VERSION "dbc-export 1 2025.20.8"

NS_ :

BS_:

BU_: BMS CC CMP CMPD CP DAS DI DIF DIR EPBL EPBR EVSE FC GTW HCML HCMR HVP ICR PCS PM PMF PMR PTC SCCM SDCR TAS UMC VC VCFRONT VCLEFT VCRIGHT VCSEC

BO_ 857 VCSEC_DeviceStatus: 8 VCSEC
 SG_ VCSEC_DeviceStatusIndex M : 0|7@1+ (1,0) [0|127] "" Vector__XXX
 SG_ VCSEC_Device0AuthResponseTime m0 : 7|7@1+ (50,0) [0|6300] "ms" Vector__XXX
 SG_ VCSEC_Device0Impermanent m0 : 14|1@1+ (1,0) [0|1] "" Vector__XXX
 SG_ VCSEC_Device0SELockedDown m0 : 15|1@1+ (1,0) [0|1] "" Vector__XXX
 SG_ VCSEC_Device0Version m0 : 16|16@1+ (1,0) [0|65535] "" Vector__XXX
 SG_ VCSEC_Device0WLEntry m0 : 32|5@1+ (1,0) [0|31] "" Vector__XXX
 SG_ VCSEC_Device0OSVersion m0 : 37|12@1+ (1,0) [0|4095] "" Vector__XXX
 SG_ VCSEC_Device0BatteryLevel m0 : 49|8@1+ (0.015625,0) [0|3.9] "V" Vector__XXX
 SG_ VCSEC_Device0Formfactor m0 : 57|5@1+ (1,0) [0|31] "" Vector__XXX
 SG_ VCSEC_Device0BlacklistStatus m0 : 62|1@1+ (1,0) [0|1] "" Vector__XXX
 SG_ VCSEC_Device0Stationary m0 : 63|1@1+ (1,0) [0|1] "" Vector__XXX
 SG_ VCSEC_Device0Bonded m2 : 8|1@1+ (1,0) [0|1] "" Vector__XXX
 SG_ VCSEC_Device0Role m2 : 9|4@1+ (1,0) [0|15] "" Vector__XXX
 SG_ VCSEC_Device0WhitelistActiveTime m2 : 16|16@1+ (1,0) [0|65535] "mins" Vector__XXX
 SG_ VCSEC_Device0SHA1 m2 : 32|32@1+ (1,0) [0|4294967295] "" Vector__XXX
 SG_ VCSEC_Device0Permissions m3 : 32|32@1+ (1,0) [0|4294967295] "" Vector__XXX
 SG_ VCSEC_Device0ManufacturerHashBit m5 : 8|24@1+ (1,0) [0|16777215] "" Vector__XXX
 SG_ VCSEC_Device0BuildNumberHashBits m5 : 32|32@1+ (1,0) [0|4294967295] "" Vector__XXX
 SG_ VCSEC_Device1AuthResponseTime m6 : 7|7@1+ (50,0) [0|6300] "ms" Vector__XXX
 SG_ VCSEC_Device1Impermanent m6 : 14|1@1+ (1,0) [0|1] "" Vector__XXX
 SG_ VCSEC_Device1SELockedDown m6 : 15|1@1+ (1,0) [0|1] "" Vector__XXX
 SG_ VCSEC_Device1Version m6 : 16|16@1+ (1,0) [0|65535] "" Vector__XXX
 SG_ VCSEC_Device1WLEntry m6 : 32|5@1+ (1,0) [0|31] "" Vector__XXX
 SG_ VCSEC_Device1OSVersion m6 : 37|12@1+ (1,0) [0|4095] "" Vector__XXX
 SG_ VCSEC_Device1BatteryLevel m6 : 49|8@1+ (0.015625,0) [0|3.9] "V" Vector__XXX
 SG_ VCSEC_Device1Formfactor m6 : 57|5@1+ (1,0) [0|31] "" Vector__XXX
 SG_ VCSEC_Device1BlacklistStatus m6 : 62|1@1+ (1,0) [0|1] "" Vector__XXX
 SG_ VCSEC_Device1Stationary m6 : 63|1@1+ (1,0) [0|1] "" Vector__XXX
 SG_ VCSEC_Device1Bonded m8 : 8|1@1+ (1,0) [0|1] "" Vector__XXX
 SG_ VCSEC_Device1Role m8 : 9|4@1+ (1,0) [0|15] "" Vector__XXX
 SG_ VCSEC_Device1WhitelistActiveTime m8 : 16|16@1+ (1,0) [0|65535] "mins" Vector__XXX
 SG_ VCSEC_Device1SHA1 m8 : 32|32@1+ (1,0) [0|4294967295] "" Vector__XXX
 SG_ VCSEC_Device1Permissions m9 : 32|32@1+ (1,0) [0|4294967295] "" Vector__XXX
 SG_ VCSEC_Device1ManufacturerHashBit m11 : 8|24@1+ (1,0) [0|16777215] "" Vector__XXX
 SG_ VCSEC_Device1BuildNumberHashBits m11 : 32|32@1+ (1,0) [0|4294967295] "" Vector__XXX
 SG_ VCSEC_Device2AuthResponseTime m12 : 7|7@1+ (50,0) [0|6300] "ms" Vector__XXX
 SG_ VCSEC_Device2Impermanent m12 : 14|1@1+ (1,0) [0|1] "" Vector__XXX
 SG_ VCSEC_Device2SELockedDown m12 : 15|1@1+ (1,0) [0|1] "" Vector__XXX
 SG_ VCSEC_Device2Version m12 : 16|16@1+ (1,0) [0|65535] "" Vector__XXX
 SG_ VCSEC_Device2WLEntry m12 : 32|5@1+ (1,0) [0|31] "" Vector__XXX
 SG_ VCSEC_Device2OSVersion m12 : 37|12@1+ (1,0) [0|4095] "" Vector__XXX
 SG_ VCSEC_Device2BatteryLevel m12 : 49|8@1+ (0.015625,0) [0|3.9] "V" Vector__XXX
 SG_ VCSEC_Device2Formfactor m12 : 57|5@1+ (1,0) [0|31] "" Vector__XXX
 SG_ VCSEC_Device2BlacklistStatus m12 : 62|1@1+ (1,0) [0|1] "" Vector__XXX
 SG_ VCSEC_Device2Stationary m12 : 63|1@1+ (1,0) [0|1] "" Vector__XXX
 SG_ VCSEC_Device2Bonded m14 : 8|1@1+ (1,0) [0|1] "" Vector__XXX
 SG_ VCSEC_Device2Role m14 : 9|4@1+ (1,0) [0|15] "" Vector__XXX
 SG_ VCSEC_Device2WhitelistActiveTime m14 : 16|16@1+ (1,0) [0|65535] "mins" Vector__XXX
 SG_ VCSEC_Device2SHA1 m14 : 32|32@1+ (1,0) [0|4294967295] "" Vector__XXX
 SG_ VCSEC_Device2Permissions m15 : 32|32@1+ (1,0) [0|4294967295] "" Vector__XXX
 SG_ VCSEC_Device2ManufacturerHashBit m17 : 8|24@1+ (1,0) [0|16777215] "" Vector__XXX
 SG_ VCSEC_Device2BuildNumberHashBits m17 : 32|32@1+ (1,0) [0|4294967295] "" Vector__XXX
 SG_ VCSEC_Device3AuthResponseTime m18 : 7|7@1+ (50,0) [0|6300] "ms" Vector__XXX
 SG_ VCSEC_Device3Impermanent m18 : 14|1@1+ (1,0) [0|1] "" Vector__XXX
 SG_ VCSEC_Device3SELockedDown m18 : 15|1@1+ (1,0) [0|1] "" Vector__XXX
 SG_ VCSEC_Device3Version m18 : 16|16@1+ (1,0) [0|65535] "" Vector__XXX
 SG_ VCSEC_Device3WLEntry m18 : 32|5@1+ (1,0) [0|31] "" Vector__XXX
 SG_ VCSEC_Device3OSVersion m18 : 37|12@1+ (1,0) [0|4095] "" Vector__XXX
 SG_ VCSEC_Device3BatteryLevel m18 : 49|8@1+ (0.015625,0) [0|3.9] "V" Vector__XXX
 SG_ VCSEC_Device3Formfactor m18 : 57|5@1+ (1,0) [0|31] "" Vector__XXX
 SG_ VCSEC_Device3BlacklistStatus m18 : 62|1@1+ (1,0) [0|1] "" Vector__XXX
 SG_ VCSEC_Device3Stationary m18 : 63|1@1+ (1,0) [0|1] "" Vector__XXX
 SG_ VCSEC_Device3Bonded m20 : 8|1@1+ (1,0) [0|1] "" Vector__XXX
 SG_ VCSEC_Device3Role m20 : 9|4@1+ (1,0) [0|15] "" Vector__XXX
 SG_ VCSEC_Device3WhitelistActiveTime m20 : 16|16@1+ (1,0) [0|65535] "mins" Vector__XXX
 SG_ VCSEC_Device3SHA1 m20 : 32|32@1+ (1,0) [0|4294967295] "" Vector__XXX
 SG_ VCSEC_Device3Permissions m21 : 32|32@1+ (1,0) [0|4294967295] "" Vector__XXX
 SG_ VCSEC_Device3ManufacturerHashBit m23 : 8|24@1+ (1,0) [0|16777215] "" Vector__XXX
 SG_ VCSEC_Device3BuildNumberHashBits m23 : 32|32@1+ (1,0) [0|4294967295] "" Vector__XXX
 SG_ VCSEC_Device4AuthResponseTime m24 : 7|7@1+ (50,0) [0|6300] "ms" Vector__XXX
 SG_ VCSEC_Device4Impermanent m24 : 14|1@1+ (1,0) [0|1] "" Vector__XXX
 SG_ VCSEC_Device4SELockedDown m24 : 15|1@1+ (1,0) [0|1] "" Vector__XXX
 SG_ VCSEC_Device4Version m24 : 16|16@1+ (1,0) [0|65535] "" Vector__XXX
 SG_ VCSEC_Device4WLEntry m24 : 32|5@1+ (1,0) [0|31] "" Vector__XXX
 SG_ VCSEC_Device4OSVersion m24 : 37|12@1+ (1,0) [0|4095] "" Vector__XXX
 SG_ VCSEC_Device4BatteryLevel m24 : 49|8@1+ (0.015625,0) [0|3.9] "V" Vector__XXX
 SG_ VCSEC_Device4Formfactor m24 : 57|5@1+ (1,0) [0|31] "" Vector__XXX
 SG_ VCSEC_Device4BlacklistStatus m24 : 62|1@1+ (1,0) [0|1] "" Vector__XXX
 SG_ VCSEC_Device4Stationary m24 : 63|1@1+ (1,0) [0|1] "" Vector__XXX
 SG_ VCSEC_Device4Bonded m26 : 8|1@1+ (1,0) [0|1] "" Vector__XXX
 SG_ VCSEC_Device4Role m26 : 9|4@1+ (1,0) [0|15] "" Vector__XXX
 SG_ VCSEC_Device4WhitelistActiveTime m26 : 16|16@1+ (1,0) [0|65535] "mins" Vector__XXX
 SG_ VCSEC_Device4SHA1 m26 : 32|32@1+ (1,0) [0|4294967295] "" Vector__XXX
 SG_ VCSEC_Device4Permissions m27 : 32|32@1+ (1,0) [0|4294967295] "" Vector__XXX
 SG_ VCSEC_Device4ManufacturerHashBit m29 : 8|24@1+ (1,0) [0|16777215] "" Vector__XXX
 SG_ VCSEC_Device4BuildNumberHashBits m29 : 32|32@1+ (1,0) [0|4294967295] "" Vector__XXX
 SG_ VCSEC_Device5AuthResponseTime m30 : 7|7@1+ (50,0) [0|6300] "ms" Vector__XXX
 SG_ VCSEC_Device5Impermanent m30 : 14|1@1+ (1,0) [0|1] "" Vector__XXX
 SG_ VCSEC_Device5SELockedDown m30 : 15|1@1+ (1,0) [0|1] "" Vector__XXX
 SG_ VCSEC_Device5Version m30 : 16|16@1+ (1,0) [0|65535] "" Vector__XXX
 SG_ VCSEC_Device5WLEntry m30 : 32|5@1+ (1,0) [0|31] "" Vector__XXX
 SG_ VCSEC_Device5OSVersion m30 : 37|12@1+ (1,0) [0|4095] "" Vector__XXX
 SG_ VCSEC_Device5BatteryLevel m30 : 49|8@1+ (0.015625,0) [0|3.9] "V" Vector__XXX
 SG_ VCSEC_Device5Formfactor m30 : 57|5@1+ (1,0) [0|31] "" Vector__XXX
 SG_ VCSEC_Device5BlacklistStatus m30 : 62|1@1+ (1,0) [0|1] "" Vector__XXX
 SG_ VCSEC_Device5Stationary m30 : 63|1@1+ (1,0) [0|1] "" Vector__XXX
 SG_ VCSEC_Device5Bonded m32 : 8|1@1+ (1,0) [0|1] "" Vector__XXX
 SG_ VCSEC_Device5Role m32 : 9|4@1+ (1,0) [0|15] "" Vector__XXX
 SG_ VCSEC_Device5WhitelistActiveTime m32 : 16|16@1+ (1,0) [0|65535] "mins" Vector__XXX
 SG_ VCSEC_Device5SHA1 m32 : 32|32@1+ (1,0) [0|4294967295] "" Vector__XXX
 SG_ VCSEC_Device5Permissions m33 : 32|32@1+ (1,0) [0|4294967295] "" Vector__XXX
 SG_ VCSEC_Device5ManufacturerHashBit m35 : 8|24@1+ (1,0) [0|16777215] "" Vector__XXX
 SG_ VCSEC_Device5BuildNumberHashBits m35 : 32|32@1+ (1,0) [0|4294967295] "" Vector__XXX
 SG_ VCSEC_Device6AuthResponseTime m36 : 7|7@1+ (50,0) [0|6300] "ms" Vector__XXX
 SG_ VCSEC_Device6Impermanent m36 : 14|1@1+ (1,0) [0|1] "" Vector__XXX
 SG_ VCSEC_Device6SELockedDown m36 : 15|1@1+ (1,0) [0|1] "" Vector__XXX
 SG_ VCSEC_Device6Version m36 : 16|16@1+ (1,0) [0|65535] "" Vector__XXX
 SG_ VCSEC_Device6WLEntry m36 : 32|5@1+ (1,0) [0|31] "" Vector__XXX
 SG_ VCSEC_Device6OSVersion m36 : 37|12@1+ (1,0) [0|4095] "" Vector__XXX
 SG_ VCSEC_Device6BatteryLevel m36 : 49|8@1+ (0.015625,0) [0|3.9] "V" Vector__XXX
 SG_ VCSEC_Device6Formfactor m36 : 57|5@1+ (1,0) [0|31] "" Vector__XXX
 SG_ VCSEC_Device6BlacklistStatus m36 : 62|1@1+ (1,0) [0|1] "" Vector__XXX
 SG_ VCSEC_Device6Stationary m36 : 63|1@1+ (1,0) [0|1] "" Vector__XXX
 SG_ VCSEC_Device6Bonded m38 : 8|1@1+ (1,0) [0|1] "" Vector__XXX
 SG_ VCSEC_Device6Role m38 : 9|4@1+ (1,0) [0|15] "" Vector__XXX
 SG_ VCSEC_Device6WhitelistActiveTime m38 : 16|16@1+ (1,0) [0|65535] "mins" Vector__XXX
 SG_ VCSEC_Device6SHA1 m38 : 32|32@1+ (1,0) [0|4294967295] "" Vector__XXX
 SG_ VCSEC_Device6Permissions m39 : 32|32@1+ (1,0) [0|4294967295] "" Vector__XXX
 SG_ VCSEC_Device6ManufacturerHashBit m41 : 8|24@1+ (1,0) [0|16777215] "" Vector__XXX
 SG_ VCSEC_Device6BuildNumberHashBits m41 : 32|32@1+ (1,0) [0|4294967295] "" Vector__XXX
 SG_ VCSEC_Device7AuthResponseTime m42 : 7|7@1+ (50,0) [0|6300] "ms" Vector__XXX
 SG_ VCSEC_Device7Impermanent m42 : 14|1@1+ (1,0) [0|1] "" Vector__XXX
 SG_ VCSEC_Device7SELockedDown m42 : 15|1@1+ (1,0) [0|1] "" Vector__XXX
 SG_ VCSEC_Device7Version m42 : 16|16@1+ (1,0) [0|65535] "" Vector__XXX
 SG_ VCSEC_Device7WLEntry m42 : 32|5@1+ (1,0) [0|31] "" Vector__XXX
 SG_ VCSEC_Device7OSVersion m42 : 37|12@1+ (1,0) [0|4095] "" Vector__XXX
 SG_ VCSEC_Device7BatteryLevel m42 : 49|8@1+ (0.015625,0) [0|3.9] "V" Vector__XXX
 SG_ VCSEC_Device7Formfactor m42 : 57|5@1+ (1,0) [0|31] "" Vector__XXX
 SG_ VCSEC_Device7BlacklistStatus m42 : 62|1@1+ (1,0) [0|1] "" Vector__XXX
 SG_ VCSEC_Device7Stationary m42 : 63|1@1+ (1,0) [0|1] "" Vector__XXX
 SG_ VCSEC_Device7Bonded m44 : 8|1@1+ (1,0) [0|1] "" Vector__XXX
 SG_ VCSEC_Device7Role m44 : 9|4@1+ (1,0) [0|15] "" Vector__XXX
 SG_ VCSEC_Device7WhitelistActiveTime m44 : 16|16@1+ (1,0) [0|65535] "mins" Vector__XXX
 SG_ VCSEC_Device7SHA1 m44 : 32|32@1+ (1,0) [0|4294967295] "" Vector__XXX
 SG_ VCSEC_Device7Permissions m45 : 32|32@1+ (1,0) [0|4294967295] "" Vector__XXX
 SG_ VCSEC_Device7ManufacturerHashBit m47 : 8|24@1+ (1,0) [0|16777215] "" Vector__XXX
 SG_ VCSEC_Device7BuildNumberHashBits m47 : 32|32@1+ (1,0) [0|4294967295] "" Vector__XXX
 SG_ VCSEC_Device8AuthResponseTime m48 : 7|7@1+ (50,0) [0|6300] "ms" Vector__XXX
 SG_ VCSEC_Device8Impermanent m48 : 14|1@1+ (1,0) [0|1] "" Vector__XXX
 SG_ VCSEC_Device8SELockedDown m48 : 15|1@1+ (1,0) [0|1] "" Vector__XXX
 SG_ VCSEC_Device8Version m48 : 16|16@1+ (1,0) [0|65535] "" Vector__XXX
 SG_ VCSEC_Device8WLEntry m48 : 32|5@1+ (1,0) [0|31] "" Vector__XXX
 SG_ VCSEC_Device8OSVersion m48 : 37|12@1+ (1,0) [0|4095] "" Vector__XXX
 SG_ VCSEC_Device8BatteryLevel m48 : 49|8@1+ (0.015625,0) [0|3.9] "V" Vector__XXX
 SG_ VCSEC_Device8Formfactor m48 : 57|5@1+ (1,0) [0|31] "" Vector__XXX
 SG_ VCSEC_Device8BlacklistStatus m48 : 62|1@1+ (1,0) [0|1] "" Vector__XXX
 SG_ VCSEC_Device8Stationary m48 : 63|1@1+ (1,0) [0|1] "" Vector__XXX
 SG_ VCSEC_Device8Bonded m50 : 8|1@1+ (1,0) [0|1] "" Vector__XXX
 SG_ VCSEC_Device8Role m50 : 9|4@1+ (1,0) [0|15] "" Vector__XXX
 SG_ VCSEC_Device8WhitelistActiveTime m50 : 16|16@1+ (1,0) [0|65535] "mins" Vector__XXX
 SG_ VCSEC_Device8SHA1 m50 : 32|32@1+ (1,0) [0|4294967295] "" Vector__XXX
 SG_ VCSEC_Device8Permissions m51 : 32|32@1+ (1,0) [0|4294967295] "" Vector__XXX
 SG_ VCSEC_Device8ManufacturerHashBit m53 : 8|24@1+ (1,0) [0|16777215] "" Vector__XXX
 SG_ VCSEC_Device8BuildNumberHashBits m53 : 32|32@1+ (1,0) [0|4294967295] "" Vector__XXX
 SG_ VCSEC_Device9AuthResponseTime m54 : 7|7@1+ (50,0) [0|6300] "ms" Vector__XXX
 SG_ VCSEC_Device9Impermanent m54 : 14|1@1+ (1,0) [0|1] "" Vector__XXX
 SG_ VCSEC_Device9SELockedDown m54 : 15|1@1+ (1,0) [0|1] "" Vector__XXX
 SG_ VCSEC_Device9Version m54 : 16|16@1+ (1,0) [0|65535] "" Vector__XXX
 SG_ VCSEC_Device9WLEntry m54 : 32|5@1+ (1,0) [0|31] "" Vector__XXX
 SG_ VCSEC_Device9OSVersion m54 : 37|12@1+ (1,0) [0|4095] "" Vector__XXX
 SG_ VCSEC_Device9BatteryLevel m54 : 49|8@1+ (0.015625,0) [0|3.9] "V" Vector__XXX
 SG_ VCSEC_Device9Formfactor m54 : 57|5@1+ (1,0) [0|31] "" Vector__XXX
 SG_ VCSEC_Device9BlacklistStatus m54 : 62|1@1+ (1,0) [0|1] "" Vector__XXX
 SG_ VCSEC_Device9Stationary m54 : 63|1@1+ (1,0) [0|1] "" Vector__XXX
 SG_ VCSEC_Device9Bonded m56 : 8|1@1+ (1,0) [0|1] "" Vector__XXX
 SG_ VCSEC_Device9Role m56 : 9|4@1+ (1,0) [0|15] "" Vector__XXX
 SG_ VCSEC_Device9WhitelistActiveTime m56 : 16|16@1+ (1,0) [0|65535] "mins" Vector__XXX
 SG_ VCSEC_Device9SHA1 m56 : 32|32@1+ (1,0) [0|4294967295] "" Vector__XXX
 SG_ VCSEC_Device9Permissions m57 : 32|32@1+ (1,0) [0|4294967295] "" Vector__XXX
 SG_ VCSEC_Device9ManufacturerHashBit m59 : 8|24@1+ (1,0) [0|16777215] "" Vector__XXX
 SG_ VCSEC_Device9BuildNumberHashBits m59 : 32|32@1+ (1,0) [0|4294967295] "" Vector__XXX
 SG_ VCSEC_Device10AuthResponseTime m60 : 7|7@1+ (50,0) [0|6300] "ms" Vector__XXX
 SG_ VCSEC_Device10Impermanent m60 : 14|1@1+ (1,0) [0|1] "" Vector__XXX
 SG_ VCSEC_Device10SELockedDown m60 : 15|1@1+ (1,0) [0|1] "" Vector__XXX
 SG_ VCSEC_Device10Version m60 : 16|16@1+ (1,0) [0|65535] "" Vector__XXX
 SG_ VCSEC_Device10WLEntry m60 : 32|5@1+ (1,0) [0|31] "" Vector__XXX
 SG_ VCSEC_Device10OSVersion m60 : 37|12@1+ (1,0) [0|4095] "" Vector__XXX
 SG_ VCSEC_Device10BatteryLevel m60 : 49|8@1+ (0.015625,0) [0|3.9] "V" Vector__XXX
 SG_ VCSEC_Device10Formfactor m60 : 57|5@1+ (1,0) [0|31] "" Vector__XXX
 SG_ VCSEC_Device10BlacklistStatus m60 : 62|1@1+ (1,0) [0|1] "" Vector__XXX
 SG_ VCSEC_Device10Stationary m60 : 63|1@1+ (1,0) [0|1] "" Vector__XXX
 SG_ VCSEC_Device10Bonded m62 : 8|1@1+ (1,0) [0|1] "" Vector__XXX
 SG_ VCSEC_Device10Role m62 : 9|4@1+ (1,0) [0|15] "" Vector__XXX
 SG_ VCSEC_Device10WhitelistActiveTim m62 : 16|16@1+ (1,0) [0|65535] "mins" Vector__XXX
 SG_ VCSEC_Device10SHA1 m62 : 32|32@1+ (1,0) [0|4294967295] "" Vector__XXX
 SG_ VCSEC_Device10Permissions m63 : 32|32@1+ (1,0) [0|4294967295] "" Vector__XXX
 SG_ VCSEC_Device10ManufacturerHashBi m65 : 8|24@1+ (1,0) [0|16777215] "" Vector__XXX
 SG_ VCSEC_Device10BuildNumberHashBit m65 : 32|32@1+ (1,0) [0|4294967295] "" Vector__XXX
 SG_ VCSEC_Device11AuthResponseTime m66 : 7|7@1+ (50,0) [0|6300] "ms" Vector__XXX
 SG_ VCSEC_Device11Impermanent m66 : 14|1@1+ (1,0) [0|1] "" Vector__XXX
 SG_ VCSEC_Device11SELockedDown m66 : 15|1@1+ (1,0) [0|1] "" Vector__XXX
 SG_ VCSEC_Device11Version m66 : 16|16@1+ (1,0) [0|65535] "" Vector__XXX
 SG_ VCSEC_Device11WLEntry m66 : 32|5@1+ (1,0) [0|31] "" Vector__XXX
 SG_ VCSEC_Device11OSVersion m66 : 37|12@1+ (1,0) [0|4095] "" Vector__XXX
 SG_ VCSEC_Device11BatteryLevel m66 : 49|8@1+ (0.015625,0) [0|3.9] "V" Vector__XXX
 SG_ VCSEC_Device11Formfactor m66 : 57|5@1+ (1,0) [0|31] "" Vector__XXX
 SG_ VCSEC_Device11BlacklistStatus m66 : 62|1@1+ (1,0) [0|1] "" Vector__XXX
 SG_ VCSEC_Device11Stationary m66 : 63|1@1+ (1,0) [0|1] "" Vector__XXX
 SG_ VCSEC_Device11Bonded m68 : 8|1@1+ (1,0) [0|1] "" Vector__XXX
 SG_ VCSEC_Device11Role m68 : 9|4@1+ (1,0) [0|15] "" Vector__XXX
 SG_ VCSEC_Device11WhitelistActiveTim m68 : 16|16@1+ (1,0) [0|65535] "mins" Vector__XXX
 SG_ VCSEC_Device11SHA1 m68 : 32|32@1+ (1,0) [0|4294967295] "" Vector__XXX
 SG_ VCSEC_Device11Permissions m69 : 32|32@1+ (1,0) [0|4294967295] "" Vector__XXX
 SG_ VCSEC_Device11ManufacturerHashBi m71 : 8|24@1+ (1,0) [0|16777215] "" Vector__XXX
 SG_ VCSEC_Device11BuildNumberHashBit m71 : 32|32@1+ (1,0) [0|4294967295] "" Vector__XXX
 SG_ VCSEC_Device12AuthResponseTime m72 : 7|7@1+ (50,0) [0|6300] "ms" Vector__XXX
 SG_ VCSEC_Device12Impermanent m72 : 14|1@1+ (1,0) [0|1] "" Vector__XXX
 SG_ VCSEC_Device12SELockedDown m72 : 15|1@1+ (1,0) [0|1] "" Vector__XXX
 SG_ VCSEC_Device12Version m72 : 16|16@1+ (1,0) [0|65535] "" Vector__XXX
 SG_ VCSEC_Device12WLEntry m72 : 32|5@1+ (1,0) [0|31] "" Vector__XXX
 SG_ VCSEC_Device12OSVersion m72 : 37|12@1+ (1,0) [0|4095] "" Vector__XXX
 SG_ VCSEC_Device12BatteryLevel m72 : 49|8@1+ (0.015625,0) [0|3.9] "V" Vector__XXX
 SG_ VCSEC_Device12Formfactor m72 : 57|5@1+ (1,0) [0|31] "" Vector__XXX
 SG_ VCSEC_Device12BlacklistStatus m72 : 62|1@1+ (1,0) [0|1] "" Vector__XXX
 SG_ VCSEC_Device12Stationary m72 : 63|1@1+ (1,0) [0|1] "" Vector__XXX
 SG_ VCSEC_Device12Bonded m74 : 8|1@1+ (1,0) [0|1] "" Vector__XXX
 SG_ VCSEC_Device12Role m74 : 9|4@1+ (1,0) [0|15] "" Vector__XXX
 SG_ VCSEC_Device12WhitelistActiveTim m74 : 16|16@1+ (1,0) [0|65535] "mins" Vector__XXX
 SG_ VCSEC_Device12SHA1 m74 : 32|32@1+ (1,0) [0|4294967295] "" Vector__XXX
 SG_ VCSEC_Device12Permissions m75 : 32|32@1+ (1,0) [0|4294967295] "" Vector__XXX
 SG_ VCSEC_Device12ManufacturerHashBi m77 : 8|24@1+ (1,0) [0|16777215] "" Vector__XXX
 SG_ VCSEC_Device12BuildNumberHashBit m77 : 32|32@1+ (1,0) [0|4294967295] "" Vector__XXX
 SG_ VCSEC_Device13AuthResponseTime m78 : 7|7@1+ (50,0) [0|6300] "ms" Vector__XXX
 SG_ VCSEC_Device13Impermanent m78 : 14|1@1+ (1,0) [0|1] "" Vector__XXX
 SG_ VCSEC_Device13SELockedDown m78 : 15|1@1+ (1,0) [0|1] "" Vector__XXX
 SG_ VCSEC_Device13Version m78 : 16|16@1+ (1,0) [0|65535] "" Vector__XXX
 SG_ VCSEC_Device13WLEntry m78 : 32|5@1+ (1,0) [0|31] "" Vector__XXX
 SG_ VCSEC_Device13OSVersion m78 : 37|12@1+ (1,0) [0|4095] "" Vector__XXX
 SG_ VCSEC_Device13BatteryLevel m78 : 49|8@1+ (0.015625,0) [0|3.9] "V" Vector__XXX
 SG_ VCSEC_Device13Formfactor m78 : 57|5@1+ (1,0) [0|31] "" Vector__XXX
 SG_ VCSEC_Device13BlacklistStatus m78 : 62|1@1+ (1,0) [0|1] "" Vector__XXX
 SG_ VCSEC_Device13Stationary m78 : 63|1@1+ (1,0) [0|1] "" Vector__XXX
 SG_ VCSEC_Device13Bonded m80 : 8|1@1+ (1,0) [0|1] "" Vector__XXX
 SG_ VCSEC_Device13Role m80 : 9|4@1+ (1,0) [0|15] "" Vector__XXX
 SG_ VCSEC_Device13WhitelistActiveTim m80 : 16|16@1+ (1,0) [0|65535] "mins" Vector__XXX
 SG_ VCSEC_Device13SHA1 m80 : 32|32@1+ (1,0) [0|4294967295] "" Vector__XXX
 SG_ VCSEC_Device13Permissions m81 : 32|32@1+ (1,0) [0|4294967295] "" Vector__XXX
 SG_ VCSEC_Device13ManufacturerHashBi m83 : 8|24@1+ (1,0) [0|16777215] "" Vector__XXX
 SG_ VCSEC_Device13BuildNumberHashBit m83 : 32|32@1+ (1,0) [0|4294967295] "" Vector__XXX
 SG_ VCSEC_Device14AuthResponseTime m84 : 7|7@1+ (50,0) [0|6300] "ms" Vector__XXX
 SG_ VCSEC_Device14Impermanent m84 : 14|1@1+ (1,0) [0|1] "" Vector__XXX
 SG_ VCSEC_Device14SELockedDown m84 : 15|1@1+ (1,0) [0|1] "" Vector__XXX
 SG_ VCSEC_Device14Version m84 : 16|16@1+ (1,0) [0|65535] "" Vector__XXX
 SG_ VCSEC_Device14WLEntry m84 : 32|5@1+ (1,0) [0|31] "" Vector__XXX
 SG_ VCSEC_Device14OSVersion m84 : 37|12@1+ (1,0) [0|4095] "" Vector__XXX
 SG_ VCSEC_Device14BatteryLevel m84 : 49|8@1+ (0.015625,0) [0|3.9] "V" Vector__XXX
 SG_ VCSEC_Device14Formfactor m84 : 57|5@1+ (1,0) [0|31] "" Vector__XXX
 SG_ VCSEC_Device14BlacklistStatus m84 : 62|1@1+ (1,0) [0|1] "" Vector__XXX
 SG_ VCSEC_Device14Stationary m84 : 63|1@1+ (1,0) [0|1] "" Vector__XXX
 SG_ VCSEC_Device14Bonded m86 : 8|1@1+ (1,0) [0|1] "" Vector__XXX
 SG_ VCSEC_Device14Role m86 : 9|4@1+ (1,0) [0|15] "" Vector__XXX
 SG_ VCSEC_Device14WhitelistActiveTim m86 : 16|16@1+ (1,0) [0|65535] "mins" Vector__XXX
 SG_ VCSEC_Device14SHA1 m86 : 32|32@1+ (1,0) [0|4294967295] "" Vector__XXX
 SG_ VCSEC_Device14Permissions m87 : 32|32@1+ (1,0) [0|4294967295] "" Vector__XXX
 SG_ VCSEC_Device14ManufacturerHashBi m89 : 8|24@1+ (1,0) [0|16777215] "" Vector__XXX
 SG_ VCSEC_Device14BuildNumberHashBit m89 : 32|32@1+ (1,0) [0|4294967295] "" Vector__XXX
 SG_ VCSEC_Device15AuthResponseTime m90 : 7|7@1+ (50,0) [0|6300] "ms" Vector__XXX
 SG_ VCSEC_Device15Impermanent m90 : 14|1@1+ (1,0) [0|1] "" Vector__XXX
 SG_ VCSEC_Device15SELockedDown m90 : 15|1@1+ (1,0) [0|1] "" Vector__XXX
 SG_ VCSEC_Device15Version m90 : 16|16@1+ (1,0) [0|65535] "" Vector__XXX
 SG_ VCSEC_Device15WLEntry m90 : 32|5@1+ (1,0) [0|31] "" Vector__XXX
 SG_ VCSEC_Device15OSVersion m90 : 37|12@1+ (1,0) [0|4095] "" Vector__XXX
 SG_ VCSEC_Device15BatteryLevel m90 : 49|8@1+ (0.015625,0) [0|3.9] "V" Vector__XXX
 SG_ VCSEC_Device15Formfactor m90 : 57|5@1+ (1,0) [0|31] "" Vector__XXX
 SG_ VCSEC_Device15BlacklistStatus m90 : 62|1@1+ (1,0) [0|1] "" Vector__XXX
 SG_ VCSEC_Device15Stationary m90 : 63|1@1+ (1,0) [0|1] "" Vector__XXX
 SG_ VCSEC_Device15Bonded m92 : 8|1@1+ (1,0) [0|1] "" Vector__XXX
 SG_ VCSEC_Device15Role m92 : 9|4@1+ (1,0) [0|15] "" Vector__XXX
 SG_ VCSEC_Device15WhitelistActiveTim m92 : 16|16@1+ (1,0) [0|65535] "mins" Vector__XXX
 SG_ VCSEC_Device15SHA1 m92 : 32|32@1+ (1,0) [0|4294967295] "" Vector__XXX
 SG_ VCSEC_Device15Permissions m93 : 32|32@1+ (1,0) [0|4294967295] "" Vector__XXX
 SG_ VCSEC_Device15ManufacturerHashBi m95 : 8|24@1+ (1,0) [0|16777215] "" Vector__XXX
 SG_ VCSEC_Device15BuildNumberHashBit m95 : 32|32@1+ (1,0) [0|4294967295] "" Vector__XXX
 SG_ VCSEC_Device16AuthResponseTime m96 : 7|7@1+ (50,0) [0|6300] "ms" Vector__XXX
 SG_ VCSEC_Device16Impermanent m96 : 14|1@1+ (1,0) [0|1] "" Vector__XXX
 SG_ VCSEC_Device16SELockedDown m96 : 15|1@1+ (1,0) [0|1] "" Vector__XXX
 SG_ VCSEC_Device16Version m96 : 16|16@1+ (1,0) [0|65535] "" Vector__XXX
 SG_ VCSEC_Device16WLEntry m96 : 32|5@1+ (1,0) [0|31] "" Vector__XXX
 SG_ VCSEC_Device16OSVersion m96 : 37|12@1+ (1,0) [0|4095] "" Vector__XXX
 SG_ VCSEC_Device16BatteryLevel m96 : 49|8@1+ (0.015625,0) [0|3.9] "V" Vector__XXX
 SG_ VCSEC_Device16Formfactor m96 : 57|5@1+ (1,0) [0|31] "" Vector__XXX
 SG_ VCSEC_Device16BlacklistStatus m96 : 62|1@1+ (1,0) [0|1] "" Vector__XXX
 SG_ VCSEC_Device16Stationary m96 : 63|1@1+ (1,0) [0|1] "" Vector__XXX
 SG_ VCSEC_Device16Bonded m98 : 8|1@1+ (1,0) [0|1] "" Vector__XXX
 SG_ VCSEC_Device16Role m98 : 9|4@1+ (1,0) [0|15] "" Vector__XXX
 SG_ VCSEC_Device16WhitelistActiveTim m98 : 16|16@1+ (1,0) [0|65535] "mins" Vector__XXX
 SG_ VCSEC_Device16SHA1 m98 : 32|32@1+ (1,0) [0|4294967295] "" Vector__XXX
 SG_ VCSEC_Device16Permissions m99 : 32|32@1+ (1,0) [0|4294967295] "" Vector__XXX
 SG_ VCSEC_Device16ManufacturerHashBi m101 : 8|24@1+ (1,0) [0|16777215] "" Vector__XXX
 SG_ VCSEC_Device16BuildNumberHashBit m101 : 32|32@1+ (1,0) [0|4294967295] "" Vector__XXX
 SG_ VCSEC_Device17AuthResponseTime m102 : 7|7@1+ (50,0) [0|6300] "ms" Vector__XXX
 SG_ VCSEC_Device17Impermanent m102 : 14|1@1+ (1,0) [0|1] "" Vector__XXX
 SG_ VCSEC_Device17SELockedDown m102 : 15|1@1+ (1,0) [0|1] "" Vector__XXX
 SG_ VCSEC_Device17Version m102 : 16|16@1+ (1,0) [0|65535] "" Vector__XXX
 SG_ VCSEC_Device17WLEntry m102 : 32|5@1+ (1,0) [0|31] "" Vector__XXX
 SG_ VCSEC_Device17OSVersion m102 : 37|12@1+ (1,0) [0|4095] "" Vector__XXX
 SG_ VCSEC_Device17BatteryLevel m102 : 49|8@1+ (0.015625,0) [0|3.9] "V" Vector__XXX
 SG_ VCSEC_Device17Formfactor m102 : 57|5@1+ (1,0) [0|31] "" Vector__XXX
 SG_ VCSEC_Device17BlacklistStatus m102 : 62|1@1+ (1,0) [0|1] "" Vector__XXX
 SG_ VCSEC_Device17Stationary m102 : 63|1@1+ (1,0) [0|1] "" Vector__XXX
 SG_ VCSEC_Device17Bonded m104 : 8|1@1+ (1,0) [0|1] "" Vector__XXX
 SG_ VCSEC_Device17Role m104 : 9|4@1+ (1,0) [0|15] "" Vector__XXX
 SG_ VCSEC_Device17WhitelistActiveTim m104 : 16|16@1+ (1,0) [0|65535] "mins" Vector__XXX
 SG_ VCSEC_Device17SHA1 m104 : 32|32@1+ (1,0) [0|4294967295] "" Vector__XXX
 SG_ VCSEC_Device17Permissions m105 : 32|32@1+ (1,0) [0|4294967295] "" Vector__XXX
 SG_ VCSEC_Device17ManufacturerHashBi m107 : 8|24@1+ (1,0) [0|16777215] "" Vector__XXX
 SG_ VCSEC_Device17BuildNumberHashBit m107 : 32|32@1+ (1,0) [0|4294967295] "" Vector__XXX
 SG_ VCSEC_Device18AuthResponseTime m108 : 7|7@1+ (50,0) [0|6300] "ms" Vector__XXX
 SG_ VCSEC_Device18Impermanent m108 : 14|1@1+ (1,0) [0|1] "" Vector__XXX
 SG_ VCSEC_Device18SELockedDown m108 : 15|1@1+ (1,0) [0|1] "" Vector__XXX
 SG_ VCSEC_Device18Version m108 : 16|16@1+ (1,0) [0|65535] "" Vector__XXX
 SG_ VCSEC_Device18WLEntry m108 : 32|5@1+ (1,0) [0|31] "" Vector__XXX
 SG_ VCSEC_Device18OSVersion m108 : 37|12@1+ (1,0) [0|4095] "" Vector__XXX
 SG_ VCSEC_Device18BatteryLevel m108 : 49|8@1+ (0.015625,0) [0|3.9] "V" Vector__XXX
 SG_ VCSEC_Device18Formfactor m108 : 57|5@1+ (1,0) [0|31] "" Vector__XXX
 SG_ VCSEC_Device18BlacklistStatus m108 : 62|1@1+ (1,0) [0|1] "" Vector__XXX
 SG_ VCSEC_Device18Stationary m108 : 63|1@1+ (1,0) [0|1] "" Vector__XXX
 SG_ VCSEC_Device18Bonded m110 : 8|1@1+ (1,0) [0|1] "" Vector__XXX
 SG_ VCSEC_Device18Role m110 : 9|4@1+ (1,0) [0|15] "" Vector__XXX
 SG_ VCSEC_Device18WhitelistActiveTim m110 : 16|16@1+ (1,0) [0|65535] "mins" Vector__XXX
 SG_ VCSEC_Device18SHA1 m110 : 32|32@1+ (1,0) [0|4294967295] "" Vector__XXX
 SG_ VCSEC_Device18Permissions m111 : 32|32@1+ (1,0) [0|4294967295] "" Vector__XXX
 SG_ VCSEC_Device18ManufacturerHashBi m113 : 8|24@1+ (1,0) [0|16777215] "" Vector__XXX
 SG_ VCSEC_Device18BuildNumberHashBit m113 : 32|32@1+ (1,0) [0|4294967295] "" Vector__XXX
 SG_ VCSEC_Device19AuthResponseTime m114 : 7|7@1+ (50,0) [0|6300] "ms" Vector__XXX
 SG_ VCSEC_Device19Impermanent m114 : 14|1@1+ (1,0) [0|1] "" Vector__XXX
 SG_ VCSEC_Device19SELockedDown m114 : 15|1@1+ (1,0) [0|1] "" Vector__XXX
 SG_ VCSEC_Device19Version m114 : 16|16@1+ (1,0) [0|65535] "" Vector__XXX
 SG_ VCSEC_Device19WLEntry m114 : 32|5@1+ (1,0) [0|31] "" Vector__XXX
 SG_ VCSEC_Device19OSVersion m114 : 37|12@1+ (1,0) [0|4095] "" Vector__XXX
 SG_ VCSEC_Device19BatteryLevel m114 : 49|8@1+ (0.015625,0) [0|3.9] "V" Vector__XXX
 SG_ VCSEC_Device19Formfactor m114 : 57|5@1+ (1,0) [0|31] "" Vector__XXX
 SG_ VCSEC_Device19BlacklistStatus m114 : 62|1@1+ (1,0) [0|1] "" Vector__XXX
 SG_ VCSEC_Device19Stationary m114 : 63|1@1+ (1,0) [0|1] "" Vector__XXX
 SG_ VCSEC_Device19Bonded m116 : 8|1@1+ (1,0) [0|1] "" Vector__XXX
 SG_ VCSEC_Device19Role m116 : 9|4@1+ (1,0) [0|15] "" Vector__XXX
 SG_ VCSEC_Device19WhitelistActiveTim m116 : 16|16@1+ (1,0) [0|65535] "mins" Vector__XXX
 SG_ VCSEC_Device19SHA1 m116 : 32|32@1+ (1,0) [0|4294967295] "" Vector__XXX
 SG_ VCSEC_Device19Permissions m117 : 32|32@1+ (1,0) [0|4294967295] "" Vector__XXX
 SG_ VCSEC_Device19ManufacturerHashBi m119 : 8|24@1+ (1,0) [0|16777215] "" Vector__XXX
 SG_ VCSEC_Device19BuildNumberHashBit m119 : 32|32@1+ (1,0) [0|4294967295] "" Vector__XXX

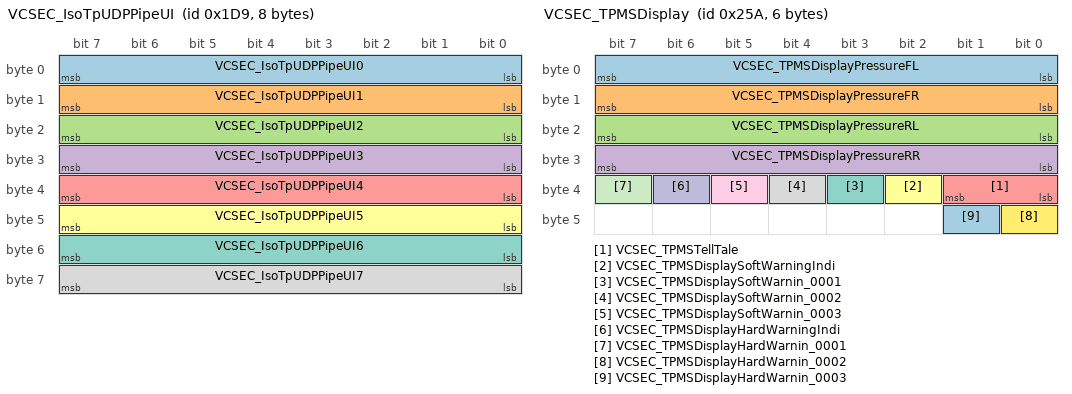
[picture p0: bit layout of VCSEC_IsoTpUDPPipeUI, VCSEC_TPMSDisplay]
BO_ 473 VCSEC_IsoTpUDPPipeUI: 8 VCSEC
 SG_ VCSEC_IsoTpUDPPipeUI0 : 0|8@1+ (1,0) [0|255] "" Vector__XXX
 SG_ VCSEC_IsoTpUDPPipeUI1 : 8|8@1+ (1,0) [0|255] "" Vector__XXX
 SG_ VCSEC_IsoTpUDPPipeUI2 : 16|8@1+ (1,0) [0|255] "" Vector__XXX
 SG_ VCSEC_IsoTpUDPPipeUI3 : 24|8@1+ (1,0) [0|255] "" Vector__XXX
 SG_ VCSEC_IsoTpUDPPipeUI4 : 32|8@1+ (1,0) [0|255] "" Vector__XXX
 SG_ VCSEC_IsoTpUDPPipeUI5 : 40|8@1+ (1,0) [0|255] "" Vector__XXX
 SG_ VCSEC_IsoTpUDPPipeUI6 : 48|8@1+ (1,0) [0|255] "" Vector__XXX
 SG_ VCSEC_IsoTpUDPPipeUI7 : 56|8@1+ (1,0) [0|255] "" Vector__XXX

BO_ 1066 VCSEC_TPMSConnectionData: 8 VCSEC
 SG_ VCSEC_TPMSSensorState0 : 0|3@1+ (1,0) [0|7] "" Vector__XXX
 SG_ VCSEC_TPMSRSSI0 : 3|7@1+ (1,-127) [-127|0] "dBm" Vector__XXX
 SG_ VCSEC_TPMSConnectionTypeCurrent0 : 10|2@1+ (1,0) [0|3] "" Vector__XXX
 SG_ VCSEC_TPMSConnectionTypeDesired0 : 12|2@1+ (1,0) [0|3] "" Vector__XXX
 SG_ VCSEC_TPMSSensorState1 : 14|3@1+ (1,0) [0|7] "" Vector__XXX
 SG_ VCSEC_TPMSRSSI1 : 17|7@1+ (1,-127) [-127|0] "dBm" Vector__XXX
 SG_ VCSEC_TPMSConnectionTypeCurrent1 : 24|2@1+ (1,0) [0|3] "" Vector__XXX
 SG_ VCSEC_TPMSConnectionTypeDesired1 : 26|2@1+ (1,0) [0|3] "" Vector__XXX
 SG_ VCSEC_TPMSSensorState2 : 28|3@1+ (1,0) [0|7] "" Vector__XXX
 SG_ VCSEC_TPMSRSSI2 : 31|7@1+ (1,-127) [-127|0] "dBm" Vector__XXX
 SG_ VCSEC_TPMSConnectionTypeCurrent2 : 38|2@1+ (1,0) [0|3] "" Vector__XXX
 SG_ VCSEC_TPMSConnectionTypeDesired2 : 40|2@1+ (1,0) [0|3] "" Vector__XXX
 SG_ VCSEC_TPMSSensorState3 : 42|3@1+ (1,0) [0|7] "" Vector__XXX
 SG_ VCSEC_TPMSRSSI3 : 45|7@1+ (1,-127) [-127|0] "dBm" Vector__XXX
 SG_ VCSEC_TPMSConnectionTypeCurrent3 : 52|2@1+ (1,0) [0|3] "" Vector__XXX
 SG_ VCSEC_TPMSConnectionTypeDesired3 : 54|2@1+ (1,0) [0|3] "" Vector__XXX
 SG_ VCSEC_TPMSSensorPresence0 : 56|2@1+ (1,0) [0|3] "" Vector__XXX
 SG_ VCSEC_TPMSSensorPresence1 : 58|2@1+ (1,0) [0|3] "" Vector__XXX
 SG_ VCSEC_TPMSSensorPresence2 : 60|2@1+ (1,0) [0|3] "" Vector__XXX
 SG_ VCSEC_TPMSSensorPresence3 : 62|2@1+ (1,0) [0|3] "" Vector__XXX

BO_ 602 VCSEC_TPMSDisplay: 6 VCSEC
 SG_ VCSEC_TPMSDisplayPressureFL : 0|8@1+ (0.025,0) [0|6.35] "bar" Vector__XXX
 SG_ VCSEC_TPMSDisplayPressureFR : 8|8@1+ (0.025,0) [0|6.35] "bar" Vector__XXX
 SG_ VCSEC_TPMSDisplayPressureRL : 16|8@1+ (0.025,0) [0|6.35] "bar" Vector__XXX
 SG_ VCSEC_TPMSDisplayPressureRR : 24|8@1+ (0.025,0) [0|6.35] "bar" Vector__XXX
 SG_ VCSEC_TPMSTellTale : 32|2@1+ (1,0) [0|3] "" Vector__XXX
 SG_ VCSEC_TPMSDisplaySoftWarningIndi : 34|1@1+ (1,0) [0|1] "" Vector__XXX
 SG_ VCSEC_TPMSDisplaySoftWarnin_0001 : 35|1@1+ (1,0) [0|1] "" Vector__XXX
 SG_ VCSEC_TPMSDisplaySoftWarnin_0002 : 36|1@1+ (1,0) [0|1] "" Vector__XXX
 SG_ VCSEC_TPMSDisplaySoftWarnin_0003 : 37|1@1+ (1,0) [0|1] "" Vector__XXX
 SG_ VCSEC_TPMSDisplayHardWarningIndi : 38|1@1+ (1,0) [0|1] "" Vector__XXX
 SG_ VCSEC_TPMSDisplayHardWarnin_0001 : 39|1@1+ (1,0) [0|1] "" Vector__XXX
 SG_ VCSEC_TPMSDisplayHardWarnin_0002 : 40|1@1+ (1,0) [0|1] "" Vector__XXX
 SG_ VCSEC_TPMSDisplayHardWarnin_0003 : 41|1@1+ (1,0) [0|1] "" Vector__XXX

BO_ 825 VCSEC_authentication: 8 VCSEC
 SG_ VCSEC_BLEConnectionCounter : 0|4@1+ (1,0) [0|15] "" Vector__XXX
 SG_ VCSEC_authRejectionReason : 4|3@1+ (1,0) [0|7] "" Vector__XXX
 SG_ VCSEC_IDRequested : 7|1@1+ (1,0) [0|1] "" Vector__XXX
 SG_ VCSEC_operationMode : 8|2@1+ (1,0) [0|3] "" Vector__XXX
 SG_ VCSEC_vehicleLockStatus : 12|4@1+ (1,0) [1|15] "" Vector__XXX
 SG_ VCSEC_authenticationStatus : 16|2@1+ (1,0) [0|3] "" Vector__XXX
 SG_ VCSEC_chargePortLockStatus : 18|1@1+ (1,0) [0|1] "" Vector__XXX
 SG_ VCSEC_leftFrontLockStatus : 19|1@1+ (1,0) [0|1] "" Vector__XXX
 SG_ VCSEC_leftRearLockStatus : 20|1@1+ (1,0) [0|1] "" Vector__XXX
 SG_ VCSEC_rightFrontLockStatus : 21|1@1+ (1,0) [0|1] "" Vector__XXX
 SG_ VCSEC_rightRearLockStatus : 22|1@1+ (1,0) [0|1] "" Vector__XXX
 SG_ VCSEC_trunkLockStatus : 23|1@1+ (1,0) [0|1] "" Vector__XXX
 SG_ VCSEC_lockRequestType : 24|5@1+ (1,0) [0|31] "" Vector__XXX
 SG_ VCSEC_summonRequest : 29|3@1+ (1,0) [0|7] "" Vector__XXX
 SG_ VCSEC_3rdPartyPLGRequest : 32|2@1+ (1,0) [0|2] "" Vector__XXX
 SG_ VCSEC_3rdPartyFrunkPLGRequest : 34|2@1+ (1,0) [0|2] "" Vector__XXX
 SG_ VCSEC_MCUCommandType : 36|3@1+ (1,0) [0|7] "" Vector__XXX
 SG_ VCSEC_frunkLockStatus : 39|1@1+ (1,0) [0|1] "" Vector__XXX
 SG_ VCSEC_usingModifiedMACAddress : 40|1@1+ (1,0) [0|1] "" Vector__XXX
 SG_ VCSEC_isKeyWithinSummonRange : 41|1@1+ (1,0) [0|1] "" Vector__XXX
 SG_ VCSEC_isBLEDeviceWithinSummonRan : 42|1@1+ (1,0) [0|1] "" Vector__XXX
 SG_ VCSEC_alarmStatus : 43|4@1+ (1,0) [0|14] "" Vector__XXX
 SG_ VCSEC_serviceDiagnosticRequest : 47|1@1+ (1,0) [0|1] "" Vector__XXX
 SG_ VCSEC_immobilizerState : 48|3@1+ (1,0) [0|7] "" Vector__XXX
 SG_ VCSEC_lockIndicationRequest : 51|3@1+ (1,0) [1|7] "" Vector__XXX
 SG_ VCSEC_simpleLockStatus : 54|2@1+ (1,0) [1|3] "" Vector__XXX
 SG_ VCSEC_keyChannelIndexed : 56|4@1+ (1,0) [0|14] "" Vector__XXX
 SG_ VCSEC_authRequested : 60|1@1+ (1,0) [0|1] "" Vector__XXX
 SG_ VCSEC_remoteStartActive : 61|2@1+ (1,0) [0|3] "" Vector__XXX
 SG_ VCSEC_keyPairDesired : 63|1@1+ (1,0) [0|1] "" Vector__XXX

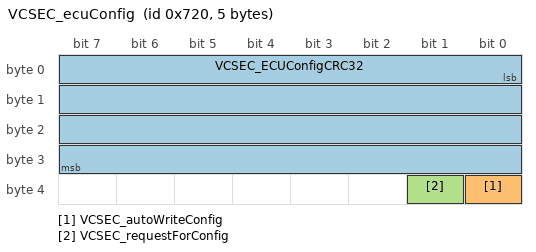
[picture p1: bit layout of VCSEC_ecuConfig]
BO_ 1824 VCSEC_ecuConfig: 5 VCSEC
 SG_ VCSEC_ECUConfigCRC32 : 0|32@1+ (1,0) [0|4294967295] "" Vector__XXX
 SG_ VCSEC_autoWriteConfig : 32|1@1+ (1,0) [0|1] "" Vector__XXX
 SG_ VCSEC_requestForConfig : 33|1@1+ (1,0) [0|1] "" Vector__XXX

BO_ 793 VCSEC_info: 8 VCSEC
 SG_ VCSEC_infoIndex M : 0|8@1+ (1,0) [0|255] "" Vector__XXX
 SG_ VCSEC_infoBuildType m10 : 8|3@1+ (1,0) [0|7] "" Vector__XXX
 SG_ VCSEC_infoBuildConfigId m10 : 16|16@1+ (1,0) [0|65535] "" Vector__XXX
 SG_ VCSEC_infoHardwareId m10 : 32|16@1+ (1,0) [0|65535] "" Vector__XXX
 SG_ VCSEC_infoComponentId m10 : 48|16@1+ (1,0) [0|65535] "" Vector__XXX
 SG_ VCSEC_infoPcbaId m11 : 8|8@1+ (1,0) [0|255] "" Vector__XXX
 SG_ VCSEC_infoAssemblyId m11 : 16|8@1+ (1,0) [0|254] "" Vector__XXX
 SG_ VCSEC_infoUsageId m11 : 32|16@1+ (1,0) [0|65535] "" Vector__XXX
 SG_ VCSEC_infoSubUsageId m11 : 48|16@1+ (1,0) [0|65535] "" Vector__XXX
 SG_ VCSEC_infoAppCrc m13 : 32|32@1+ (1,0) [0|4294967295] "" Vector__XXX
 SG_ VCSEC_infoSubcomponent1 m16 : 32|32@1+ (1,0) [0|4294967295] "" Vector__XXX
 SG_ VCSEC_infoAppGitHash m17 : 8|56@1+ (1,0) [0|7.20575940379e+16] "" Vector__XXX
 SG_ VCSEC_infoBootGitHash m18 : 8|56@1+ (1,0) [0|7.20575940379e+16] "" Vector__XXX
 SG_ VCSEC_infoPlatformType m19 : 8|8@1+ (1,0) [0|255] "" Vector__XXX
 SG_ VCSEC_infoBootUdsProtoVersion m20 : 8|16@1+ (1,0) [0|65535] "" Vector__XXX
 SG_ VCSEC_infoBootCrc m20 : 24|32@1+ (1,0) [0|4294967295] "" Vector__XXX
 SG_ VCSEC_infoSubcomponent2 m23 : 32|32@1+ (1,0) [0|4294967295] "" Vector__XXX
 SG_ VCSEC_infoSubcomponent3 m24 : 32|32@1+ (1,0) [0|4294967295] "" Vector__XXX
 SG_ VCSEC_infoSubcomponent4 m31 : 32|32@1+ (1,0) [0|4294967295] "" Vector__XXX

BO_ 505 VCSEC_requests: 8 VCSEC
 SG_ VCSEC_chargePortRequest : 0|2@1+ (1,0) [0|2] "" Vector__XXX
 SG_ VCSEC_presentHandles : 4|1@1+ (1,0) [0|1] "" Vector__XXX
 SG_ VCSEC_frontLeftClosureRequest : 5|3@1+ (1,0) [0|7] "" Vector__XXX
 SG_ VCSEC_frontRightClosureRequest : 8|3@1+ (1,0) [0|7] "" Vector__XXX
 SG_ VCSEC_rearLeftClosureRequest : 11|3@1+ (1,0) [0|7] "" Vector__XXX
 SG_ VCSEC_rearRightClosureRequest : 14|3@1+ (1,0) [0|7] "" Vector__XXX
 SG_ VCSEC_rearTrunkClosureRequest : 17|3@1+ (1,0) [0|7] "" Vector__XXX
 SG_ VCSEC_frontLeftRequestReason : 20|3@1+ (1,0) [0|7] "" Vector__XXX
 SG_ VCSEC_frontRightRequestReason : 23|3@1+ (1,0) [0|7] "" Vector__XXX
 SG_ VCSEC_rearLeftRequestReason : 26|3@1+ (1,0) [0|7] "" Vector__XXX
 SG_ VCSEC_rearRightRequestReason : 29|3@1+ (1,0) [0|7] "" Vector__XXX
 SG_ VCSEC_rearTrunkRequestReason : 32|3@1+ (1,0) [0|7] "" Vector__XXX
 SG_ VCSEC_rdMapDumpRequested : 35|1@1+ (1,0) [0|1] "" Vector__XXX
 SG_ VCSEC_driveAttemptedWithoutAuth : 36|4@1+ (1,0) [0|15] "" Vector__XXX
 SG_ VCSEC_closeAllStatus : 41|2@1+ (1,0) [0|3] "" Vector__XXX
 SG_ VCSEC_snapshotRequested : 43|4@1+ (1,0) [0|15] "" Vector__XXX
 SG_ VCSEC_chargeportRequestReason : 47|3@1+ (1,0) [0|7] "" Vector__XXX
 SG_ VCSEC_frontTrunkClosureRequest : 51|3@1+ (1,0) [0|7] "" Vector__XXX
 SG_ VCSEC_frontTrunkRequestReason : 54|3@1+ (1,0) [0|7] "" Vector__XXX

BO_ 1850 VC_LVBMS_brickMeasurements: 8 VC
 SG_ VC_LVBMS_brickMeasurementsMultip M : 0|6@1+ (1,0) [0|63] "" Vector__XXX
 SG_ VC_LVBMS_brickVoltage1 m0 : 8|13@1+ (0.001,0) [0|6.535] "V" Vector__XXX
 SG_ VC_LVBMS_brickVoltage2 m0 : 24|13@1+ (0.001,0) [0|6.535] "V" Vector__XXX
 SG_ VC_LVBMS_brickVoltage3 m0 : 37|13@1+ (0.001,0) [0|6.535] "V" Vector__XXX
 SG_ VC_LVBMS_brickVoltage4 m0 : 50|13@1+ (0.001,0) [0|6.535] "V" Vector__XXX
 SG_ VC_LVBMS_brickBalancingAh1 m1 : 8|24@1+ (0.001,0) [0|16777.214] "Ah" Vector__XXX
 SG_ VC_LVBMS_brickBalancingAh2 m1 : 32|24@1+ (0.001,0) [0|16777.214] "Ah" Vector__XXX
 SG_ VC_LVBMS_brickBalancingState1 m1 : 56|1@1+ (1,0) [0|1] "" Vector__XXX
 SG_ VC_LVBMS_brickBalancingState2 m1 : 57|1@1+ (1,0) [0|1] "" Vector__XXX
 SG_ VC_LVBMS_brickBalancingAh3 m2 : 8|24@1+ (0.001,0) [0|16777.214] "Ah" Vector__XXX
 SG_ VC_LVBMS_brickBalancingAh4 m2 : 32|24@1+ (0.001,0) [0|16777.214] "Ah" Vector__XXX
 SG_ VC_LVBMS_brickBalancingState3 m2 : 56|1@1+ (1,0) [0|1] "" Vector__XXX
 SG_ VC_LVBMS_brickBalancingState4 m2 : 57|1@1+ (1,0) [0|1] "" Vector__XXX

BO_TX_BU_ 857 : VCSEC;
BO_TX_BU_ 473 : VCSEC;
BO_TX_BU_ 1066 : VCSEC;
BO_TX_BU_ 602 : VCSEC;
BO_TX_BU_ 825 : VCSEC;
BO_TX_BU_ 1824 : VCSEC;
BO_TX_BU_ 793 : VCSEC;
BO_TX_BU_ 505 : VCSEC;
BO_TX_BU_ 1850 : VC;
CM_ BO_ 857 "Vehicle security controller message: device status";
CM_ SG_ 857 VCSEC_DeviceStatusIndex "Vehicle security controller: device status index";
CM_ SG_ 857 VCSEC_Device0AuthResponseTime "Slowest response of an authed key";
CM_ SG_ 857 VCSEC_Device0Impermanent "Vehicle security controller: device0 impermanent";
CM_ SG_ 857 VCSEC_Device0SELockedDown "Vehicle security controller: device0 SE locked down";
CM_ SG_ 857 VCSEC_Device0Version "Vehicle security controller: device0 version";
CM_ SG_ 857 VCSEC_Device0WLEntry "White list index of Bluetooth device 0.";
CM_ SG_ 857 VCSEC_Device0OSVersion "Vehicle security controller: device0 OS version";
CM_ SG_ 857 VCSEC_Device0BatteryLevel "Battery voltage of Bluetooth device (Only for Keyfobs)";
CM_ SG_ 857 VCSEC_Device0Formfactor "Form factor device";
CM_ SG_ 857 VCSEC_Device0BlacklistStatus "Vehicle security controller: device0 blacklist status";
CM_ SG_ 857 VCSEC_Device0Stationary "Vehicle security controller: device0 stationary";
CM_ SG_ 857 VCSEC_Device0Bonded "Vehicle security controller: device0 bonded";
CM_ SG_ 857 VCSEC_Device0Role "Vehicle security controller: device0 role";
CM_ SG_ 857 VCSEC_Device0WhitelistActiveTime "Vehicle security controller: device0 whitelist active time";
CM_ SG_ 857 VCSEC_Device0SHA1 "SHA1 of the public key of the device";
CM_ SG_ 857 VCSEC_Device0Permissions "Vehicle security controller: device0 permissions";
CM_ SG_ 857 VCSEC_Device0ManufacturerHashBit "Vehicle security controller: device0 manufacturer hash bits";
CM_ SG_ 857 VCSEC_Device0BuildNumberHashBits "Vehicle security controller: device0 build number hash bits";
CM_ SG_ 857 VCSEC_Device1AuthResponseTime "Slowest response of an authed key; raw 127 = signal not available (SNA)";
CM_ SG_ 857 VCSEC_Device1Impermanent "Vehicle security controller: device1 impermanent";
CM_ SG_ 857 VCSEC_Device1SELockedDown "Vehicle security controller: device1 SE locked down";
CM_ SG_ 857 VCSEC_Device1Version "Vehicle security controller: device1 version";
CM_ SG_ 857 VCSEC_Device1WLEntry "White list index of the device";
CM_ SG_ 857 VCSEC_Device1OSVersion "Vehicle security controller: device1 OS version";
CM_ SG_ 857 VCSEC_Device1BatteryLevel "Battery voltage of Bluetooth device (Only for Keyfobs)";
CM_ SG_ 857 VCSEC_Device1Formfactor "Form factor of the device";
CM_ SG_ 857 VCSEC_Device1BlacklistStatus "Vehicle security controller: device1 blacklist status";
CM_ SG_ 857 VCSEC_Device1Stationary "Vehicle security controller: device1 stationary";
CM_ SG_ 857 VCSEC_Device1Bonded "Vehicle security controller: device1 bonded";
CM_ SG_ 857 VCSEC_Device1Role "Vehicle security controller: device1 role";
CM_ SG_ 857 VCSEC_Device1WhitelistActiveTime "Vehicle security controller: device1 whitelist active time";
CM_ SG_ 857 VCSEC_Device1SHA1 "SHA1 of the public key of the device";
CM_ SG_ 857 VCSEC_Device1Permissions "Vehicle security controller: device1 permissions";
CM_ SG_ 857 VCSEC_Device1ManufacturerHashBit "Vehicle security controller: device1 manufacturer hash bits";
CM_ SG_ 857 VCSEC_Device1BuildNumberHashBits "Vehicle security controller: device1 build number hash bits";
CM_ SG_ 857 VCSEC_Device2AuthResponseTime "Slowest response of an authed key; raw 127 = signal not available (SNA)";
CM_ SG_ 857 VCSEC_Device2Impermanent "Vehicle security controller: device2 impermanent";
CM_ SG_ 857 VCSEC_Device2SELockedDown "Vehicle security controller: device2 SE locked down";
CM_ SG_ 857 VCSEC_Device2Version "Vehicle security controller: device2 version";
CM_ SG_ 857 VCSEC_Device2WLEntry "White list index of Bluetooth device 2.";
CM_ SG_ 857 VCSEC_Device2OSVersion "Vehicle security controller: device2 OS version";
CM_ SG_ 857 VCSEC_Device2BatteryLevel "Battery voltage of Bluetooth device (Only for Keyfobs)";
CM_ SG_ 857 VCSEC_Device2Formfactor "Form factor of the device";
CM_ SG_ 857 VCSEC_Device2BlacklistStatus "Vehicle security controller: device2 blacklist status";
CM_ SG_ 857 VCSEC_Device2Stationary "Vehicle security controller: device2 stationary";
CM_ SG_ 857 VCSEC_Device2Bonded "Vehicle security controller: device2 bonded";
CM_ SG_ 857 VCSEC_Device2Role "Vehicle security controller: device2 role";
CM_ SG_ 857 VCSEC_Device2WhitelistActiveTime "Vehicle security controller: device2 whitelist active time";
CM_ SG_ 857 VCSEC_Device2SHA1 "SHA1 of the public key of the device";
CM_ SG_ 857 VCSEC_Device2Permissions "Vehicle security controller: device2 permissions";
CM_ SG_ 857 VCSEC_Device2ManufacturerHashBit "Vehicle security controller: device2 manufacturer hash bits";
CM_ SG_ 857 VCSEC_Device2BuildNumberHashBits "Vehicle security controller: device2 build number hash bits";
CM_ SG_ 857 VCSEC_Device3AuthResponseTime "Slowest response of an authed key; raw 127 = signal not available (SNA)";
CM_ SG_ 857 VCSEC_Device3Impermanent "Vehicle security controller: device3 impermanent";
CM_ SG_ 857 VCSEC_Device3SELockedDown "Vehicle security controller: device3 SE locked down";
CM_ SG_ 857 VCSEC_Device3Version "Vehicle security controller: device3 version";
CM_ SG_ 857 VCSEC_Device3WLEntry "White list index of the device.";
CM_ SG_ 857 VCSEC_Device3OSVersion "Vehicle security controller: device3 OS version";
CM_ SG_ 857 VCSEC_Device3BatteryLevel "Battery voltage of Bluetooth device (Only for Keyfobs)";
CM_ SG_ 857 VCSEC_Device3Formfactor "Form factor of the device.";
CM_ SG_ 857 VCSEC_Device3BlacklistStatus "Vehicle security controller: device3 blacklist status";
CM_ SG_ 857 VCSEC_Device3Stationary "Vehicle security controller: device3 stationary";
CM_ SG_ 857 VCSEC_Device3Bonded "Vehicle security controller: device3 bonded";
CM_ SG_ 857 VCSEC_Device3Role "Vehicle security controller: device3 role";
CM_ SG_ 857 VCSEC_Device3WhitelistActiveTime "Vehicle security controller: device3 whitelist active time";
CM_ SG_ 857 VCSEC_Device3SHA1 "SHA1 of the public key of the device";
CM_ SG_ 857 VCSEC_Device3Permissions "Vehicle security controller: device3 permissions";
CM_ SG_ 857 VCSEC_Device3ManufacturerHashBit "Vehicle security controller: device3 manufacturer hash bits";
CM_ SG_ 857 VCSEC_Device3BuildNumberHashBits "Vehicle security controller: device3 build number hash bits";
CM_ SG_ 857 VCSEC_Device4AuthResponseTime "Slowest response of an authed key; raw 127 = signal not available (SNA)";
CM_ SG_ 857 VCSEC_Device4Impermanent "Vehicle security controller: device4 impermanent";
CM_ SG_ 857 VCSEC_Device4SELockedDown "Vehicle security controller: device4 SE locked down";
CM_ SG_ 857 VCSEC_Device4Version "Vehicle security controller: device4 version";
CM_ SG_ 857 VCSEC_Device4WLEntry "White list index of the device.";
CM_ SG_ 857 VCSEC_Device4OSVersion "Vehicle security controller: device4 OS version";
CM_ SG_ 857 VCSEC_Device4BatteryLevel "Battery voltage of Bluetooth device (Only for Keyfobs)";
CM_ SG_ 857 VCSEC_Device4Formfactor "Form factor of the device.";
CM_ SG_ 857 VCSEC_Device4BlacklistStatus "Vehicle security controller: device4 blacklist status";
CM_ SG_ 857 VCSEC_Device4Stationary "Vehicle security controller: device4 stationary";
CM_ SG_ 857 VCSEC_Device4Bonded "Vehicle security controller: device4 bonded";
CM_ SG_ 857 VCSEC_Device4Role "Vehicle security controller: device4 role";
CM_ SG_ 857 VCSEC_Device4WhitelistActiveTime "Vehicle security controller: device4 whitelist active time";
CM_ SG_ 857 VCSEC_Device4SHA1 "SHA1 of the public key of the device";
CM_ SG_ 857 VCSEC_Device4Permissions "Vehicle security controller: device4 permissions";
CM_ SG_ 857 VCSEC_Device4ManufacturerHashBit "Vehicle security controller: device4 manufacturer hash bits";
CM_ SG_ 857 VCSEC_Device4BuildNumberHashBits "Vehicle security controller: device4 build number hash bits";
CM_ SG_ 857 VCSEC_Device5AuthResponseTime "Slowest response of an authed key; raw 127 = signal not available (SNA)";
CM_ SG_ 857 VCSEC_Device5Impermanent "Vehicle security controller: device5 impermanent";
CM_ SG_ 857 VCSEC_Device5SELockedDown "Vehicle security controller: device5 SE locked down";
CM_ SG_ 857 VCSEC_Device5Version "Vehicle security controller: device5 version";
CM_ SG_ 857 VCSEC_Device5WLEntry "White list index of the device.";
CM_ SG_ 857 VCSEC_Device5OSVersion "Vehicle security controller: device5 OS version";
CM_ SG_ 857 VCSEC_Device5BatteryLevel "Battery voltage of Bluetooth device (Only for Keyfobs)";
CM_ SG_ 857 VCSEC_Device5Formfactor "Form factor of the device.";
CM_ SG_ 857 VCSEC_Device5BlacklistStatus "Vehicle security controller: device5 blacklist status";
CM_ SG_ 857 VCSEC_Device5Stationary "Vehicle security controller: device5 stationary";
CM_ SG_ 857 VCSEC_Device5Bonded "Vehicle security controller: device5 bonded";
CM_ SG_ 857 VCSEC_Device5Role "Vehicle security controller: device5 role";
CM_ SG_ 857 VCSEC_Device5WhitelistActiveTime "Vehicle security controller: device5 whitelist active time";
CM_ SG_ 857 VCSEC_Device5SHA1 "SHA1 of the public key of the device";
CM_ SG_ 857 VCSEC_Device5Permissions "Vehicle security controller: device5 permissions";
CM_ SG_ 857 VCSEC_Device5ManufacturerHashBit "Vehicle security controller: device5 manufacturer hash bits";
CM_ SG_ 857 VCSEC_Device5BuildNumberHashBits "Vehicle security controller: device5 build number hash bits";
CM_ SG_ 857 VCSEC_Device6AuthResponseTime "Slowest response of an authed key; raw 127 = signal not available (SNA)";
CM_ SG_ 857 VCSEC_Device6Impermanent "Vehicle security controller: device6 impermanent";
CM_ SG_ 857 VCSEC_Device6SELockedDown "Vehicle security controller: device6 SE locked down";
CM_ SG_ 857 VCSEC_Device6Version "Vehicle security controller: device6 version";
CM_ SG_ 857 VCSEC_Device6WLEntry "White list index of the device.";
CM_ SG_ 857 VCSEC_Device6OSVersion "Vehicle security controller: device6 OS version";
CM_ SG_ 857 VCSEC_Device6BatteryLevel "Battery voltage of Bluetooth device (Only for Keyfobs)";
CM_ SG_ 857 VCSEC_Device6Formfactor "Form factor of the device.";
CM_ SG_ 857 VCSEC_Device6BlacklistStatus "Vehicle security controller: device6 blacklist status";
CM_ SG_ 857 VCSEC_Device6Stationary "Vehicle security controller: device6 stationary";
CM_ SG_ 857 VCSEC_Device6Bonded "Vehicle security controller: device6 bonded";
CM_ SG_ 857 VCSEC_Device6Role "Vehicle security controller: device6 role";
CM_ SG_ 857 VCSEC_Device6WhitelistActiveTime "Vehicle security controller: device6 whitelist active time";
CM_ SG_ 857 VCSEC_Device6SHA1 "SHA1 of the public key of the device";
CM_ SG_ 857 VCSEC_Device6Permissions "Vehicle security controller: device6 permissions";
CM_ SG_ 857 VCSEC_Device6ManufacturerHashBit "Vehicle security controller: device6 manufacturer hash bits";
CM_ SG_ 857 VCSEC_Device6BuildNumberHashBits "Vehicle security controller: device6 build number hash bits";
CM_ SG_ 857 VCSEC_Device7AuthResponseTime "Slowest response of an authed key; raw 127 = signal not available (SNA)";
CM_ SG_ 857 VCSEC_Device7Impermanent "Vehicle security controller: device7 impermanent";
CM_ SG_ 857 VCSEC_Device7SELockedDown "Vehicle security controller: device7 SE locked down";
CM_ SG_ 857 VCSEC_Device7Version "Vehicle security controller: device7 version";
CM_ SG_ 857 VCSEC_Device7WLEntry "White list index of the device.";
CM_ SG_ 857 VCSEC_Device7OSVersion "Vehicle security controller: device7 OS version";
CM_ SG_ 857 VCSEC_Device7BatteryLevel "Battery voltage of Bluetooth device (Only for Keyfobs)";
CM_ SG_ 857 VCSEC_Device7Formfactor "Form factor of the device.";
CM_ SG_ 857 VCSEC_Device7BlacklistStatus "Vehicle security controller: device7 blacklist status";
CM_ SG_ 857 VCSEC_Device7Stationary "Vehicle security controller: device7 stationary";
CM_ SG_ 857 VCSEC_Device7Bonded "Vehicle security controller: device7 bonded";
CM_ SG_ 857 VCSEC_Device7Role "Vehicle security controller: device7 role";
CM_ SG_ 857 VCSEC_Device7WhitelistActiveTime "Vehicle security controller: device7 whitelist active time";
CM_ SG_ 857 VCSEC_Device7SHA1 "SHA1 of the public key of the device";
CM_ SG_ 857 VCSEC_Device7Permissions "Vehicle security controller: device7 permissions";
CM_ SG_ 857 VCSEC_Device7ManufacturerHashBit "Vehicle security controller: device7 manufacturer hash bits";
CM_ SG_ 857 VCSEC_Device7BuildNumberHashBits "Vehicle security controller: device7 build number hash bits";
CM_ SG_ 857 VCSEC_Device8AuthResponseTime "Slowest response of an authed key; raw 127 = signal not available (SNA)";
CM_ SG_ 857 VCSEC_Device8Impermanent "Vehicle security controller: device8 impermanent";
CM_ SG_ 857 VCSEC_Device8SELockedDown "Vehicle security controller: device8 SE locked down";
CM_ SG_ 857 VCSEC_Device8Version "Vehicle security controller: device8 version";
CM_ SG_ 857 VCSEC_Device8WLEntry "White list index of the device.";
CM_ SG_ 857 VCSEC_Device8OSVersion "Vehicle security controller: device8 OS version";
CM_ SG_ 857 VCSEC_Device8BatteryLevel "Battery voltage of Bluetooth device (Only for Keyfobs)";
CM_ SG_ 857 VCSEC_Device8Formfactor "Form factor of the device.";
CM_ SG_ 857 VCSEC_Device8BlacklistStatus "Vehicle security controller: device8 blacklist status";
CM_ SG_ 857 VCSEC_Device8Stationary "Vehicle security controller: device8 stationary";
CM_ SG_ 857 VCSEC_Device8Bonded "Vehicle security controller: device8 bonded";
CM_ SG_ 857 VCSEC_Device8Role "Vehicle security controller: device8 role";
CM_ SG_ 857 VCSEC_Device8WhitelistActiveTime "Vehicle security controller: device8 whitelist active time";
CM_ SG_ 857 VCSEC_Device8SHA1 "SHA1 of the public key of the device";
CM_ SG_ 857 VCSEC_Device8Permissions "Vehicle security controller: device8 permissions";
CM_ SG_ 857 VCSEC_Device8ManufacturerHashBit "Vehicle security controller: device8 manufacturer hash bits";
CM_ SG_ 857 VCSEC_Device8BuildNumberHashBits "Vehicle security controller: device8 build number hash bits";
CM_ SG_ 857 VCSEC_Device9AuthResponseTime "Slowest response of an authed key; raw 127 = signal not available (SNA)";
CM_ SG_ 857 VCSEC_Device9Impermanent "Vehicle security controller: device9 impermanent";
CM_ SG_ 857 VCSEC_Device9SELockedDown "Vehicle security controller: device9 SE locked down";
CM_ SG_ 857 VCSEC_Device9Version "Vehicle security controller: device9 version";
CM_ SG_ 857 VCSEC_Device9WLEntry "White list index of the device.";
CM_ SG_ 857 VCSEC_Device9OSVersion "Vehicle security controller: device9 OS version";
CM_ SG_ 857 VCSEC_Device9BatteryLevel "Battery voltage of Bluetooth device (Only for Keyfobs)";
CM_ SG_ 857 VCSEC_Device9Formfactor "Form factor of the device.";
CM_ SG_ 857 VCSEC_Device9BlacklistStatus "Vehicle security controller: device9 blacklist status";
CM_ SG_ 857 VCSEC_Device9Stationary "Vehicle security controller: device9 stationary";
CM_ SG_ 857 VCSEC_Device9Bonded "Vehicle security controller: device9 bonded";
CM_ SG_ 857 VCSEC_Device9Role "Vehicle security controller: device9 role";
CM_ SG_ 857 VCSEC_Device9WhitelistActiveTime "Vehicle security controller: device9 whitelist active time";
CM_ SG_ 857 VCSEC_Device9SHA1 "SHA1 of the public key of the device";
CM_ SG_ 857 VCSEC_Device9Permissions "Vehicle security controller: device9 permissions";
CM_ SG_ 857 VCSEC_Device9ManufacturerHashBit "Vehicle security controller: device9 manufacturer hash bits";
CM_ SG_ 857 VCSEC_Device9BuildNumberHashBits "Vehicle security controller: device9 build number hash bits";
CM_ SG_ 857 VCSEC_Device10AuthResponseTime "Slowest response of an authed key; raw 127 = signal not available (SNA)";
CM_ SG_ 857 VCSEC_Device10Impermanent "Vehicle security controller: device10 impermanent";
CM_ SG_ 857 VCSEC_Device10SELockedDown "Vehicle security controller: device10 SE locked down";
CM_ SG_ 857 VCSEC_Device10Version "Vehicle security controller: device10 version";
CM_ SG_ 857 VCSEC_Device10WLEntry "White list index of the device.";
CM_ SG_ 857 VCSEC_Device10OSVersion "Vehicle security controller: device10 OS version";
CM_ SG_ 857 VCSEC_Device10BatteryLevel "Battery voltage of Bluetooth device (Only for Keyfobs)";
CM_ SG_ 857 VCSEC_Device10Formfactor "Form factor of the device.";
CM_ SG_ 857 VCSEC_Device10BlacklistStatus "Vehicle security controller: device10 blacklist status";
CM_ SG_ 857 VCSEC_Device10Stationary "Vehicle security controller: device10 stationary";
CM_ SG_ 857 VCSEC_Device10Bonded "Vehicle security controller: device10 bonded";
CM_ SG_ 857 VCSEC_Device10Role "Vehicle security controller: device10 role";
CM_ SG_ 857 VCSEC_Device10WhitelistActiveTim "Vehicle security controller: device10 whitelist active time";
CM_ SG_ 857 VCSEC_Device10SHA1 "SHA1 of the public key of the device";
CM_ SG_ 857 VCSEC_Device10Permissions "Vehicle security controller: device10 permissions";
CM_ SG_ 857 VCSEC_Device10ManufacturerHashBi "Vehicle security controller: device10 manufacturer hash bits";
CM_ SG_ 857 VCSEC_Device10BuildNumberHashBit "Vehicle security controller: device10 build number hash bits";
CM_ SG_ 857 VCSEC_Device11AuthResponseTime "Slowest response of an authed key; raw 127 = signal not available (SNA)";
CM_ SG_ 857 VCSEC_Device11Impermanent "Vehicle security controller: device11 impermanent";
CM_ SG_ 857 VCSEC_Device11SELockedDown "Vehicle security controller: device11 SE locked down";
CM_ SG_ 857 VCSEC_Device11Version "Vehicle security controller: device11 version";
CM_ SG_ 857 VCSEC_Device11WLEntry "White list index of the device.";
CM_ SG_ 857 VCSEC_Device11OSVersion "Vehicle security controller: device11 OS version";
CM_ SG_ 857 VCSEC_Device11BatteryLevel "Battery voltage of Bluetooth device (Only for Keyfobs)";
CM_ SG_ 857 VCSEC_Device11Formfactor "Form factor of the device.";
CM_ SG_ 857 VCSEC_Device11BlacklistStatus "Vehicle security controller: device11 blacklist status";
CM_ SG_ 857 VCSEC_Device11Stationary "Vehicle security controller: device11 stationary";
CM_ SG_ 857 VCSEC_Device11Bonded "Vehicle security controller: device11 bonded";
CM_ SG_ 857 VCSEC_Device11Role "Vehicle security controller: device11 role";
CM_ SG_ 857 VCSEC_Device11WhitelistActiveTim "Vehicle security controller: device11 whitelist active time";
CM_ SG_ 857 VCSEC_Device11SHA1 "SHA1 of the public key of the device";
CM_ SG_ 857 VCSEC_Device11Permissions "Vehicle security controller: device11 permissions";
CM_ SG_ 857 VCSEC_Device11ManufacturerHashBi "Vehicle security controller: device11 manufacturer hash bits";
CM_ SG_ 857 VCSEC_Device11BuildNumberHashBit "Vehicle security controller: device11 build number hash bits";
CM_ SG_ 857 VCSEC_Device12AuthResponseTime "Slowest response of an authed key; raw 127 = signal not available (SNA)";
CM_ SG_ 857 VCSEC_Device12Impermanent "Vehicle security controller: device12 impermanent";
CM_ SG_ 857 VCSEC_Device12SELockedDown "Vehicle security controller: device12 SE locked down";
CM_ SG_ 857 VCSEC_Device12Version "Vehicle security controller: device12 version";
CM_ SG_ 857 VCSEC_Device12WLEntry "White list index of the device.";
CM_ SG_ 857 VCSEC_Device12OSVersion "Vehicle security controller: device12 OS version";
CM_ SG_ 857 VCSEC_Device12BatteryLevel "Battery voltage of Bluetooth device (Only for Keyfobs)";
CM_ SG_ 857 VCSEC_Device12Formfactor "Form factor of the device.";
CM_ SG_ 857 VCSEC_Device12BlacklistStatus "Vehicle security controller: device12 blacklist status";
CM_ SG_ 857 VCSEC_Device12Stationary "Vehicle security controller: device12 stationary";
CM_ SG_ 857 VCSEC_Device12Bonded "Vehicle security controller: device12 bonded";
CM_ SG_ 857 VCSEC_Device12Role "Vehicle security controller: device12 role";
CM_ SG_ 857 VCSEC_Device12WhitelistActiveTim "Vehicle security controller: device12 whitelist active time";
CM_ SG_ 857 VCSEC_Device12SHA1 "SHA1 of the public key of the device";
CM_ SG_ 857 VCSEC_Device12Permissions "Vehicle security controller: device12 permissions";
CM_ SG_ 857 VCSEC_Device12ManufacturerHashBi "Vehicle security controller: device12 manufacturer hash bits";
CM_ SG_ 857 VCSEC_Device12BuildNumberHashBit "Vehicle security controller: device12 build number hash bits";
CM_ SG_ 857 VCSEC_Device13AuthResponseTime "Slowest response of an authed key; raw 127 = signal not available (SNA)";
CM_ SG_ 857 VCSEC_Device13Impermanent "Vehicle security controller: device13 impermanent";
CM_ SG_ 857 VCSEC_Device13SELockedDown "Vehicle security controller: device13 SE locked down";
CM_ SG_ 857 VCSEC_Device13Version "Vehicle security controller: device13 version";
CM_ SG_ 857 VCSEC_Device13WLEntry "White list index of the device.";
CM_ SG_ 857 VCSEC_Device13OSVersion "Vehicle security controller: device13 OS version";
CM_ SG_ 857 VCSEC_Device13BatteryLevel "Battery voltage of Bluetooth device (Only for Keyfobs)";
CM_ SG_ 857 VCSEC_Device13Formfactor "Form factor of the device.";
CM_ SG_ 857 VCSEC_Device13BlacklistStatus "Vehicle security controller: device13 blacklist status";
CM_ SG_ 857 VCSEC_Device13Stationary "Vehicle security controller: device13 stationary";
CM_ SG_ 857 VCSEC_Device13Bonded "Vehicle security controller: device13 bonded";
CM_ SG_ 857 VCSEC_Device13Role "Vehicle security controller: device13 role";
CM_ SG_ 857 VCSEC_Device13WhitelistActiveTim "Vehicle security controller: device13 whitelist active time";
CM_ SG_ 857 VCSEC_Device13SHA1 "SHA1 of the public key of the device";
CM_ SG_ 857 VCSEC_Device13Permissions "Vehicle security controller: device13 permissions";
CM_ SG_ 857 VCSEC_Device13ManufacturerHashBi "Vehicle security controller: device13 manufacturer hash bits";
CM_ SG_ 857 VCSEC_Device13BuildNumberHashBit "Vehicle security controller: device13 build number hash bits";
CM_ SG_ 857 VCSEC_Device14AuthResponseTime "Slowest response of an authed key; raw 127 = signal not available (SNA)";
CM_ SG_ 857 VCSEC_Device14Impermanent "Vehicle security controller: device14 impermanent";
CM_ SG_ 857 VCSEC_Device14SELockedDown "Vehicle security controller: device14 SE locked down";
CM_ SG_ 857 VCSEC_Device14Version "Vehicle security controller: device14 version";
CM_ SG_ 857 VCSEC_Device14WLEntry "White list index of the device.";
CM_ SG_ 857 VCSEC_Device14OSVersion "Vehicle security controller: device14 OS version";
CM_ SG_ 857 VCSEC_Device14BatteryLevel "Battery voltage of Bluetooth device (Only for Keyfobs)";
CM_ SG_ 857 VCSEC_Device14Formfactor "Form factor of the device.";
CM_ SG_ 857 VCSEC_Device14BlacklistStatus "Vehicle security controller: device14 blacklist status";
CM_ SG_ 857 VCSEC_Device14Stationary "Vehicle security controller: device14 stationary";
CM_ SG_ 857 VCSEC_Device14Bonded "Vehicle security controller: device14 bonded";
CM_ SG_ 857 VCSEC_Device14Role "Vehicle security controller: device14 role";
CM_ SG_ 857 VCSEC_Device14WhitelistActiveTim "Vehicle security controller: device14 whitelist active time";
CM_ SG_ 857 VCSEC_Device14SHA1 "SHA1 of the public key of the device";
CM_ SG_ 857 VCSEC_Device14Permissions "Vehicle security controller: device14 permissions";
CM_ SG_ 857 VCSEC_Device14ManufacturerHashBi "Vehicle security controller: device14 manufacturer hash bits";
CM_ SG_ 857 VCSEC_Device14BuildNumberHashBit "Vehicle security controller: device14 build number hash bits";
CM_ SG_ 857 VCSEC_Device15AuthResponseTime "Slowest response of an authed key; raw 127 = signal not available (SNA)";
CM_ SG_ 857 VCSEC_Device15Impermanent "Vehicle security controller: device15 impermanent";
CM_ SG_ 857 VCSEC_Device15SELockedDown "Vehicle security controller: device15 SE locked down";
CM_ SG_ 857 VCSEC_Device15Version "Vehicle security controller: device15 version";
CM_ SG_ 857 VCSEC_Device15WLEntry "White list index of the device.";
CM_ SG_ 857 VCSEC_Device15OSVersion "Vehicle security controller: device15 OS version";
CM_ SG_ 857 VCSEC_Device15BatteryLevel "Battery voltage of Bluetooth device (Only for Keyfobs)";
CM_ SG_ 857 VCSEC_Device15Formfactor "Form factor of the device.";
CM_ SG_ 857 VCSEC_Device15BlacklistStatus "Vehicle security controller: device15 blacklist status";
CM_ SG_ 857 VCSEC_Device15Stationary "Vehicle security controller: device15 stationary";
CM_ SG_ 857 VCSEC_Device15Bonded "Vehicle security controller: device15 bonded";
CM_ SG_ 857 VCSEC_Device15Role "Vehicle security controller: device15 role";
CM_ SG_ 857 VCSEC_Device15WhitelistActiveTim "Vehicle security controller: device15 whitelist active time";
CM_ SG_ 857 VCSEC_Device15SHA1 "SHA1 of the public key of the device";
CM_ SG_ 857 VCSEC_Device15Permissions "Vehicle security controller: device15 permissions";
CM_ SG_ 857 VCSEC_Device15ManufacturerHashBi "Vehicle security controller: device15 manufacturer hash bits";
CM_ SG_ 857 VCSEC_Device15BuildNumberHashBit "Vehicle security controller: device15 build number hash bits";
CM_ SG_ 857 VCSEC_Device16AuthResponseTime "Slowest response of an authed key; raw 127 = signal not available (SNA)";
CM_ SG_ 857 VCSEC_Device16Impermanent "Vehicle security controller: device16 impermanent";
CM_ SG_ 857 VCSEC_Device16SELockedDown "Vehicle security controller: device16 SE locked down";
CM_ SG_ 857 VCSEC_Device16Version "Vehicle security controller: device16 version";
CM_ SG_ 857 VCSEC_Device16WLEntry "White list index of the device.";
CM_ SG_ 857 VCSEC_Device16OSVersion "Vehicle security controller: device16 OS version";
CM_ SG_ 857 VCSEC_Device16BatteryLevel "Battery voltage of Bluetooth device (Only for Keyfobs)";
CM_ SG_ 857 VCSEC_Device16Formfactor "Form factor of the device.";
CM_ SG_ 857 VCSEC_Device16BlacklistStatus "Vehicle security controller: device16 blacklist status";
CM_ SG_ 857 VCSEC_Device16Stationary "Vehicle security controller: device16 stationary";
CM_ SG_ 857 VCSEC_Device16Bonded "Vehicle security controller: device16 bonded";
CM_ SG_ 857 VCSEC_Device16Role "Vehicle security controller: device16 role";
CM_ SG_ 857 VCSEC_Device16WhitelistActiveTim "Vehicle security controller: device16 whitelist active time";
CM_ SG_ 857 VCSEC_Device16SHA1 "SHA1 of the public key of the device";
CM_ SG_ 857 VCSEC_Device16Permissions "Vehicle security controller: device16 permissions";
CM_ SG_ 857 VCSEC_Device16ManufacturerHashBi "Vehicle security controller: device16 manufacturer hash bits";
CM_ SG_ 857 VCSEC_Device16BuildNumberHashBit "Vehicle security controller: device16 build number hash bits";
CM_ SG_ 857 VCSEC_Device17AuthResponseTime "Slowest response of an authed key; raw 127 = signal not available (SNA)";
CM_ SG_ 857 VCSEC_Device17Impermanent "Vehicle security controller: device17 impermanent";
CM_ SG_ 857 VCSEC_Device17SELockedDown "Vehicle security controller: device17 SE locked down";
CM_ SG_ 857 VCSEC_Device17Version "Vehicle security controller: device17 version";
CM_ SG_ 857 VCSEC_Device17WLEntry "White list index of the device.";
CM_ SG_ 857 VCSEC_Device17OSVersion "Vehicle security controller: device17 OS version";
CM_ SG_ 857 VCSEC_Device17BatteryLevel "Battery voltage of Bluetooth device (Only for Keyfobs)";
CM_ SG_ 857 VCSEC_Device17Formfactor "Form factor of the device.";
CM_ SG_ 857 VCSEC_Device17BlacklistStatus "Vehicle security controller: device17 blacklist status";
CM_ SG_ 857 VCSEC_Device17Stationary "Vehicle security controller: device17 stationary";
CM_ SG_ 857 VCSEC_Device17Bonded "Vehicle security controller: device17 bonded";
CM_ SG_ 857 VCSEC_Device17Role "Vehicle security controller: device17 role";
CM_ SG_ 857 VCSEC_Device17WhitelistActiveTim "Vehicle security controller: device17 whitelist active time";
CM_ SG_ 857 VCSEC_Device17SHA1 "SHA1 of the public key of the device";
CM_ SG_ 857 VCSEC_Device17Permissions "Vehicle security controller: device17 permissions";
CM_ SG_ 857 VCSEC_Device17ManufacturerHashBi "Vehicle security controller: device17 manufacturer hash bits";
CM_ SG_ 857 VCSEC_Device17BuildNumberHashBit "Vehicle security controller: device17 build number hash bits";
CM_ SG_ 857 VCSEC_Device18AuthResponseTime "Slowest response of an authed key; raw 127 = signal not available (SNA)";
CM_ SG_ 857 VCSEC_Device18Impermanent "Vehicle security controller: device18 impermanent";
CM_ SG_ 857 VCSEC_Device18SELockedDown "Vehicle security controller: device18 SE locked down";
CM_ SG_ 857 VCSEC_Device18Version "Vehicle security controller: device18 version";
CM_ SG_ 857 VCSEC_Device18WLEntry "White list index of the device.";
CM_ SG_ 857 VCSEC_Device18OSVersion "Vehicle security controller: device18 OS version";
CM_ SG_ 857 VCSEC_Device18BatteryLevel "Battery voltage of Bluetooth device (Only for Keyfobs)";
CM_ SG_ 857 VCSEC_Device18Formfactor "Form factor of the device.";
CM_ SG_ 857 VCSEC_Device18BlacklistStatus "Vehicle security controller: device18 blacklist status";
CM_ SG_ 857 VCSEC_Device18Stationary "Vehicle security controller: device18 stationary";
CM_ SG_ 857 VCSEC_Device18Bonded "Vehicle security controller: device18 bonded";
CM_ SG_ 857 VCSEC_Device18Role "Vehicle security controller: device18 role";
CM_ SG_ 857 VCSEC_Device18WhitelistActiveTim "Vehicle security controller: device18 whitelist active time";
CM_ SG_ 857 VCSEC_Device18SHA1 "SHA1 of the public key of the device";
CM_ SG_ 857 VCSEC_Device18Permissions "Vehicle security controller: device18 permissions";
CM_ SG_ 857 VCSEC_Device18ManufacturerHashBi "Vehicle security controller: device18 manufacturer hash bits";
CM_ SG_ 857 VCSEC_Device18BuildNumberHashBit "Vehicle security controller: device18 build number hash bits";
CM_ SG_ 857 VCSEC_Device19AuthResponseTime "Slowest response of an authed key; raw 127 = signal not available (SNA)";
CM_ SG_ 857 VCSEC_Device19Impermanent "Vehicle security controller: device19 impermanent";
CM_ SG_ 857 VCSEC_Device19SELockedDown "Vehicle security controller: device19 SE locked down";
CM_ SG_ 857 VCSEC_Device19Version "Vehicle security controller: device19 version";
CM_ SG_ 857 VCSEC_Device19WLEntry "White list index of the device.";
CM_ SG_ 857 VCSEC_Device19OSVersion "Vehicle security controller: device19 OS version";
CM_ SG_ 857 VCSEC_Device19BatteryLevel "Battery voltage of Bluetooth device (Only for Keyfobs)";
CM_ SG_ 857 VCSEC_Device19Formfactor "Form factor of the device.";
CM_ SG_ 857 VCSEC_Device19BlacklistStatus "Vehicle security controller: device19 blacklist status";
CM_ SG_ 857 VCSEC_Device19Stationary "Vehicle security controller: device19 stationary";
CM_ SG_ 857 VCSEC_Device19Bonded "Vehicle security controller: device19 bonded";
CM_ SG_ 857 VCSEC_Device19Role "Vehicle security controller: device19 role";
CM_ SG_ 857 VCSEC_Device19WhitelistActiveTim "Vehicle security controller: device19 whitelist active time";
CM_ SG_ 857 VCSEC_Device19SHA1 "SHA1 of the public key of the device";
CM_ SG_ 857 VCSEC_Device19Permissions "Vehicle security controller: device19 permissions";
CM_ SG_ 857 VCSEC_Device19ManufacturerHashBi "Vehicle security controller: device19 manufacturer hash bits";
CM_ SG_ 857 VCSEC_Device19BuildNumberHashBit "Vehicle security controller: device19 build number hash bits";
CM_ BO_ 473 "Vehicle security controller message: iso tp UDP pipe UI";
CM_ SG_ 473 VCSEC_IsoTpUDPPipeUI0 "Vehicle security controller: iso tp UDP pipe UI0";
CM_ SG_ 473 VCSEC_IsoTpUDPPipeUI1 "Vehicle security controller: iso tp UDP pipe UI1";
CM_ SG_ 473 VCSEC_IsoTpUDPPipeUI2 "Vehicle security controller: iso tp UDP pipe UI2";
CM_ SG_ 473 VCSEC_IsoTpUDPPipeUI3 "Vehicle security controller: iso tp UDP pipe UI3";
CM_ SG_ 473 VCSEC_IsoTpUDPPipeUI4 "Vehicle security controller: iso tp UDP pipe UI4";
CM_ SG_ 473 VCSEC_IsoTpUDPPipeUI5 "Vehicle security controller: iso tp UDP pipe UI5";
CM_ SG_ 473 VCSEC_IsoTpUDPPipeUI6 "Vehicle security controller: iso tp UDP pipe UI6";
CM_ SG_ 473 VCSEC_IsoTpUDPPipeUI7 "Vehicle security controller: iso tp UDP pipe UI7";
CM_ BO_ 1066 "Vehicle security controller message: TPMS connection data";
CM_ SG_ 1066 VCSEC_TPMSSensorState0 "Indicates the sensors pairing/connectivity status";
CM_ SG_ 1066 VCSEC_TPMSRSSI0 "Received Signal Strength Index reported by sensor.";
CM_ SG_ 1066 VCSEC_TPMSConnectionTypeCurrent0 "Vehicle security controller: TPMS connection type current0";
CM_ SG_ 1066 VCSEC_TPMSConnectionTypeDesired0 "Vehicle security controller: TPMS connection type desired0";
CM_ SG_ 1066 VCSEC_TPMSSensorState1 "Indicates the sensors pairing/connectivity status";
CM_ SG_ 1066 VCSEC_TPMSRSSI1 "Received Signal Strength Index reported by sensor.";
CM_ SG_ 1066 VCSEC_TPMSConnectionTypeCurrent1 "Vehicle security controller: TPMS connection type current1";
CM_ SG_ 1066 VCSEC_TPMSConnectionTypeDesired1 "Vehicle security controller: TPMS connection type desired1";
CM_ SG_ 1066 VCSEC_TPMSSensorState2 "Indicates the sensors pairing/connectivity status";
CM_ SG_ 1066 VCSEC_TPMSRSSI2 "Received Signal Strength Index reported by sensor.";
CM_ SG_ 1066 VCSEC_TPMSConnectionTypeCurrent2 "Vehicle security controller: TPMS connection type current2";
CM_ SG_ 1066 VCSEC_TPMSConnectionTypeDesired2 "Vehicle security controller: TPMS connection type desired2";
CM_ SG_ 1066 VCSEC_TPMSSensorState3 "Indicates the sensors pairing/connectivity status";
CM_ SG_ 1066 VCSEC_TPMSRSSI3 "Received Signal Strength Index reported by sensor.";
CM_ SG_ 1066 VCSEC_TPMSConnectionTypeCurrent3 "Vehicle security controller: TPMS connection type current3";
CM_ SG_ 1066 VCSEC_TPMSConnectionTypeDesired3 "Vehicle security controller: TPMS connection type desired3";
CM_ SG_ 1066 VCSEC_TPMSSensorPresence0 "Indicates the sensors detection status";
CM_ SG_ 1066 VCSEC_TPMSSensorPresence1 "Indicates the sensors detection status";
CM_ SG_ 1066 VCSEC_TPMSSensorPresence2 "Indicates the sensors detection status";
CM_ SG_ 1066 VCSEC_TPMSSensorPresence3 "Indicates the sensors detection status";
CM_ BO_ 602 "Vehicle security controller message: TPMS display";
CM_ SG_ 602 VCSEC_TPMSDisplayPressureFL "Indicates Absolute pressure measured by wheel unit; raw 255 = signal not available (SNA)";
CM_ SG_ 602 VCSEC_TPMSDisplayPressureFR "Indicates Absolute pressure measured by wheel unit; raw 255 = signal not available (SNA)";
CM_ SG_ 602 VCSEC_TPMSDisplayPressureRL "Indicates Absolute pressure measured by wheel unit; raw 255 = signal not available (SNA)";
CM_ SG_ 602 VCSEC_TPMSDisplayPressureRR "Indicates Absolute pressure measured by wheel unit; raw 255 = signal not available (SNA)";
CM_ SG_ 602 VCSEC_TPMSTellTale "TPMS UI telltale status to indicate";
CM_ SG_ 602 VCSEC_TPMSDisplaySoftWarningIndi "UI should indicate soft warning";
CM_ SG_ 602 VCSEC_TPMSDisplaySoftWarnin_0001 "UI should indicate soft warning";
CM_ SG_ 602 VCSEC_TPMSDisplaySoftWarnin_0002 "UI should indicate soft warning";
CM_ SG_ 602 VCSEC_TPMSDisplaySoftWarnin_0003 "UI should indicate soft warning";
CM_ SG_ 602 VCSEC_TPMSDisplayHardWarningIndi "UI should indicate soft warning";
CM_ SG_ 602 VCSEC_TPMSDisplayHardWarnin_0001 "UI should indicate soft warning";
CM_ SG_ 602 VCSEC_TPMSDisplayHardWarnin_0002 "UI should indicate soft warning";
CM_ SG_ 602 VCSEC_TPMSDisplayHardWarnin_0003 "UI should indicate soft warning";
CM_ BO_ 825 "Vehicle security controller message: authentication";
CM_ SG_ 825 VCSEC_BLEConnectionCounter "The number of devices connected to the host Bluetooth endpoint.";
CM_ SG_ 825 VCSEC_authRejectionReason "Reason it was rejected";
CM_ SG_ 825 VCSEC_IDRequested "Vehicle security controller: ID requested";
CM_ SG_ 825 VCSEC_operationMode "Reports the operation mode of the vehicle.";
CM_ SG_ 825 VCSEC_vehicleLockStatus "Lock status of the vehicle; raw 0 = signal not available (SNA)";
CM_ SG_ 825 VCSEC_authenticationStatus "Reports the vehicle authentication status.";
CM_ SG_ 825 VCSEC_chargePortLockStatus "Lock status of the charge port.";
CM_ SG_ 825 VCSEC_leftFrontLockStatus "Lock status of the left front door.";
CM_ SG_ 825 VCSEC_leftRearLockStatus "Lock status of the left rear door.";
CM_ SG_ 825 VCSEC_rightFrontLockStatus "Lock status of the right front door.";
CM_ SG_ 825 VCSEC_rightRearLockStatus "Lock status of right rear door.";
CM_ SG_ 825 VCSEC_trunkLockStatus "Lock status of the trunk.";
CM_ SG_ 825 VCSEC_lockRequestType "Reports the type of lock and unlock request received.";
CM_ SG_ 825 VCSEC_summonRequest "Reports the Summon request state; raw 5 = signal not available (SNA)";
CM_ SG_ 825 VCSEC_3rdPartyPLGRequest "Vehicle security controller: 3rd party PLG request; raw 3 = signal not available (SNA)";
CM_ SG_ 825 VCSEC_3rdPartyFrunkPLGRequest "Vehicle security controller: 3rd party frunk PLG request; raw 3 = signal not available (SNA)";
CM_ SG_ 825 VCSEC_MCUCommandType "Vehicle security controller: MCU command type";
CM_ SG_ 825 VCSEC_frunkLockStatus "Lock status of the frunk";
CM_ SG_ 825 VCSEC_usingModifiedMACAddress "Vehicle security controller: using modified MAC address";
CM_ SG_ 825 VCSEC_isKeyWithinSummonRange "Key is within the range of the car where summon can be enabled";
CM_ SG_ 825 VCSEC_isBLEDeviceWithinSummonRan "Indicates whether a Bluetooth Low Energy (BLE) device is within the range where Summon can be enabled.";
CM_ SG_ 825 VCSEC_alarmStatus "Reports the vehicle alarm status; raw 15 = signal not available (SNA)";
CM_ SG_ 825 VCSEC_serviceDiagnosticRequest "Vehicle security controller: service diagnostic request";
CM_ SG_ 825 VCSEC_immobilizerState "State of the immobilizer.";
CM_ SG_ 825 VCSEC_lockIndicationRequest "Requests to turn on vehicle turn indicators based on lock and unlock states; raw 0 = signal not available (SNA)";
CM_ SG_ 825 VCSEC_simpleLockStatus "Vehicle lock status with simplfied two states: lock and unlock; raw 0 = signal not available (SNA)";
CM_ SG_ 825 VCSEC_keyChannelIndexed "Vehicle security controller: key channel indexed; raw 15 = signal not available (SNA)";
CM_ SG_ 825 VCSEC_authRequested "An authentication request was sent from the security controller to the authentication device.";
CM_ SG_ 825 VCSEC_remoteStartActive "Indicates when a remote start request terminated by the Vehicle Security Controller (VCSEC) is active.";
CM_ SG_ 825 VCSEC_keyPairDesired "Vehicle security controller: key pair desired";
CM_ BO_ 1824 "Vehicle security controller message: ecu config";
CM_ SG_ 1824 VCSEC_ECUConfigCRC32 "Vehicle security controller: ECU config CRC32";
CM_ SG_ 1824 VCSEC_autoWriteConfig "Vehicle security controller: auto write config";
CM_ SG_ 1824 VCSEC_requestForConfig "Vehicle security controller: request for config";
CM_ BO_ 793 "Vehicle security controller message: info";
CM_ SG_ 793 VCSEC_infoIndex "Vehicle security controller: info index";
CM_ SG_ 793 VCSEC_infoBuildType "Vehicle security controller: info build type";
CM_ SG_ 793 VCSEC_infoBuildConfigId "Vehicle security controller: info build config id";
CM_ SG_ 793 VCSEC_infoHardwareId "Vehicle security controller: info hardware id";
CM_ SG_ 793 VCSEC_infoComponentId "Vehicle security controller: info component id";
CM_ SG_ 793 VCSEC_infoPcbaId "Vehicle security controller: info pcba id";
CM_ SG_ 793 VCSEC_infoAssemblyId "Vehicle security controller: info assembly id; raw 255 = signal not available (SNA)";
CM_ SG_ 793 VCSEC_infoUsageId "Vehicle security controller: info usage id";
CM_ SG_ 793 VCSEC_infoSubUsageId "Vehicle security controller: info sub usage id";
CM_ SG_ 793 VCSEC_infoAppCrc "Vehicle security controller: info app crc";
CM_ SG_ 793 VCSEC_infoSubcomponent1 "Vehicle security controller: info subcomponent1";
CM_ SG_ 793 VCSEC_infoAppGitHash "Vehicle security controller: info app git hash";
CM_ SG_ 793 VCSEC_infoBootGitHash "Vehicle security controller: info boot git hash";
CM_ SG_ 793 VCSEC_infoPlatformType "Vehicle security controller: info platform type";
CM_ SG_ 793 VCSEC_infoBootUdsProtoVersion "Vehicle security controller: info boot uds proto version";
CM_ SG_ 793 VCSEC_infoBootCrc "Vehicle security controller: info boot crc";
CM_ SG_ 793 VCSEC_infoSubcomponent2 "Vehicle security controller: info subcomponent2";
CM_ SG_ 793 VCSEC_infoSubcomponent3 "Vehicle security controller: info subcomponent3";
CM_ SG_ 793 VCSEC_infoSubcomponent4 "Vehicle security controller: info subcomponent4";
CM_ BO_ 505 "Vehicle security controller message: requests";
CM_ SG_ 505 VCSEC_chargePortRequest "Open and close requests of the charge port door; raw 3 = signal not available (SNA)";
CM_ SG_ 505 VCSEC_presentHandles "VCSEC command to present the handles. Applicable to Model S.";
CM_ SG_ 505 VCSEC_frontLeftClosureRequest "VCSEC command to present the front left door.";
CM_ SG_ 505 VCSEC_frontRightClosureRequest "VCSEC command to present the front right door.";
CM_ SG_ 505 VCSEC_rearLeftClosureRequest "open and close requests of the left rear door.";
CM_ SG_ 505 VCSEC_rearRightClosureRequest "open and close requests of the right rear door.";
CM_ SG_ 505 VCSEC_rearTrunkClosureRequest "VCSEC command to operate the rear trunk.";
CM_ SG_ 505 VCSEC_frontLeftRequestReason "VCSEC reason to present the front left door.";
CM_ SG_ 505 VCSEC_frontRightRequestReason "VCSEC reason to present the front right door.";
CM_ SG_ 505 VCSEC_rearLeftRequestReason "open and close request reason of the left rear door.";
CM_ SG_ 505 VCSEC_rearRightRequestReason "open and close request reason of the right rear door.";
CM_ SG_ 505 VCSEC_rearTrunkRequestReason "VCSEC reason for command to operate the rear trunk.";
CM_ SG_ 505 VCSEC_rdMapDumpRequested "Vehicle security controller: rd map dump requested";
CM_ SG_ 505 VCSEC_driveAttemptedWithoutAuth "Driver is attempting shift into drive wihout a key present";
CM_ SG_ 505 VCSEC_closeAllStatus "Vehicle security controller: close all status";
CM_ SG_ 505 VCSEC_snapshotRequested "Vehicle security controller: snapshot requested";
CM_ SG_ 505 VCSEC_chargeportRequestReason "VCSEC reason to open the chargeport door.";
CM_ SG_ 505 VCSEC_frontTrunkClosureRequest "VCSEC command to operate front trunk.";
CM_ SG_ 505 VCSEC_frontTrunkRequestReason "VCSEC reason to present the front left door.";
CM_ BO_ 1850 "VC ECU message: LVBMS brick measurements";
CM_ SG_ 1850 VC_LVBMS_brickMeasurementsMultip "VC ECU: LVBMS brick measurements multiplexer";
CM_ SG_ 1850 VC_LVBMS_brickVoltage1 "Voltage of a low voltage battery brick; raw 8191 = signal not available (SNA)";
CM_ SG_ 1850 VC_LVBMS_brickVoltage2 "Voltage of a low voltage battery brick; raw 8191 = signal not available (SNA)";
CM_ SG_ 1850 VC_LVBMS_brickVoltage3 "Voltage of a low voltage battery brick; raw 8191 = signal not available (SNA)";
CM_ SG_ 1850 VC_LVBMS_brickVoltage4 "Voltage of a low voltage battery brick; raw 8191 = signal not available (SNA)";
CM_ SG_ 1850 VC_LVBMS_brickBalancingAh1 "Ah count of a low voltage battery brick; raw 16777215 = signal not available (SNA)";
CM_ SG_ 1850 VC_LVBMS_brickBalancingAh2 "Ah count of a low voltage battery brick; raw 16777215 = signal not available (SNA)";
CM_ SG_ 1850 VC_LVBMS_brickBalancingState1 "VC ECU: LVBMS brick balancing state1";
CM_ SG_ 1850 VC_LVBMS_brickBalancingState2 "VC ECU: LVBMS brick balancing state2";
CM_ SG_ 1850 VC_LVBMS_brickBalancingAh3 "Ah count of a low voltage battery brick; raw 16777215 = signal not available (SNA)";
CM_ SG_ 1850 VC_LVBMS_brickBalancingAh4 "Ah count of a low voltage battery brick; raw 16777215 = signal not available (SNA)";
CM_ SG_ 1850 VC_LVBMS_brickBalancingState3 "VC ECU: LVBMS brick balancing state3";
CM_ SG_ 1850 VC_LVBMS_brickBalancingState4 "VC ECU: LVBMS brick balancing state4";
BA_DEF_ BO_ "GenMsgCycleTime" INT 0 3600000;
BA_DEF_ BO_ "GenMsgSendType" ENUM "Cyclic","NotUsed","NotUsed","NotUsed","NotUsed","NotUsed","NotUsed","IfActive","NoMsgSendType","NotUsed";
BA_DEF_ BO_ "VFrameFormat" ENUM "StandardCAN","ExtendedCAN","reserved","J1939PG","reserved","reserved","reserved","reserved","reserved","reserved","reserved","reserved","reserved","reserved","StandardCAN_FD","ExtendedCAN_FD";
BA_DEF_ BO_ "CANFD_BRS" ENUM "0","1";
BA_DEF_ SG_ "GenSigSNA" STRING;
BA_DEF_ SG_ "SystemSignalLongSymbol" STRING;
BA_DEF_ SG_ "Confidence" ENUM "validated","plausible","layout-only","contradicted";
BA_DEF_DEF_ "GenMsgCycleTime" 0;
BA_DEF_DEF_ "GenMsgSendType" "NoMsgSendType";
BA_DEF_DEF_ "VFrameFormat" "StandardCAN";
BA_DEF_DEF_ "CANFD_BRS" "1";
BA_DEF_DEF_ "GenSigSNA" "";
BA_DEF_DEF_ "SystemSignalLongSymbol" "";
BA_DEF_DEF_ "Confidence" "layout-only";
BA_ "GenMsgCycleTime" BO_ 857 100;
BA_ "GenMsgSendType" BO_ 857 0;
BA_ "GenMsgCycleTime" BO_ 1066 100;
BA_ "GenMsgSendType" BO_ 1066 0;
BA_ "GenMsgCycleTime" BO_ 602 1000;
BA_ "GenMsgSendType" BO_ 602 0;
BA_ "GenMsgCycleTime" BO_ 825 100;
BA_ "GenMsgSendType" BO_ 825 0;
BA_ "GenMsgCycleTime" BO_ 1824 10000;
BA_ "GenMsgSendType" BO_ 1824 0;
BA_ "GenMsgCycleTime" BO_ 793 1000;
BA_ "GenMsgSendType" BO_ 793 0;
BA_ "GenMsgCycleTime" BO_ 505 100;
BA_ "GenMsgSendType" BO_ 505 0;
BA_ "GenMsgCycleTime" BO_ 1850 1000;
BA_ "GenMsgSendType" BO_ 1850 0;
BA_ "Confidence" SG_ 857 VCSEC_DeviceStatusIndex 1;
BA_ "Confidence" SG_ 857 VCSEC_Device0AuthResponseTime 0;
BA_ "Confidence" SG_ 857 VCSEC_Device0Impermanent 0;
BA_ "Confidence" SG_ 857 VCSEC_Device0SELockedDown 0;
BA_ "Confidence" SG_ 857 VCSEC_Device0Version 0;
BA_ "Confidence" SG_ 857 VCSEC_Device0WLEntry 0;
BA_ "Confidence" SG_ 857 VCSEC_Device0OSVersion 0;
BA_ "Confidence" SG_ 857 VCSEC_Device0BatteryLevel 0;
BA_ "Confidence" SG_ 857 VCSEC_Device0Formfactor 0;
BA_ "Confidence" SG_ 857 VCSEC_Device0BlacklistStatus 0;
BA_ "Confidence" SG_ 857 VCSEC_Device0Stationary 0;
BA_ "Confidence" SG_ 857 VCSEC_Device0Bonded 0;
BA_ "Confidence" SG_ 857 VCSEC_Device0Role 0;
BA_ "Confidence" SG_ 857 VCSEC_Device0WhitelistActiveTime 0;
BA_ "Confidence" SG_ 857 VCSEC_Device0SHA1 0;
BA_ "Confidence" SG_ 857 VCSEC_Device0Permissions 0;
BA_ "Confidence" SG_ 857 VCSEC_Device0ManufacturerHashBit 0;
BA_ "SystemSignalLongSymbol" SG_ 857 VCSEC_Device0ManufacturerHashBit "VCSEC_Device0ManufacturerHashBits";
BA_ "Confidence" SG_ 857 VCSEC_Device0BuildNumberHashBits 0;
BA_ "Confidence" SG_ 857 VCSEC_Device1AuthResponseTime 0;
BA_ "GenSigSNA" SG_ 857 VCSEC_Device1AuthResponseTime "127";
BA_ "Confidence" SG_ 857 VCSEC_Device1Impermanent 0;
BA_ "Confidence" SG_ 857 VCSEC_Device1SELockedDown 0;
BA_ "Confidence" SG_ 857 VCSEC_Device1Version 0;
BA_ "Confidence" SG_ 857 VCSEC_Device1WLEntry 0;
BA_ "Confidence" SG_ 857 VCSEC_Device1OSVersion 0;
BA_ "Confidence" SG_ 857 VCSEC_Device1BatteryLevel 0;
BA_ "Confidence" SG_ 857 VCSEC_Device1Formfactor 0;
BA_ "Confidence" SG_ 857 VCSEC_Device1BlacklistStatus 0;
BA_ "Confidence" SG_ 857 VCSEC_Device1Stationary 0;
BA_ "Confidence" SG_ 857 VCSEC_Device1Bonded 0;
BA_ "Confidence" SG_ 857 VCSEC_Device1Role 0;
BA_ "Confidence" SG_ 857 VCSEC_Device1WhitelistActiveTime 0;
BA_ "Confidence" SG_ 857 VCSEC_Device1SHA1 0;
BA_ "Confidence" SG_ 857 VCSEC_Device1Permissions 0;
BA_ "Confidence" SG_ 857 VCSEC_Device1ManufacturerHashBit 0;
BA_ "SystemSignalLongSymbol" SG_ 857 VCSEC_Device1ManufacturerHashBit "VCSEC_Device1ManufacturerHashBits";
BA_ "Confidence" SG_ 857 VCSEC_Device1BuildNumberHashBits 0;
BA_ "Confidence" SG_ 857 VCSEC_Device2AuthResponseTime 0;
BA_ "GenSigSNA" SG_ 857 VCSEC_Device2AuthResponseTime "127";
BA_ "Confidence" SG_ 857 VCSEC_Device2Impermanent 0;
BA_ "Confidence" SG_ 857 VCSEC_Device2SELockedDown 0;
BA_ "Confidence" SG_ 857 VCSEC_Device2Version 0;
BA_ "Confidence" SG_ 857 VCSEC_Device2WLEntry 0;
BA_ "Confidence" SG_ 857 VCSEC_Device2OSVersion 0;
BA_ "Confidence" SG_ 857 VCSEC_Device2BatteryLevel 0;
BA_ "Confidence" SG_ 857 VCSEC_Device2Formfactor 0;
BA_ "Confidence" SG_ 857 VCSEC_Device2BlacklistStatus 0;
BA_ "Confidence" SG_ 857 VCSEC_Device2Stationary 0;
BA_ "Confidence" SG_ 857 VCSEC_Device2Bonded 0;
BA_ "Confidence" SG_ 857 VCSEC_Device2Role 0;
BA_ "Confidence" SG_ 857 VCSEC_Device2WhitelistActiveTime 0;
BA_ "Confidence" SG_ 857 VCSEC_Device2SHA1 0;
BA_ "Confidence" SG_ 857 VCSEC_Device2Permissions 0;
BA_ "Confidence" SG_ 857 VCSEC_Device2ManufacturerHashBit 0;
BA_ "SystemSignalLongSymbol" SG_ 857 VCSEC_Device2ManufacturerHashBit "VCSEC_Device2ManufacturerHashBits";
BA_ "Confidence" SG_ 857 VCSEC_Device2BuildNumberHashBits 0;
BA_ "Confidence" SG_ 857 VCSEC_Device3AuthResponseTime 0;
BA_ "GenSigSNA" SG_ 857 VCSEC_Device3AuthResponseTime "127";
BA_ "Confidence" SG_ 857 VCSEC_Device3Impermanent 0;
BA_ "Confidence" SG_ 857 VCSEC_Device3SELockedDown 0;
BA_ "Confidence" SG_ 857 VCSEC_Device3Version 0;
BA_ "Confidence" SG_ 857 VCSEC_Device3WLEntry 0;
BA_ "Confidence" SG_ 857 VCSEC_Device3OSVersion 0;
BA_ "Confidence" SG_ 857 VCSEC_Device3BatteryLevel 0;
BA_ "Confidence" SG_ 857 VCSEC_Device3Formfactor 0;
BA_ "Confidence" SG_ 857 VCSEC_Device3BlacklistStatus 0;
BA_ "Confidence" SG_ 857 VCSEC_Device3Stationary 0;
BA_ "Confidence" SG_ 857 VCSEC_Device3Bonded 0;
BA_ "Confidence" SG_ 857 VCSEC_Device3Role 0;
BA_ "Confidence" SG_ 857 VCSEC_Device3WhitelistActiveTime 0;
BA_ "Confidence" SG_ 857 VCSEC_Device3SHA1 0;
BA_ "Confidence" SG_ 857 VCSEC_Device3Permissions 0;
BA_ "Confidence" SG_ 857 VCSEC_Device3ManufacturerHashBit 0;
BA_ "SystemSignalLongSymbol" SG_ 857 VCSEC_Device3ManufacturerHashBit "VCSEC_Device3ManufacturerHashBits";
BA_ "Confidence" SG_ 857 VCSEC_Device3BuildNumberHashBits 0;
BA_ "Confidence" SG_ 857 VCSEC_Device4AuthResponseTime 0;
BA_ "GenSigSNA" SG_ 857 VCSEC_Device4AuthResponseTime "127";
BA_ "Confidence" SG_ 857 VCSEC_Device4Impermanent 0;
BA_ "Confidence" SG_ 857 VCSEC_Device4SELockedDown 0;
BA_ "Confidence" SG_ 857 VCSEC_Device4Version 0;
BA_ "Confidence" SG_ 857 VCSEC_Device4WLEntry 0;
BA_ "Confidence" SG_ 857 VCSEC_Device4OSVersion 0;
BA_ "Confidence" SG_ 857 VCSEC_Device4BatteryLevel 0;
BA_ "Confidence" SG_ 857 VCSEC_Device4Formfactor 0;
BA_ "Confidence" SG_ 857 VCSEC_Device4BlacklistStatus 0;
BA_ "Confidence" SG_ 857 VCSEC_Device4Stationary 0;
BA_ "Confidence" SG_ 857 VCSEC_Device4Bonded 0;
BA_ "Confidence" SG_ 857 VCSEC_Device4Role 0;
BA_ "Confidence" SG_ 857 VCSEC_Device4WhitelistActiveTime 0;
BA_ "Confidence" SG_ 857 VCSEC_Device4SHA1 0;
BA_ "Confidence" SG_ 857 VCSEC_Device4Permissions 0;
BA_ "Confidence" SG_ 857 VCSEC_Device4ManufacturerHashBit 0;
BA_ "SystemSignalLongSymbol" SG_ 857 VCSEC_Device4ManufacturerHashBit "VCSEC_Device4ManufacturerHashBits";
BA_ "Confidence" SG_ 857 VCSEC_Device4BuildNumberHashBits 0;
BA_ "Confidence" SG_ 857 VCSEC_Device5AuthResponseTime 0;
BA_ "GenSigSNA" SG_ 857 VCSEC_Device5AuthResponseTime "127";
BA_ "Confidence" SG_ 857 VCSEC_Device5Impermanent 0;
BA_ "Confidence" SG_ 857 VCSEC_Device5SELockedDown 0;
BA_ "Confidence" SG_ 857 VCSEC_Device5Version 0;
BA_ "Confidence" SG_ 857 VCSEC_Device5WLEntry 0;
BA_ "Confidence" SG_ 857 VCSEC_Device5OSVersion 0;
BA_ "Confidence" SG_ 857 VCSEC_Device5BatteryLevel 0;
BA_ "Confidence" SG_ 857 VCSEC_Device5Formfactor 0;
BA_ "Confidence" SG_ 857 VCSEC_Device5BlacklistStatus 0;
BA_ "Confidence" SG_ 857 VCSEC_Device5Stationary 0;
BA_ "Confidence" SG_ 857 VCSEC_Device5Bonded 0;
BA_ "Confidence" SG_ 857 VCSEC_Device5Role 0;
BA_ "Confidence" SG_ 857 VCSEC_Device5WhitelistActiveTime 0;
BA_ "Confidence" SG_ 857 VCSEC_Device5SHA1 0;
BA_ "Confidence" SG_ 857 VCSEC_Device5Permissions 0;
BA_ "Confidence" SG_ 857 VCSEC_Device5ManufacturerHashBit 0;
BA_ "SystemSignalLongSymbol" SG_ 857 VCSEC_Device5ManufacturerHashBit "VCSEC_Device5ManufacturerHashBits";
BA_ "Confidence" SG_ 857 VCSEC_Device5BuildNumberHashBits 0;
BA_ "Confidence" SG_ 857 VCSEC_Device6AuthResponseTime 0;
BA_ "GenSigSNA" SG_ 857 VCSEC_Device6AuthResponseTime "127";
BA_ "Confidence" SG_ 857 VCSEC_Device6Impermanent 0;
BA_ "Confidence" SG_ 857 VCSEC_Device6SELockedDown 0;
BA_ "Confidence" SG_ 857 VCSEC_Device6Version 0;
BA_ "Confidence" SG_ 857 VCSEC_Device6WLEntry 0;
BA_ "Confidence" SG_ 857 VCSEC_Device6OSVersion 0;
BA_ "Confidence" SG_ 857 VCSEC_Device6BatteryLevel 0;
BA_ "Confidence" SG_ 857 VCSEC_Device6Formfactor 0;
BA_ "Confidence" SG_ 857 VCSEC_Device6BlacklistStatus 0;
BA_ "Confidence" SG_ 857 VCSEC_Device6Stationary 0;
BA_ "Confidence" SG_ 857 VCSEC_Device6Bonded 0;
BA_ "Confidence" SG_ 857 VCSEC_Device6Role 0;
BA_ "Confidence" SG_ 857 VCSEC_Device6WhitelistActiveTime 0;
BA_ "Confidence" SG_ 857 VCSEC_Device6SHA1 0;
BA_ "Confidence" SG_ 857 VCSEC_Device6Permissions 0;
BA_ "Confidence" SG_ 857 VCSEC_Device6ManufacturerHashBit 0;
BA_ "SystemSignalLongSymbol" SG_ 857 VCSEC_Device6ManufacturerHashBit "VCSEC_Device6ManufacturerHashBits";
BA_ "Confidence" SG_ 857 VCSEC_Device6BuildNumberHashBits 0;
BA_ "Confidence" SG_ 857 VCSEC_Device7AuthResponseTime 0;
BA_ "GenSigSNA" SG_ 857 VCSEC_Device7AuthResponseTime "127";
BA_ "Confidence" SG_ 857 VCSEC_Device7Impermanent 0;
BA_ "Confidence" SG_ 857 VCSEC_Device7SELockedDown 0;
BA_ "Confidence" SG_ 857 VCSEC_Device7Version 0;
BA_ "Confidence" SG_ 857 VCSEC_Device7WLEntry 0;
BA_ "Confidence" SG_ 857 VCSEC_Device7OSVersion 0;
BA_ "Confidence" SG_ 857 VCSEC_Device7BatteryLevel 0;
BA_ "Confidence" SG_ 857 VCSEC_Device7Formfactor 0;
BA_ "Confidence" SG_ 857 VCSEC_Device7BlacklistStatus 0;
BA_ "Confidence" SG_ 857 VCSEC_Device7Stationary 0;
BA_ "Confidence" SG_ 857 VCSEC_Device7Bonded 0;
BA_ "Confidence" SG_ 857 VCSEC_Device7Role 0;
BA_ "Confidence" SG_ 857 VCSEC_Device7WhitelistActiveTime 0;
BA_ "Confidence" SG_ 857 VCSEC_Device7SHA1 0;
BA_ "Confidence" SG_ 857 VCSEC_Device7Permissions 0;
BA_ "Confidence" SG_ 857 VCSEC_Device7ManufacturerHashBit 0;
BA_ "SystemSignalLongSymbol" SG_ 857 VCSEC_Device7ManufacturerHashBit "VCSEC_Device7ManufacturerHashBits";
BA_ "Confidence" SG_ 857 VCSEC_Device7BuildNumberHashBits 0;
BA_ "Confidence" SG_ 857 VCSEC_Device8AuthResponseTime 0;
BA_ "GenSigSNA" SG_ 857 VCSEC_Device8AuthResponseTime "127";
BA_ "Confidence" SG_ 857 VCSEC_Device8Impermanent 0;
BA_ "Confidence" SG_ 857 VCSEC_Device8SELockedDown 0;
BA_ "Confidence" SG_ 857 VCSEC_Device8Version 0;
BA_ "Confidence" SG_ 857 VCSEC_Device8WLEntry 0;
BA_ "Confidence" SG_ 857 VCSEC_Device8OSVersion 0;
BA_ "Confidence" SG_ 857 VCSEC_Device8BatteryLevel 0;
BA_ "Confidence" SG_ 857 VCSEC_Device8Formfactor 0;
BA_ "Confidence" SG_ 857 VCSEC_Device8BlacklistStatus 0;
BA_ "Confidence" SG_ 857 VCSEC_Device8Stationary 0;
BA_ "Confidence" SG_ 857 VCSEC_Device8Bonded 0;
BA_ "Confidence" SG_ 857 VCSEC_Device8Role 0;
BA_ "Confidence" SG_ 857 VCSEC_Device8WhitelistActiveTime 0;
BA_ "Confidence" SG_ 857 VCSEC_Device8SHA1 0;
BA_ "Confidence" SG_ 857 VCSEC_Device8Permissions 0;
BA_ "Confidence" SG_ 857 VCSEC_Device8ManufacturerHashBit 0;
BA_ "SystemSignalLongSymbol" SG_ 857 VCSEC_Device8ManufacturerHashBit "VCSEC_Device8ManufacturerHashBits";
BA_ "Confidence" SG_ 857 VCSEC_Device8BuildNumberHashBits 0;
BA_ "Confidence" SG_ 857 VCSEC_Device9AuthResponseTime 0;
BA_ "GenSigSNA" SG_ 857 VCSEC_Device9AuthResponseTime "127";
BA_ "Confidence" SG_ 857 VCSEC_Device9Impermanent 0;
BA_ "Confidence" SG_ 857 VCSEC_Device9SELockedDown 0;
BA_ "Confidence" SG_ 857 VCSEC_Device9Version 0;
BA_ "Confidence" SG_ 857 VCSEC_Device9WLEntry 0;
BA_ "Confidence" SG_ 857 VCSEC_Device9OSVersion 0;
BA_ "Confidence" SG_ 857 VCSEC_Device9BatteryLevel 0;
BA_ "Confidence" SG_ 857 VCSEC_Device9Formfactor 0;
BA_ "Confidence" SG_ 857 VCSEC_Device9BlacklistStatus 0;
BA_ "Confidence" SG_ 857 VCSEC_Device9Stationary 0;
BA_ "Confidence" SG_ 857 VCSEC_Device9Bonded 0;
BA_ "Confidence" SG_ 857 VCSEC_Device9Role 0;
BA_ "Confidence" SG_ 857 VCSEC_Device9WhitelistActiveTime 0;
BA_ "Confidence" SG_ 857 VCSEC_Device9SHA1 0;
BA_ "Confidence" SG_ 857 VCSEC_Device9Permissions 0;
BA_ "Confidence" SG_ 857 VCSEC_Device9ManufacturerHashBit 0;
BA_ "SystemSignalLongSymbol" SG_ 857 VCSEC_Device9ManufacturerHashBit "VCSEC_Device9ManufacturerHashBits";
BA_ "Confidence" SG_ 857 VCSEC_Device9BuildNumberHashBits 0;
BA_ "Confidence" SG_ 857 VCSEC_Device10AuthResponseTime 0;
BA_ "GenSigSNA" SG_ 857 VCSEC_Device10AuthResponseTime "127";
BA_ "Confidence" SG_ 857 VCSEC_Device10Impermanent 0;
BA_ "Confidence" SG_ 857 VCSEC_Device10SELockedDown 0;
BA_ "Confidence" SG_ 857 VCSEC_Device10Version 0;
BA_ "Confidence" SG_ 857 VCSEC_Device10WLEntry 0;
BA_ "Confidence" SG_ 857 VCSEC_Device10OSVersion 0;
BA_ "Confidence" SG_ 857 VCSEC_Device10BatteryLevel 0;
BA_ "Confidence" SG_ 857 VCSEC_Device10Formfactor 0;
BA_ "Confidence" SG_ 857 VCSEC_Device10BlacklistStatus 0;
BA_ "Confidence" SG_ 857 VCSEC_Device10Stationary 0;
BA_ "Confidence" SG_ 857 VCSEC_Device10Bonded 0;
BA_ "Confidence" SG_ 857 VCSEC_Device10Role 0;
BA_ "Confidence" SG_ 857 VCSEC_Device10WhitelistActiveTim 0;
BA_ "SystemSignalLongSymbol" SG_ 857 VCSEC_Device10WhitelistActiveTim "VCSEC_Device10WhitelistActiveTime";
BA_ "Confidence" SG_ 857 VCSEC_Device10SHA1 0;
BA_ "Confidence" SG_ 857 VCSEC_Device10Permissions 0;
BA_ "Confidence" SG_ 857 VCSEC_Device10ManufacturerHashBi 0;
BA_ "SystemSignalLongSymbol" SG_ 857 VCSEC_Device10ManufacturerHashBi "VCSEC_Device10ManufacturerHashBits";
BA_ "Confidence" SG_ 857 VCSEC_Device10BuildNumberHashBit 0;
BA_ "SystemSignalLongSymbol" SG_ 857 VCSEC_Device10BuildNumberHashBit "VCSEC_Device10BuildNumberHashBits";
BA_ "Confidence" SG_ 857 VCSEC_Device11AuthResponseTime 0;
BA_ "GenSigSNA" SG_ 857 VCSEC_Device11AuthResponseTime "127";
BA_ "Confidence" SG_ 857 VCSEC_Device11Impermanent 0;
BA_ "Confidence" SG_ 857 VCSEC_Device11SELockedDown 0;
BA_ "Confidence" SG_ 857 VCSEC_Device11Version 0;
BA_ "Confidence" SG_ 857 VCSEC_Device11WLEntry 0;
BA_ "Confidence" SG_ 857 VCSEC_Device11OSVersion 0;
BA_ "Confidence" SG_ 857 VCSEC_Device11BatteryLevel 0;
BA_ "Confidence" SG_ 857 VCSEC_Device11Formfactor 0;
BA_ "Confidence" SG_ 857 VCSEC_Device11BlacklistStatus 0;
BA_ "Confidence" SG_ 857 VCSEC_Device11Stationary 0;
BA_ "Confidence" SG_ 857 VCSEC_Device11Bonded 0;
BA_ "Confidence" SG_ 857 VCSEC_Device11Role 0;
BA_ "Confidence" SG_ 857 VCSEC_Device11WhitelistActiveTim 0;
BA_ "SystemSignalLongSymbol" SG_ 857 VCSEC_Device11WhitelistActiveTim "VCSEC_Device11WhitelistActiveTime";
BA_ "Confidence" SG_ 857 VCSEC_Device11SHA1 0;
BA_ "Confidence" SG_ 857 VCSEC_Device11Permissions 0;
BA_ "Confidence" SG_ 857 VCSEC_Device11ManufacturerHashBi 0;
BA_ "SystemSignalLongSymbol" SG_ 857 VCSEC_Device11ManufacturerHashBi "VCSEC_Device11ManufacturerHashBits";
BA_ "Confidence" SG_ 857 VCSEC_Device11BuildNumberHashBit 0;
BA_ "SystemSignalLongSymbol" SG_ 857 VCSEC_Device11BuildNumberHashBit "VCSEC_Device11BuildNumberHashBits";
BA_ "Confidence" SG_ 857 VCSEC_Device12AuthResponseTime 0;
BA_ "GenSigSNA" SG_ 857 VCSEC_Device12AuthResponseTime "127";
BA_ "Confidence" SG_ 857 VCSEC_Device12Impermanent 0;
BA_ "Confidence" SG_ 857 VCSEC_Device12SELockedDown 0;
BA_ "Confidence" SG_ 857 VCSEC_Device12Version 0;
BA_ "Confidence" SG_ 857 VCSEC_Device12WLEntry 0;
BA_ "Confidence" SG_ 857 VCSEC_Device12OSVersion 0;
BA_ "Confidence" SG_ 857 VCSEC_Device12BatteryLevel 0;
BA_ "Confidence" SG_ 857 VCSEC_Device12Formfactor 0;
BA_ "Confidence" SG_ 857 VCSEC_Device12BlacklistStatus 0;
BA_ "Confidence" SG_ 857 VCSEC_Device12Stationary 0;
BA_ "Confidence" SG_ 857 VCSEC_Device12Bonded 0;
BA_ "Confidence" SG_ 857 VCSEC_Device12Role 0;
BA_ "Confidence" SG_ 857 VCSEC_Device12WhitelistActiveTim 0;
BA_ "SystemSignalLongSymbol" SG_ 857 VCSEC_Device12WhitelistActiveTim "VCSEC_Device12WhitelistActiveTime";
BA_ "Confidence" SG_ 857 VCSEC_Device12SHA1 0;
BA_ "Confidence" SG_ 857 VCSEC_Device12Permissions 0;
BA_ "Confidence" SG_ 857 VCSEC_Device12ManufacturerHashBi 0;
BA_ "SystemSignalLongSymbol" SG_ 857 VCSEC_Device12ManufacturerHashBi "VCSEC_Device12ManufacturerHashBits";
BA_ "Confidence" SG_ 857 VCSEC_Device12BuildNumberHashBit 0;
BA_ "SystemSignalLongSymbol" SG_ 857 VCSEC_Device12BuildNumberHashBit "VCSEC_Device12BuildNumberHashBits";
BA_ "Confidence" SG_ 857 VCSEC_Device13AuthResponseTime 0;
BA_ "GenSigSNA" SG_ 857 VCSEC_Device13AuthResponseTime "127";
BA_ "Confidence" SG_ 857 VCSEC_Device13Impermanent 0;
BA_ "Confidence" SG_ 857 VCSEC_Device13SELockedDown 0;
BA_ "Confidence" SG_ 857 VCSEC_Device13Version 0;
BA_ "Confidence" SG_ 857 VCSEC_Device13WLEntry 0;
BA_ "Confidence" SG_ 857 VCSEC_Device13OSVersion 0;
BA_ "Confidence" SG_ 857 VCSEC_Device13BatteryLevel 0;
BA_ "Confidence" SG_ 857 VCSEC_Device13Formfactor 0;
BA_ "Confidence" SG_ 857 VCSEC_Device13BlacklistStatus 0;
BA_ "Confidence" SG_ 857 VCSEC_Device13Stationary 0;
BA_ "Confidence" SG_ 857 VCSEC_Device13Bonded 0;
BA_ "Confidence" SG_ 857 VCSEC_Device13Role 0;
BA_ "Confidence" SG_ 857 VCSEC_Device13WhitelistActiveTim 0;
BA_ "SystemSignalLongSymbol" SG_ 857 VCSEC_Device13WhitelistActiveTim "VCSEC_Device13WhitelistActiveTime";
BA_ "Confidence" SG_ 857 VCSEC_Device13SHA1 0;
BA_ "Confidence" SG_ 857 VCSEC_Device13Permissions 0;
BA_ "Confidence" SG_ 857 VCSEC_Device13ManufacturerHashBi 0;
BA_ "SystemSignalLongSymbol" SG_ 857 VCSEC_Device13ManufacturerHashBi "VCSEC_Device13ManufacturerHashBits";
BA_ "Confidence" SG_ 857 VCSEC_Device13BuildNumberHashBit 0;
BA_ "SystemSignalLongSymbol" SG_ 857 VCSEC_Device13BuildNumberHashBit "VCSEC_Device13BuildNumberHashBits";
BA_ "Confidence" SG_ 857 VCSEC_Device14AuthResponseTime 0;
BA_ "GenSigSNA" SG_ 857 VCSEC_Device14AuthResponseTime "127";
BA_ "Confidence" SG_ 857 VCSEC_Device14Impermanent 0;
BA_ "Confidence" SG_ 857 VCSEC_Device14SELockedDown 0;
BA_ "Confidence" SG_ 857 VCSEC_Device14Version 0;
BA_ "Confidence" SG_ 857 VCSEC_Device14WLEntry 0;
BA_ "Confidence" SG_ 857 VCSEC_Device14OSVersion 0;
BA_ "Confidence" SG_ 857 VCSEC_Device14BatteryLevel 0;
BA_ "Confidence" SG_ 857 VCSEC_Device14Formfactor 0;
BA_ "Confidence" SG_ 857 VCSEC_Device14BlacklistStatus 0;
BA_ "Confidence" SG_ 857 VCSEC_Device14Stationary 0;
BA_ "Confidence" SG_ 857 VCSEC_Device14Bonded 0;
BA_ "Confidence" SG_ 857 VCSEC_Device14Role 0;
BA_ "Confidence" SG_ 857 VCSEC_Device14WhitelistActiveTim 0;
BA_ "SystemSignalLongSymbol" SG_ 857 VCSEC_Device14WhitelistActiveTim "VCSEC_Device14WhitelistActiveTime";
BA_ "Confidence" SG_ 857 VCSEC_Device14SHA1 0;
BA_ "Confidence" SG_ 857 VCSEC_Device14Permissions 0;
BA_ "Confidence" SG_ 857 VCSEC_Device14ManufacturerHashBi 0;
BA_ "SystemSignalLongSymbol" SG_ 857 VCSEC_Device14ManufacturerHashBi "VCSEC_Device14ManufacturerHashBits";
BA_ "Confidence" SG_ 857 VCSEC_Device14BuildNumberHashBit 0;
BA_ "SystemSignalLongSymbol" SG_ 857 VCSEC_Device14BuildNumberHashBit "VCSEC_Device14BuildNumberHashBits";
BA_ "Confidence" SG_ 857 VCSEC_Device15AuthResponseTime 0;
BA_ "GenSigSNA" SG_ 857 VCSEC_Device15AuthResponseTime "127";
BA_ "Confidence" SG_ 857 VCSEC_Device15Impermanent 0;
BA_ "Confidence" SG_ 857 VCSEC_Device15SELockedDown 0;
BA_ "Confidence" SG_ 857 VCSEC_Device15Version 0;
BA_ "Confidence" SG_ 857 VCSEC_Device15WLEntry 0;
BA_ "Confidence" SG_ 857 VCSEC_Device15OSVersion 0;
BA_ "Confidence" SG_ 857 VCSEC_Device15BatteryLevel 0;
BA_ "Confidence" SG_ 857 VCSEC_Device15Formfactor 0;
BA_ "Confidence" SG_ 857 VCSEC_Device15BlacklistStatus 0;
BA_ "Confidence" SG_ 857 VCSEC_Device15Stationary 0;
BA_ "Confidence" SG_ 857 VCSEC_Device15Bonded 0;
BA_ "Confidence" SG_ 857 VCSEC_Device15Role 0;
BA_ "Confidence" SG_ 857 VCSEC_Device15WhitelistActiveTim 0;
BA_ "SystemSignalLongSymbol" SG_ 857 VCSEC_Device15WhitelistActiveTim "VCSEC_Device15WhitelistActiveTime";
BA_ "Confidence" SG_ 857 VCSEC_Device15SHA1 0;
BA_ "Confidence" SG_ 857 VCSEC_Device15Permissions 0;
BA_ "Confidence" SG_ 857 VCSEC_Device15ManufacturerHashBi 0;
BA_ "SystemSignalLongSymbol" SG_ 857 VCSEC_Device15ManufacturerHashBi "VCSEC_Device15ManufacturerHashBits";
BA_ "Confidence" SG_ 857 VCSEC_Device15BuildNumberHashBit 0;
BA_ "SystemSignalLongSymbol" SG_ 857 VCSEC_Device15BuildNumberHashBit "VCSEC_Device15BuildNumberHashBits";
BA_ "Confidence" SG_ 857 VCSEC_Device16AuthResponseTime 0;
BA_ "GenSigSNA" SG_ 857 VCSEC_Device16AuthResponseTime "127";
BA_ "Confidence" SG_ 857 VCSEC_Device16Impermanent 0;
BA_ "Confidence" SG_ 857 VCSEC_Device16SELockedDown 0;
BA_ "Confidence" SG_ 857 VCSEC_Device16Version 0;
BA_ "Confidence" SG_ 857 VCSEC_Device16WLEntry 0;
BA_ "Confidence" SG_ 857 VCSEC_Device16OSVersion 0;
BA_ "Confidence" SG_ 857 VCSEC_Device16BatteryLevel 0;
BA_ "Confidence" SG_ 857 VCSEC_Device16Formfactor 0;
BA_ "Confidence" SG_ 857 VCSEC_Device16BlacklistStatus 0;
BA_ "Confidence" SG_ 857 VCSEC_Device16Stationary 0;
BA_ "Confidence" SG_ 857 VCSEC_Device16Bonded 0;
BA_ "Confidence" SG_ 857 VCSEC_Device16Role 0;
BA_ "Confidence" SG_ 857 VCSEC_Device16WhitelistActiveTim 0;
BA_ "SystemSignalLongSymbol" SG_ 857 VCSEC_Device16WhitelistActiveTim "VCSEC_Device16WhitelistActiveTime";
BA_ "Confidence" SG_ 857 VCSEC_Device16SHA1 0;
BA_ "Confidence" SG_ 857 VCSEC_Device16Permissions 0;
BA_ "Confidence" SG_ 857 VCSEC_Device16ManufacturerHashBi 0;
BA_ "SystemSignalLongSymbol" SG_ 857 VCSEC_Device16ManufacturerHashBi "VCSEC_Device16ManufacturerHashBits";
BA_ "Confidence" SG_ 857 VCSEC_Device16BuildNumberHashBit 0;
BA_ "SystemSignalLongSymbol" SG_ 857 VCSEC_Device16BuildNumberHashBit "VCSEC_Device16BuildNumberHashBits";
BA_ "Confidence" SG_ 857 VCSEC_Device17AuthResponseTime 0;
BA_ "GenSigSNA" SG_ 857 VCSEC_Device17AuthResponseTime "127";
BA_ "Confidence" SG_ 857 VCSEC_Device17Impermanent 0;
BA_ "Confidence" SG_ 857 VCSEC_Device17SELockedDown 0;
BA_ "Confidence" SG_ 857 VCSEC_Device17Version 0;
BA_ "Confidence" SG_ 857 VCSEC_Device17WLEntry 0;
BA_ "Confidence" SG_ 857 VCSEC_Device17OSVersion 0;
BA_ "Confidence" SG_ 857 VCSEC_Device17BatteryLevel 0;
BA_ "Confidence" SG_ 857 VCSEC_Device17Formfactor 0;
BA_ "Confidence" SG_ 857 VCSEC_Device17BlacklistStatus 0;
BA_ "Confidence" SG_ 857 VCSEC_Device17Stationary 0;
BA_ "Confidence" SG_ 857 VCSEC_Device17Bonded 0;
BA_ "Confidence" SG_ 857 VCSEC_Device17Role 0;
BA_ "Confidence" SG_ 857 VCSEC_Device17WhitelistActiveTim 0;
BA_ "SystemSignalLongSymbol" SG_ 857 VCSEC_Device17WhitelistActiveTim "VCSEC_Device17WhitelistActiveTime";
BA_ "Confidence" SG_ 857 VCSEC_Device17SHA1 0;
BA_ "Confidence" SG_ 857 VCSEC_Device17Permissions 0;
BA_ "Confidence" SG_ 857 VCSEC_Device17ManufacturerHashBi 0;
BA_ "SystemSignalLongSymbol" SG_ 857 VCSEC_Device17ManufacturerHashBi "VCSEC_Device17ManufacturerHashBits";
BA_ "Confidence" SG_ 857 VCSEC_Device17BuildNumberHashBit 0;
BA_ "SystemSignalLongSymbol" SG_ 857 VCSEC_Device17BuildNumberHashBit "VCSEC_Device17BuildNumberHashBits";
BA_ "Confidence" SG_ 857 VCSEC_Device18AuthResponseTime 0;
BA_ "GenSigSNA" SG_ 857 VCSEC_Device18AuthResponseTime "127";
BA_ "Confidence" SG_ 857 VCSEC_Device18Impermanent 0;
BA_ "Confidence" SG_ 857 VCSEC_Device18SELockedDown 0;
BA_ "Confidence" SG_ 857 VCSEC_Device18Version 0;
BA_ "Confidence" SG_ 857 VCSEC_Device18WLEntry 0;
BA_ "Confidence" SG_ 857 VCSEC_Device18OSVersion 0;
BA_ "Confidence" SG_ 857 VCSEC_Device18BatteryLevel 0;
BA_ "Confidence" SG_ 857 VCSEC_Device18Formfactor 0;
BA_ "Confidence" SG_ 857 VCSEC_Device18BlacklistStatus 0;
BA_ "Confidence" SG_ 857 VCSEC_Device18Stationary 0;
BA_ "Confidence" SG_ 857 VCSEC_Device18Bonded 0;
BA_ "Confidence" SG_ 857 VCSEC_Device18Role 0;
BA_ "Confidence" SG_ 857 VCSEC_Device18WhitelistActiveTim 0;
BA_ "SystemSignalLongSymbol" SG_ 857 VCSEC_Device18WhitelistActiveTim "VCSEC_Device18WhitelistActiveTime";
BA_ "Confidence" SG_ 857 VCSEC_Device18SHA1 0;
BA_ "Confidence" SG_ 857 VCSEC_Device18Permissions 0;
BA_ "Confidence" SG_ 857 VCSEC_Device18ManufacturerHashBi 0;
BA_ "SystemSignalLongSymbol" SG_ 857 VCSEC_Device18ManufacturerHashBi "VCSEC_Device18ManufacturerHashBits";
BA_ "Confidence" SG_ 857 VCSEC_Device18BuildNumberHashBit 0;
BA_ "SystemSignalLongSymbol" SG_ 857 VCSEC_Device18BuildNumberHashBit "VCSEC_Device18BuildNumberHashBits";
BA_ "Confidence" SG_ 857 VCSEC_Device19AuthResponseTime 0;
BA_ "GenSigSNA" SG_ 857 VCSEC_Device19AuthResponseTime "127";
BA_ "Confidence" SG_ 857 VCSEC_Device19Impermanent 0;
BA_ "Confidence" SG_ 857 VCSEC_Device19SELockedDown 0;
BA_ "Confidence" SG_ 857 VCSEC_Device19Version 0;
BA_ "Confidence" SG_ 857 VCSEC_Device19WLEntry 0;
BA_ "Confidence" SG_ 857 VCSEC_Device19OSVersion 0;
BA_ "Confidence" SG_ 857 VCSEC_Device19BatteryLevel 0;
BA_ "Confidence" SG_ 857 VCSEC_Device19Formfactor 0;
BA_ "Confidence" SG_ 857 VCSEC_Device19BlacklistStatus 0;
BA_ "Confidence" SG_ 857 VCSEC_Device19Stationary 0;
BA_ "Confidence" SG_ 857 VCSEC_Device19Bonded 0;
BA_ "Confidence" SG_ 857 VCSEC_Device19Role 0;
BA_ "Confidence" SG_ 857 VCSEC_Device19WhitelistActiveTim 0;
BA_ "SystemSignalLongSymbol" SG_ 857 VCSEC_Device19WhitelistActiveTim "VCSEC_Device19WhitelistActiveTime";
BA_ "Confidence" SG_ 857 VCSEC_Device19SHA1 0;
BA_ "Confidence" SG_ 857 VCSEC_Device19Permissions 0;
BA_ "Confidence" SG_ 857 VCSEC_Device19ManufacturerHashBi 0;
BA_ "SystemSignalLongSymbol" SG_ 857 VCSEC_Device19ManufacturerHashBi "VCSEC_Device19ManufacturerHashBits";
BA_ "Confidence" SG_ 857 VCSEC_Device19BuildNumberHashBit 0;
BA_ "SystemSignalLongSymbol" SG_ 857 VCSEC_Device19BuildNumberHashBit "VCSEC_Device19BuildNumberHashBits";
BA_ "Confidence" SG_ 473 VCSEC_IsoTpUDPPipeUI0 0;
BA_ "Confidence" SG_ 473 VCSEC_IsoTpUDPPipeUI1 0;
BA_ "Confidence" SG_ 473 VCSEC_IsoTpUDPPipeUI2 0;
BA_ "Confidence" SG_ 473 VCSEC_IsoTpUDPPipeUI3 0;
BA_ "Confidence" SG_ 473 VCSEC_IsoTpUDPPipeUI4 0;
BA_ "Confidence" SG_ 473 VCSEC_IsoTpUDPPipeUI5 0;
BA_ "Confidence" SG_ 473 VCSEC_IsoTpUDPPipeUI6 0;
BA_ "Confidence" SG_ 473 VCSEC_IsoTpUDPPipeUI7 0;
BA_ "Confidence" SG_ 1066 VCSEC_TPMSSensorState0 0;
BA_ "Confidence" SG_ 1066 VCSEC_TPMSRSSI0 0;
BA_ "Confidence" SG_ 1066 VCSEC_TPMSConnectionTypeCurrent0 0;
BA_ "Confidence" SG_ 1066 VCSEC_TPMSConnectionTypeDesired0 0;
BA_ "Confidence" SG_ 1066 VCSEC_TPMSSensorState1 0;
BA_ "Confidence" SG_ 1066 VCSEC_TPMSRSSI1 0;
BA_ "Confidence" SG_ 1066 VCSEC_TPMSConnectionTypeCurrent1 0;
BA_ "Confidence" SG_ 1066 VCSEC_TPMSConnectionTypeDesired1 0;
BA_ "Confidence" SG_ 1066 VCSEC_TPMSSensorState2 0;
BA_ "Confidence" SG_ 1066 VCSEC_TPMSRSSI2 0;
BA_ "Confidence" SG_ 1066 VCSEC_TPMSConnectionTypeCurrent2 0;
BA_ "Confidence" SG_ 1066 VCSEC_TPMSConnectionTypeDesired2 0;
BA_ "Confidence" SG_ 1066 VCSEC_TPMSSensorState3 0;
BA_ "Confidence" SG_ 1066 VCSEC_TPMSRSSI3 0;
BA_ "Confidence" SG_ 1066 VCSEC_TPMSConnectionTypeCurrent3 0;
BA_ "Confidence" SG_ 1066 VCSEC_TPMSConnectionTypeDesired3 0;
BA_ "Confidence" SG_ 1066 VCSEC_TPMSSensorPresence0 0;
BA_ "Confidence" SG_ 1066 VCSEC_TPMSSensorPresence1 0;
BA_ "Confidence" SG_ 1066 VCSEC_TPMSSensorPresence2 0;
BA_ "Confidence" SG_ 1066 VCSEC_TPMSSensorPresence3 0;
BA_ "Confidence" SG_ 602 VCSEC_TPMSDisplayPressureFL 0;
BA_ "GenSigSNA" SG_ 602 VCSEC_TPMSDisplayPressureFL "255";
BA_ "Confidence" SG_ 602 VCSEC_TPMSDisplayPressureFR 0;
BA_ "GenSigSNA" SG_ 602 VCSEC_TPMSDisplayPressureFR "255";
BA_ "Confidence" SG_ 602 VCSEC_TPMSDisplayPressureRL 0;
BA_ "GenSigSNA" SG_ 602 VCSEC_TPMSDisplayPressureRL "255";
BA_ "Confidence" SG_ 602 VCSEC_TPMSDisplayPressureRR 0;
BA_ "GenSigSNA" SG_ 602 VCSEC_TPMSDisplayPressureRR "255";
BA_ "Confidence" SG_ 602 VCSEC_TPMSTellTale 0;
BA_ "Confidence" SG_ 602 VCSEC_TPMSDisplaySoftWarningIndi 0;
BA_ "SystemSignalLongSymbol" SG_ 602 VCSEC_TPMSDisplaySoftWarningIndi "VCSEC_TPMSDisplaySoftWarningIndicationFL";
BA_ "Confidence" SG_ 602 VCSEC_TPMSDisplaySoftWarnin_0001 0;
BA_ "SystemSignalLongSymbol" SG_ 602 VCSEC_TPMSDisplaySoftWarnin_0001 "VCSEC_TPMSDisplaySoftWarningIndicationFR";
BA_ "Confidence" SG_ 602 VCSEC_TPMSDisplaySoftWarnin_0002 0;
BA_ "SystemSignalLongSymbol" SG_ 602 VCSEC_TPMSDisplaySoftWarnin_0002 "VCSEC_TPMSDisplaySoftWarningIndicationRL";
BA_ "Confidence" SG_ 602 VCSEC_TPMSDisplaySoftWarnin_0003 0;
BA_ "SystemSignalLongSymbol" SG_ 602 VCSEC_TPMSDisplaySoftWarnin_0003 "VCSEC_TPMSDisplaySoftWarningIndicationRR";
BA_ "Confidence" SG_ 602 VCSEC_TPMSDisplayHardWarningIndi 0;
BA_ "SystemSignalLongSymbol" SG_ 602 VCSEC_TPMSDisplayHardWarningIndi "VCSEC_TPMSDisplayHardWarningIndicationFL";
BA_ "Confidence" SG_ 602 VCSEC_TPMSDisplayHardWarnin_0001 0;
BA_ "SystemSignalLongSymbol" SG_ 602 VCSEC_TPMSDisplayHardWarnin_0001 "VCSEC_TPMSDisplayHardWarningIndicationFR";
BA_ "Confidence" SG_ 602 VCSEC_TPMSDisplayHardWarnin_0002 0;
BA_ "SystemSignalLongSymbol" SG_ 602 VCSEC_TPMSDisplayHardWarnin_0002 "VCSEC_TPMSDisplayHardWarningIndicationRL";
BA_ "Confidence" SG_ 602 VCSEC_TPMSDisplayHardWarnin_0003 0;
BA_ "SystemSignalLongSymbol" SG_ 602 VCSEC_TPMSDisplayHardWarnin_0003 "VCSEC_TPMSDisplayHardWarningIndicationRR";
BA_ "Confidence" SG_ 825 VCSEC_BLEConnectionCounter 0;
BA_ "Confidence" SG_ 825 VCSEC_authRejectionReason 0;
BA_ "Confidence" SG_ 825 VCSEC_IDRequested 0;
BA_ "Confidence" SG_ 825 VCSEC_operationMode 0;
BA_ "Confidence" SG_ 825 VCSEC_vehicleLockStatus 0;
BA_ "GenSigSNA" SG_ 825 VCSEC_vehicleLockStatus "0";
BA_ "Confidence" SG_ 825 VCSEC_authenticationStatus 0;
BA_ "Confidence" SG_ 825 VCSEC_chargePortLockStatus 0;
BA_ "Confidence" SG_ 825 VCSEC_leftFrontLockStatus 0;
BA_ "Confidence" SG_ 825 VCSEC_leftRearLockStatus 0;
BA_ "Confidence" SG_ 825 VCSEC_rightFrontLockStatus 0;
BA_ "Confidence" SG_ 825 VCSEC_rightRearLockStatus 0;
BA_ "Confidence" SG_ 825 VCSEC_trunkLockStatus 0;
BA_ "Confidence" SG_ 825 VCSEC_lockRequestType 0;
BA_ "Confidence" SG_ 825 VCSEC_summonRequest 0;
BA_ "GenSigSNA" SG_ 825 VCSEC_summonRequest "5";
BA_ "Confidence" SG_ 825 VCSEC_3rdPartyPLGRequest 0;
BA_ "GenSigSNA" SG_ 825 VCSEC_3rdPartyPLGRequest "3";
BA_ "Confidence" SG_ 825 VCSEC_3rdPartyFrunkPLGRequest 0;
BA_ "GenSigSNA" SG_ 825 VCSEC_3rdPartyFrunkPLGRequest "3";
BA_ "Confidence" SG_ 825 VCSEC_MCUCommandType 0;
BA_ "Confidence" SG_ 825 VCSEC_frunkLockStatus 0;
BA_ "Confidence" SG_ 825 VCSEC_usingModifiedMACAddress 0;
BA_ "Confidence" SG_ 825 VCSEC_isKeyWithinSummonRange 0;
BA_ "Confidence" SG_ 825 VCSEC_isBLEDeviceWithinSummonRan 0;
BA_ "SystemSignalLongSymbol" SG_ 825 VCSEC_isBLEDeviceWithinSummonRan "VCSEC_isBLEDeviceWithinSummonRange";
BA_ "Confidence" SG_ 825 VCSEC_alarmStatus 0;
BA_ "GenSigSNA" SG_ 825 VCSEC_alarmStatus "15";
BA_ "Confidence" SG_ 825 VCSEC_serviceDiagnosticRequest 0;
BA_ "Confidence" SG_ 825 VCSEC_immobilizerState 0;
BA_ "Confidence" SG_ 825 VCSEC_lockIndicationRequest 0;
BA_ "GenSigSNA" SG_ 825 VCSEC_lockIndicationRequest "0";
BA_ "Confidence" SG_ 825 VCSEC_simpleLockStatus 0;
BA_ "GenSigSNA" SG_ 825 VCSEC_simpleLockStatus "0";
BA_ "Confidence" SG_ 825 VCSEC_keyChannelIndexed 0;
BA_ "GenSigSNA" SG_ 825 VCSEC_keyChannelIndexed "15";
BA_ "Confidence" SG_ 825 VCSEC_authRequested 0;
BA_ "Confidence" SG_ 825 VCSEC_remoteStartActive 0;
BA_ "Confidence" SG_ 825 VCSEC_keyPairDesired 0;
BA_ "Confidence" SG_ 1824 VCSEC_ECUConfigCRC32 0;
BA_ "Confidence" SG_ 1824 VCSEC_autoWriteConfig 0;
BA_ "Confidence" SG_ 1824 VCSEC_requestForConfig 0;
BA_ "Confidence" SG_ 793 VCSEC_infoIndex 1;
BA_ "Confidence" SG_ 793 VCSEC_infoBuildType 0;
BA_ "Confidence" SG_ 793 VCSEC_infoBuildConfigId 0;
BA_ "Confidence" SG_ 793 VCSEC_infoHardwareId 0;
BA_ "Confidence" SG_ 793 VCSEC_infoComponentId 0;
BA_ "Confidence" SG_ 793 VCSEC_infoPcbaId 0;
BA_ "Confidence" SG_ 793 VCSEC_infoAssemblyId 0;
BA_ "GenSigSNA" SG_ 793 VCSEC_infoAssemblyId "255";
BA_ "Confidence" SG_ 793 VCSEC_infoUsageId 0;
BA_ "Confidence" SG_ 793 VCSEC_infoSubUsageId 0;
BA_ "Confidence" SG_ 793 VCSEC_infoAppCrc 0;
BA_ "Confidence" SG_ 793 VCSEC_infoSubcomponent1 0;
BA_ "Confidence" SG_ 793 VCSEC_infoAppGitHash 0;
BA_ "Confidence" SG_ 793 VCSEC_infoBootGitHash 0;
BA_ "Confidence" SG_ 793 VCSEC_infoPlatformType 0;
BA_ "Confidence" SG_ 793 VCSEC_infoBootUdsProtoVersion 0;
BA_ "Confidence" SG_ 793 VCSEC_infoBootCrc 0;
BA_ "Confidence" SG_ 793 VCSEC_infoSubcomponent2 0;
BA_ "Confidence" SG_ 793 VCSEC_infoSubcomponent3 0;
BA_ "Confidence" SG_ 793 VCSEC_infoSubcomponent4 0;
BA_ "Confidence" SG_ 505 VCSEC_chargePortRequest 0;
BA_ "GenSigSNA" SG_ 505 VCSEC_chargePortRequest "3";
BA_ "Confidence" SG_ 505 VCSEC_presentHandles 0;
BA_ "Confidence" SG_ 505 VCSEC_frontLeftClosureRequest 0;
BA_ "Confidence" SG_ 505 VCSEC_frontRightClosureRequest 0;
BA_ "Confidence" SG_ 505 VCSEC_rearLeftClosureRequest 0;
BA_ "Confidence" SG_ 505 VCSEC_rearRightClosureRequest 0;
BA_ "Confidence" SG_ 505 VCSEC_rearTrunkClosureRequest 0;
BA_ "Confidence" SG_ 505 VCSEC_frontLeftRequestReason 0;
BA_ "Confidence" SG_ 505 VCSEC_frontRightRequestReason 0;
BA_ "Confidence" SG_ 505 VCSEC_rearLeftRequestReason 0;
BA_ "Confidence" SG_ 505 VCSEC_rearRightRequestReason 0;
BA_ "Confidence" SG_ 505 VCSEC_rearTrunkRequestReason 0;
BA_ "Confidence" SG_ 505 VCSEC_rdMapDumpRequested 0;
BA_ "Confidence" SG_ 505 VCSEC_driveAttemptedWithoutAuth 0;
BA_ "Confidence" SG_ 505 VCSEC_closeAllStatus 0;
BA_ "Confidence" SG_ 505 VCSEC_snapshotRequested 0;
BA_ "Confidence" SG_ 505 VCSEC_chargeportRequestReason 0;
BA_ "Confidence" SG_ 505 VCSEC_frontTrunkClosureRequest 0;
BA_ "Confidence" SG_ 505 VCSEC_frontTrunkRequestReason 0;
BA_ "Confidence" SG_ 1850 VC_LVBMS_brickMeasurementsMultip 1;
BA_ "SystemSignalLongSymbol" SG_ 1850 VC_LVBMS_brickMeasurementsMultip "VC_LVBMS_brickMeasurementsMultiplexer";
BA_ "Confidence" SG_ 1850 VC_LVBMS_brickVoltage1 0;
BA_ "GenSigSNA" SG_ 1850 VC_LVBMS_brickVoltage1 "8191";
BA_ "Confidence" SG_ 1850 VC_LVBMS_brickVoltage2 0;
BA_ "GenSigSNA" SG_ 1850 VC_LVBMS_brickVoltage2 "8191";
BA_ "Confidence" SG_ 1850 VC_LVBMS_brickVoltage3 0;
BA_ "GenSigSNA" SG_ 1850 VC_LVBMS_brickVoltage3 "8191";
BA_ "Confidence" SG_ 1850 VC_LVBMS_brickVoltage4 0;
BA_ "GenSigSNA" SG_ 1850 VC_LVBMS_brickVoltage4 "8191";
BA_ "Confidence" SG_ 1850 VC_LVBMS_brickBalancingAh1 0;
BA_ "GenSigSNA" SG_ 1850 VC_LVBMS_brickBalancingAh1 "16777215";
BA_ "Confidence" SG_ 1850 VC_LVBMS_brickBalancingAh2 0;
BA_ "GenSigSNA" SG_ 1850 VC_LVBMS_brickBalancingAh2 "16777215";
BA_ "Confidence" SG_ 1850 VC_LVBMS_brickBalancingState1 0;
BA_ "Confidence" SG_ 1850 VC_LVBMS_brickBalancingState2 0;
BA_ "Confidence" SG_ 1850 VC_LVBMS_brickBalancingAh3 0;
BA_ "GenSigSNA" SG_ 1850 VC_LVBMS_brickBalancingAh3 "16777215";
BA_ "Confidence" SG_ 1850 VC_LVBMS_brickBalancingAh4 0;
BA_ "GenSigSNA" SG_ 1850 VC_LVBMS_brickBalancingAh4 "16777215";
BA_ "Confidence" SG_ 1850 VC_LVBMS_brickBalancingState3 0;
BA_ "Confidence" SG_ 1850 VC_LVBMS_brickBalancingState4 0;
VAL_ 857 VCSEC_DeviceStatusIndex 119 "19_ANDROID_INFO" 118 "19_MODEL_NUMBER" 117 "19_INFO2" 116 "19_INFO" 115 "19_STATS" 114 "19_VITALS" 113 "18_ANDROID_INFO" 112 "18_MODEL_NUMBER" 111 "18_INFO2" 110 "18_INFO" 109 "18_STATS" 108 "18_VITALS" 107 "17_ANDROID_INFO" 106 "17_MODEL_NUMBER" 105 "17_INFO2" 104 "17_INFO" 103 "17_STATS" 102 "17_VITALS" 101 "16_ANDROID_INFO" 100 "16_MODEL_NUMBER" 99 "16_INFO2" 98 "16_INFO" 97 "16_STATS" 96 "16_VITALS" 95 "15_ANDROID_INFO" 94 "15_MODEL_NUMBER" 93 "15_INFO2" 92 "15_INFO" 91 "15_STATS" 90 "15_VITALS" 89 "14_ANDROID_INFO" 88 "14_MODEL_NUMBER" 87 "14_INFO2" 86 "14_INFO" 85 "14_STATS" 84 "14_VITALS" 83 "13_ANDROID_INFO" 82 "13_MODEL_NUMBER" 81 "13_INFO2" 80 "13_INFO" 79 "13_STATS" 78 "13_VITALS" 77 "12_ANDROID_INFO" 76 "12_MODEL_NUMBER" 75 "12_INFO2" 74 "12_INFO" 73 "12_STATS" 72 "12_VITALS" 71 "11_ANDROID_INFO" 70 "11_MODEL_NUMBER" 69 "11_INFO2" 68 "11_INFO" 67 "11_STATS" 66 "11_VITALS" 65 "10_ANDROID_INFO" 64 "10_MODEL_NUMBER" 63 "10_INFO2" 62 "10_INFO" 61 "10_STATS" 60 "10_VITALS" 59 "9_ANDROID_INFO" 58 "9_MODEL_NUMBER" 57 "9_INFO2" 56 "9_INFO" 55 "9_STATS" 54 "9_VITALS" 53 "8_ANDROID_INFO" 52 "8_MODEL_NUMBER" 51 "8_INFO2" 50 "8_INFO" 49 "8_STATS" 48 "8_VITALS" 47 "7_ANDROID_INFO" 46 "7_MODEL_NUMBER" 45 "7_INFO2" 44 "7_INFO" 43 "7_STATS" 42 "7_VITALS" 41 "6_ANDROID_INFO" 40 "6_MODEL_NUMBER" 39 "6_INFO2" 38 "6_INFO" 37 "6_STATS" 36 "6_VITALS" 35 "5_ANDROID_INFO" 34 "5_MODEL_NUMBER" 33 "5_INFO2" 32 "5_INFO" 31 "5_STATS" 30 "5_VITALS" 29 "4_ANDROID_INFO" 28 "4_MODEL_NUMBER" 27 "4_INFO2" 26 "4_INFO" 25 "4_STATS" 24 "4_VITALS" 23 "3_ANDROID_INFO" 22 "3_MODEL_NUMBER" 21 "3_INFO2" 20 "3_INFO" 19 "3_STATS" 18 "3_VITALS" 17 "2_ANDROID_INFO" 16 "2_MODEL_NUMBER" 15 "2_INFO2" 14 "2_INFO" 13 "2_STATS" 12 "2_VITALS" 11 "1_ANDROID_INFO" 10 "1_MODEL_NUMBER" 9 "1_INFO2" 8 "1_INFO" 7 "1_STATS" 6 "1_VITALS" 5 "0_ANDROID_INFO" 4 "0_MODEL_NUMBER" 3 "0_INFO2" 2 "0_INFO" 1 "0_STATS" 0 "0_VITALS" ;
VAL_ 857 VCSEC_Device0AuthResponseTime 127 "SNA" ;
VAL_ 857 VCSEC_Device0Formfactor 19 "KEY_FORM_FACTOR_HARMONY_OS_NEXT_DEVICE" 18 "KEY_FORM_FACTOR_NFC_CARD_WATCHDATA_PLASTIC_CARD" 17 "KEY_FORM_FACTOR_APPLE_WATCH" 16 "KEY_FORM_FACTOR_NFC_CARD_IDEMIA_PLASTIC_CARD" 15 "KEY_FORM_FACTOR_NFC_CARD_IDEMIA_METAL_CARD" 14 "KEY_FORM_FACTOR_NFC_CARD_P71" 13 "KEY_FORM_FACTOR_3_BUTTON_GEN2_CAR_KEYFOB_P60_V3" 12 "KEY_FORM_FACTOR_3_BUTTON_GEN2_CAR_KEYFOB_P60_V2" 11 "KEY_FORM_FACTOR_5_BUTTON_GEN2_CAR_KEYFOB_P60" 10 "KEY_FORM_FACTOR_3_BUTTON_GEN2_CAR_KEYFOB_P60" 9 "KEY_FORM_FACTOR_CLOUD_KEY" 8 "KEY_FORM_FACTOR_3_BUTTON_BLE_CAR_KEYFOB_P60" 7 "KEY_FORM_FACTOR_ANDROID_DEVICE" 6 "KEY_FORM_FACTOR_IOS_DEVICE" 5 "KEY_FORM_FACTOR_BLE_AND_NFC_DEVICE" 4 "KEY_FORM_FACTOR_NFC_DEVICE" 3 "KEY_FORM_FACTOR_BLE_DEVICE" 2 "KEY_FORM_FACTOR_3_BUTTON_BLE_CAR_KEYFOB" 1 "KEY_FORM_FACTOR_NFC_CARD" 0 "KEY_FORM_FACTOR_UNKNOWN" ;
VAL_ 857 VCSEC_Device0Role 10 "DEVICE_ROLE_PREDELIVERY_KEY" 9 "DEVICE_ROLE_RIDER_KEY" 8 "DEVICE_ROLE_GUEST_KEY" 7 "DEVICE_ROLE_SERVICE_TECH_KEY" 6 "DEVICE_ROLE_CHARGING_MANAGER_KEY" 5 "DEVICE_ROLE_VEHICLE_MONITOR_KEY" 4 "DEVICE_ROLE_FM_KEY" 3 "DEVICE_ROLE_DRIVER_KEY" 2 "DEVICE_ROLE_OWNER_KEY" 1 "DEVICE_ROLE_SERVICE_KEY" 0 "DEVICE_ROLE_NONE" ;
VAL_ 857 VCSEC_Device1AuthResponseTime 127 "SNA" ;
VAL_ 857 VCSEC_Device1Formfactor 19 "KEY_FORM_FACTOR_HARMONY_OS_NEXT_DEVICE" 18 "KEY_FORM_FACTOR_NFC_CARD_WATCHDATA_PLASTIC_CARD" 17 "KEY_FORM_FACTOR_APPLE_WATCH" 16 "KEY_FORM_FACTOR_NFC_CARD_IDEMIA_PLASTIC_CARD" 15 "KEY_FORM_FACTOR_NFC_CARD_IDEMIA_METAL_CARD" 14 "KEY_FORM_FACTOR_NFC_CARD_P71" 13 "KEY_FORM_FACTOR_3_BUTTON_GEN2_CAR_KEYFOB_P60_V3" 12 "KEY_FORM_FACTOR_3_BUTTON_GEN2_CAR_KEYFOB_P60_V2" 11 "KEY_FORM_FACTOR_5_BUTTON_GEN2_CAR_KEYFOB_P60" 10 "KEY_FORM_FACTOR_3_BUTTON_GEN2_CAR_KEYFOB_P60" 9 "KEY_FORM_FACTOR_CLOUD_KEY" 8 "KEY_FORM_FACTOR_3_BUTTON_BLE_CAR_KEYFOB_P60" 7 "KEY_FORM_FACTOR_ANDROID_DEVICE" 6 "KEY_FORM_FACTOR_IOS_DEVICE" 5 "KEY_FORM_FACTOR_BLE_AND_NFC_DEVICE" 4 "KEY_FORM_FACTOR_NFC_DEVICE" 3 "KEY_FORM_FACTOR_BLE_DEVICE" 2 "KEY_FORM_FACTOR_3_BUTTON_BLE_CAR_KEYFOB" 1 "KEY_FORM_FACTOR_NFC_CARD" 0 "KEY_FORM_FACTOR_UNKNOWN" ;
VAL_ 857 VCSEC_Device1Role 10 "DEVICE_ROLE_PREDELIVERY_KEY" 9 "DEVICE_ROLE_RIDER_KEY" 8 "DEVICE_ROLE_GUEST_KEY" 7 "DEVICE_ROLE_SERVICE_TECH_KEY" 6 "DEVICE_ROLE_CHARGING_MANAGER_KEY" 5 "DEVICE_ROLE_VEHICLE_MONITOR_KEY" 4 "DEVICE_ROLE_FM_KEY" 3 "DEVICE_ROLE_DRIVER_KEY" 2 "DEVICE_ROLE_OWNER_KEY" 1 "DEVICE_ROLE_SERVICE_KEY" 0 "DEVICE_ROLE_NONE" ;
VAL_ 857 VCSEC_Device2AuthResponseTime 127 "SNA" ;
VAL_ 857 VCSEC_Device2Formfactor 19 "KEY_FORM_FACTOR_HARMONY_OS_NEXT_DEVICE" 18 "KEY_FORM_FACTOR_NFC_CARD_WATCHDATA_PLASTIC_CARD" 17 "KEY_FORM_FACTOR_APPLE_WATCH" 16 "KEY_FORM_FACTOR_NFC_CARD_IDEMIA_PLASTIC_CARD" 15 "KEY_FORM_FACTOR_NFC_CARD_IDEMIA_METAL_CARD" 14 "KEY_FORM_FACTOR_NFC_CARD_P71" 13 "KEY_FORM_FACTOR_3_BUTTON_GEN2_CAR_KEYFOB_P60_V3" 12 "KEY_FORM_FACTOR_3_BUTTON_GEN2_CAR_KEYFOB_P60_V2" 11 "KEY_FORM_FACTOR_5_BUTTON_GEN2_CAR_KEYFOB_P60" 10 "KEY_FORM_FACTOR_3_BUTTON_GEN2_CAR_KEYFOB_P60" 9 "KEY_FORM_FACTOR_CLOUD_KEY" 8 "KEY_FORM_FACTOR_3_BUTTON_BLE_CAR_KEYFOB_P60" 7 "KEY_FORM_FACTOR_ANDROID_DEVICE" 6 "KEY_FORM_FACTOR_IOS_DEVICE" 5 "KEY_FORM_FACTOR_BLE_AND_NFC_DEVICE" 4 "KEY_FORM_FACTOR_NFC_DEVICE" 3 "KEY_FORM_FACTOR_BLE_DEVICE" 2 "KEY_FORM_FACTOR_3_BUTTON_BLE_CAR_KEYFOB" 1 "KEY_FORM_FACTOR_NFC_CARD" 0 "KEY_FORM_FACTOR_UNKNOWN" ;
VAL_ 857 VCSEC_Device2Role 10 "DEVICE_ROLE_PREDELIVERY_KEY" 9 "DEVICE_ROLE_RIDER_KEY" 8 "DEVICE_ROLE_GUEST_KEY" 7 "DEVICE_ROLE_SERVICE_TECH_KEY" 6 "DEVICE_ROLE_CHARGING_MANAGER_KEY" 5 "DEVICE_ROLE_VEHICLE_MONITOR_KEY" 4 "DEVICE_ROLE_FM_KEY" 3 "DEVICE_ROLE_DRIVER_KEY" 2 "DEVICE_ROLE_OWNER_KEY" 1 "DEVICE_ROLE_SERVICE_KEY" 0 "DEVICE_ROLE_NONE" ;
VAL_ 857 VCSEC_Device3AuthResponseTime 127 "SNA" ;
VAL_ 857 VCSEC_Device3Formfactor 19 "KEY_FORM_FACTOR_HARMONY_OS_NEXT_DEVICE" 18 "KEY_FORM_FACTOR_NFC_CARD_WATCHDATA_PLASTIC_CARD" 17 "KEY_FORM_FACTOR_APPLE_WATCH" 16 "KEY_FORM_FACTOR_NFC_CARD_IDEMIA_PLASTIC_CARD" 15 "KEY_FORM_FACTOR_NFC_CARD_IDEMIA_METAL_CARD" 14 "KEY_FORM_FACTOR_NFC_CARD_P71" 13 "KEY_FORM_FACTOR_3_BUTTON_GEN2_CAR_KEYFOB_P60_V3" 12 "KEY_FORM_FACTOR_3_BUTTON_GEN2_CAR_KEYFOB_P60_V2" 11 "KEY_FORM_FACTOR_5_BUTTON_GEN2_CAR_KEYFOB_P60" 10 "KEY_FORM_FACTOR_3_BUTTON_GEN2_CAR_KEYFOB_P60" 9 "KEY_FORM_FACTOR_CLOUD_KEY" 8 "KEY_FORM_FACTOR_3_BUTTON_BLE_CAR_KEYFOB_P60" 7 "KEY_FORM_FACTOR_ANDROID_DEVICE" 6 "KEY_FORM_FACTOR_IOS_DEVICE" 5 "KEY_FORM_FACTOR_BLE_AND_NFC_DEVICE" 4 "KEY_FORM_FACTOR_NFC_DEVICE" 3 "KEY_FORM_FACTOR_BLE_DEVICE" 2 "KEY_FORM_FACTOR_3_BUTTON_BLE_CAR_KEYFOB" 1 "KEY_FORM_FACTOR_NFC_CARD" 0 "KEY_FORM_FACTOR_UNKNOWN" ;
VAL_ 857 VCSEC_Device3Role 10 "DEVICE_ROLE_PREDELIVERY_KEY" 9 "DEVICE_ROLE_RIDER_KEY" 8 "DEVICE_ROLE_GUEST_KEY" 7 "DEVICE_ROLE_SERVICE_TECH_KEY" 6 "DEVICE_ROLE_CHARGING_MANAGER_KEY" 5 "DEVICE_ROLE_VEHICLE_MONITOR_KEY" 4 "DEVICE_ROLE_FM_KEY" 3 "DEVICE_ROLE_DRIVER_KEY" 2 "DEVICE_ROLE_OWNER_KEY" 1 "DEVICE_ROLE_SERVICE_KEY" 0 "DEVICE_ROLE_NONE" ;
VAL_ 857 VCSEC_Device4AuthResponseTime 127 "SNA" ;
VAL_ 857 VCSEC_Device4Formfactor 19 "KEY_FORM_FACTOR_HARMONY_OS_NEXT_DEVICE" 18 "KEY_FORM_FACTOR_NFC_CARD_WATCHDATA_PLASTIC_CARD" 17 "KEY_FORM_FACTOR_APPLE_WATCH" 16 "KEY_FORM_FACTOR_NFC_CARD_IDEMIA_PLASTIC_CARD" 15 "KEY_FORM_FACTOR_NFC_CARD_IDEMIA_METAL_CARD" 14 "KEY_FORM_FACTOR_NFC_CARD_P71" 13 "KEY_FORM_FACTOR_3_BUTTON_GEN2_CAR_KEYFOB_P60_V3" 12 "KEY_FORM_FACTOR_3_BUTTON_GEN2_CAR_KEYFOB_P60_V2" 11 "KEY_FORM_FACTOR_5_BUTTON_GEN2_CAR_KEYFOB_P60" 10 "KEY_FORM_FACTOR_3_BUTTON_GEN2_CAR_KEYFOB_P60" 9 "KEY_FORM_FACTOR_CLOUD_KEY" 8 "KEY_FORM_FACTOR_3_BUTTON_BLE_CAR_KEYFOB_P60" 7 "KEY_FORM_FACTOR_ANDROID_DEVICE" 6 "KEY_FORM_FACTOR_IOS_DEVICE" 5 "KEY_FORM_FACTOR_BLE_AND_NFC_DEVICE" 4 "KEY_FORM_FACTOR_NFC_DEVICE" 3 "KEY_FORM_FACTOR_BLE_DEVICE" 2 "KEY_FORM_FACTOR_3_BUTTON_BLE_CAR_KEYFOB" 1 "KEY_FORM_FACTOR_NFC_CARD" 0 "KEY_FORM_FACTOR_UNKNOWN" ;
VAL_ 857 VCSEC_Device4Role 10 "DEVICE_ROLE_PREDELIVERY_KEY" 9 "DEVICE_ROLE_RIDER_KEY" 8 "DEVICE_ROLE_GUEST_KEY" 7 "DEVICE_ROLE_SERVICE_TECH_KEY" 6 "DEVICE_ROLE_CHARGING_MANAGER_KEY" 5 "DEVICE_ROLE_VEHICLE_MONITOR_KEY" 4 "DEVICE_ROLE_FM_KEY" 3 "DEVICE_ROLE_DRIVER_KEY" 2 "DEVICE_ROLE_OWNER_KEY" 1 "DEVICE_ROLE_SERVICE_KEY" 0 "DEVICE_ROLE_NONE" ;
VAL_ 857 VCSEC_Device5AuthResponseTime 127 "SNA" ;
VAL_ 857 VCSEC_Device5Formfactor 19 "KEY_FORM_FACTOR_HARMONY_OS_NEXT_DEVICE" 18 "KEY_FORM_FACTOR_NFC_CARD_WATCHDATA_PLASTIC_CARD" 17 "KEY_FORM_FACTOR_APPLE_WATCH" 16 "KEY_FORM_FACTOR_NFC_CARD_IDEMIA_PLASTIC_CARD" 15 "KEY_FORM_FACTOR_NFC_CARD_IDEMIA_METAL_CARD" 14 "KEY_FORM_FACTOR_NFC_CARD_P71" 13 "KEY_FORM_FACTOR_3_BUTTON_GEN2_CAR_KEYFOB_P60_V3" 12 "KEY_FORM_FACTOR_3_BUTTON_GEN2_CAR_KEYFOB_P60_V2" 11 "KEY_FORM_FACTOR_5_BUTTON_GEN2_CAR_KEYFOB_P60" 10 "KEY_FORM_FACTOR_3_BUTTON_GEN2_CAR_KEYFOB_P60" 9 "KEY_FORM_FACTOR_CLOUD_KEY" 8 "KEY_FORM_FACTOR_3_BUTTON_BLE_CAR_KEYFOB_P60" 7 "KEY_FORM_FACTOR_ANDROID_DEVICE" 6 "KEY_FORM_FACTOR_IOS_DEVICE" 5 "KEY_FORM_FACTOR_BLE_AND_NFC_DEVICE" 4 "KEY_FORM_FACTOR_NFC_DEVICE" 3 "KEY_FORM_FACTOR_BLE_DEVICE" 2 "KEY_FORM_FACTOR_3_BUTTON_BLE_CAR_KEYFOB" 1 "KEY_FORM_FACTOR_NFC_CARD" 0 "KEY_FORM_FACTOR_UNKNOWN" ;
VAL_ 857 VCSEC_Device5Role 10 "DEVICE_ROLE_PREDELIVERY_KEY" 9 "DEVICE_ROLE_RIDER_KEY" 8 "DEVICE_ROLE_GUEST_KEY" 7 "DEVICE_ROLE_SERVICE_TECH_KEY" 6 "DEVICE_ROLE_CHARGING_MANAGER_KEY" 5 "DEVICE_ROLE_VEHICLE_MONITOR_KEY" 4 "DEVICE_ROLE_FM_KEY" 3 "DEVICE_ROLE_DRIVER_KEY" 2 "DEVICE_ROLE_OWNER_KEY" 1 "DEVICE_ROLE_SERVICE_KEY" 0 "DEVICE_ROLE_NONE" ;
VAL_ 857 VCSEC_Device6AuthResponseTime 127 "SNA" ;
VAL_ 857 VCSEC_Device6Formfactor 19 "KEY_FORM_FACTOR_HARMONY_OS_NEXT_DEVICE" 18 "KEY_FORM_FACTOR_NFC_CARD_WATCHDATA_PLASTIC_CARD" 17 "KEY_FORM_FACTOR_APPLE_WATCH" 16 "KEY_FORM_FACTOR_NFC_CARD_IDEMIA_PLASTIC_CARD" 15 "KEY_FORM_FACTOR_NFC_CARD_IDEMIA_METAL_CARD" 14 "KEY_FORM_FACTOR_NFC_CARD_P71" 13 "KEY_FORM_FACTOR_3_BUTTON_GEN2_CAR_KEYFOB_P60_V3" 12 "KEY_FORM_FACTOR_3_BUTTON_GEN2_CAR_KEYFOB_P60_V2" 11 "KEY_FORM_FACTOR_5_BUTTON_GEN2_CAR_KEYFOB_P60" 10 "KEY_FORM_FACTOR_3_BUTTON_GEN2_CAR_KEYFOB_P60" 9 "KEY_FORM_FACTOR_CLOUD_KEY" 8 "KEY_FORM_FACTOR_3_BUTTON_BLE_CAR_KEYFOB_P60" 7 "KEY_FORM_FACTOR_ANDROID_DEVICE" 6 "KEY_FORM_FACTOR_IOS_DEVICE" 5 "KEY_FORM_FACTOR_BLE_AND_NFC_DEVICE" 4 "KEY_FORM_FACTOR_NFC_DEVICE" 3 "KEY_FORM_FACTOR_BLE_DEVICE" 2 "KEY_FORM_FACTOR_3_BUTTON_BLE_CAR_KEYFOB" 1 "KEY_FORM_FACTOR_NFC_CARD" 0 "KEY_FORM_FACTOR_UNKNOWN" ;
VAL_ 857 VCSEC_Device6Role 10 "DEVICE_ROLE_PREDELIVERY_KEY" 9 "DEVICE_ROLE_RIDER_KEY" 8 "DEVICE_ROLE_GUEST_KEY" 7 "DEVICE_ROLE_SERVICE_TECH_KEY" 6 "DEVICE_ROLE_CHARGING_MANAGER_KEY" 5 "DEVICE_ROLE_VEHICLE_MONITOR_KEY" 4 "DEVICE_ROLE_FM_KEY" 3 "DEVICE_ROLE_DRIVER_KEY" 2 "DEVICE_ROLE_OWNER_KEY" 1 "DEVICE_ROLE_SERVICE_KEY" 0 "DEVICE_ROLE_NONE" ;
VAL_ 857 VCSEC_Device7AuthResponseTime 127 "SNA" ;
VAL_ 857 VCSEC_Device7Formfactor 19 "KEY_FORM_FACTOR_HARMONY_OS_NEXT_DEVICE" 18 "KEY_FORM_FACTOR_NFC_CARD_WATCHDATA_PLASTIC_CARD" 17 "KEY_FORM_FACTOR_APPLE_WATCH" 16 "KEY_FORM_FACTOR_NFC_CARD_IDEMIA_PLASTIC_CARD" 15 "KEY_FORM_FACTOR_NFC_CARD_IDEMIA_METAL_CARD" 14 "KEY_FORM_FACTOR_NFC_CARD_P71" 13 "KEY_FORM_FACTOR_3_BUTTON_GEN2_CAR_KEYFOB_P60_V3" 12 "KEY_FORM_FACTOR_3_BUTTON_GEN2_CAR_KEYFOB_P60_V2" 11 "KEY_FORM_FACTOR_5_BUTTON_GEN2_CAR_KEYFOB_P60" 10 "KEY_FORM_FACTOR_3_BUTTON_GEN2_CAR_KEYFOB_P60" 9 "KEY_FORM_FACTOR_CLOUD_KEY" 8 "KEY_FORM_FACTOR_3_BUTTON_BLE_CAR_KEYFOB_P60" 7 "KEY_FORM_FACTOR_ANDROID_DEVICE" 6 "KEY_FORM_FACTOR_IOS_DEVICE" 5 "KEY_FORM_FACTOR_BLE_AND_NFC_DEVICE" 4 "KEY_FORM_FACTOR_NFC_DEVICE" 3 "KEY_FORM_FACTOR_BLE_DEVICE" 2 "KEY_FORM_FACTOR_3_BUTTON_BLE_CAR_KEYFOB" 1 "KEY_FORM_FACTOR_NFC_CARD" 0 "KEY_FORM_FACTOR_UNKNOWN" ;
VAL_ 857 VCSEC_Device7Role 10 "DEVICE_ROLE_PREDELIVERY_KEY" 9 "DEVICE_ROLE_RIDER_KEY" 8 "DEVICE_ROLE_GUEST_KEY" 7 "DEVICE_ROLE_SERVICE_TECH_KEY" 6 "DEVICE_ROLE_CHARGING_MANAGER_KEY" 5 "DEVICE_ROLE_VEHICLE_MONITOR_KEY" 4 "DEVICE_ROLE_FM_KEY" 3 "DEVICE_ROLE_DRIVER_KEY" 2 "DEVICE_ROLE_OWNER_KEY" 1 "DEVICE_ROLE_SERVICE_KEY" 0 "DEVICE_ROLE_NONE" ;
VAL_ 857 VCSEC_Device8AuthResponseTime 127 "SNA" ;
VAL_ 857 VCSEC_Device8Formfactor 19 "KEY_FORM_FACTOR_HARMONY_OS_NEXT_DEVICE" 18 "KEY_FORM_FACTOR_NFC_CARD_WATCHDATA_PLASTIC_CARD" 17 "KEY_FORM_FACTOR_APPLE_WATCH" 16 "KEY_FORM_FACTOR_NFC_CARD_IDEMIA_PLASTIC_CARD" 15 "KEY_FORM_FACTOR_NFC_CARD_IDEMIA_METAL_CARD" 14 "KEY_FORM_FACTOR_NFC_CARD_P71" 13 "KEY_FORM_FACTOR_3_BUTTON_GEN2_CAR_KEYFOB_P60_V3" 12 "KEY_FORM_FACTOR_3_BUTTON_GEN2_CAR_KEYFOB_P60_V2" 11 "KEY_FORM_FACTOR_5_BUTTON_GEN2_CAR_KEYFOB_P60" 10 "KEY_FORM_FACTOR_3_BUTTON_GEN2_CAR_KEYFOB_P60" 9 "KEY_FORM_FACTOR_CLOUD_KEY" 8 "KEY_FORM_FACTOR_3_BUTTON_BLE_CAR_KEYFOB_P60" 7 "KEY_FORM_FACTOR_ANDROID_DEVICE" 6 "KEY_FORM_FACTOR_IOS_DEVICE" 5 "KEY_FORM_FACTOR_BLE_AND_NFC_DEVICE" 4 "KEY_FORM_FACTOR_NFC_DEVICE" 3 "KEY_FORM_FACTOR_BLE_DEVICE" 2 "KEY_FORM_FACTOR_3_BUTTON_BLE_CAR_KEYFOB" 1 "KEY_FORM_FACTOR_NFC_CARD" 0 "KEY_FORM_FACTOR_UNKNOWN" ;
VAL_ 857 VCSEC_Device8Role 10 "DEVICE_ROLE_PREDELIVERY_KEY" 9 "DEVICE_ROLE_RIDER_KEY" 8 "DEVICE_ROLE_GUEST_KEY" 7 "DEVICE_ROLE_SERVICE_TECH_KEY" 6 "DEVICE_ROLE_CHARGING_MANAGER_KEY" 5 "DEVICE_ROLE_VEHICLE_MONITOR_KEY" 4 "DEVICE_ROLE_FM_KEY" 3 "DEVICE_ROLE_DRIVER_KEY" 2 "DEVICE_ROLE_OWNER_KEY" 1 "DEVICE_ROLE_SERVICE_KEY" 0 "DEVICE_ROLE_NONE" ;
VAL_ 857 VCSEC_Device9AuthResponseTime 127 "SNA" ;
VAL_ 857 VCSEC_Device9Formfactor 19 "KEY_FORM_FACTOR_HARMONY_OS_NEXT_DEVICE" 18 "KEY_FORM_FACTOR_NFC_CARD_WATCHDATA_PLASTIC_CARD" 17 "KEY_FORM_FACTOR_APPLE_WATCH" 16 "KEY_FORM_FACTOR_NFC_CARD_IDEMIA_PLASTIC_CARD" 15 "KEY_FORM_FACTOR_NFC_CARD_IDEMIA_METAL_CARD" 14 "KEY_FORM_FACTOR_NFC_CARD_P71" 13 "KEY_FORM_FACTOR_3_BUTTON_GEN2_CAR_KEYFOB_P60_V3" 12 "KEY_FORM_FACTOR_3_BUTTON_GEN2_CAR_KEYFOB_P60_V2" 11 "KEY_FORM_FACTOR_5_BUTTON_GEN2_CAR_KEYFOB_P60" 10 "KEY_FORM_FACTOR_3_BUTTON_GEN2_CAR_KEYFOB_P60" 9 "KEY_FORM_FACTOR_CLOUD_KEY" 8 "KEY_FORM_FACTOR_3_BUTTON_BLE_CAR_KEYFOB_P60" 7 "KEY_FORM_FACTOR_ANDROID_DEVICE" 6 "KEY_FORM_FACTOR_IOS_DEVICE" 5 "KEY_FORM_FACTOR_BLE_AND_NFC_DEVICE" 4 "KEY_FORM_FACTOR_NFC_DEVICE" 3 "KEY_FORM_FACTOR_BLE_DEVICE" 2 "KEY_FORM_FACTOR_3_BUTTON_BLE_CAR_KEYFOB" 1 "KEY_FORM_FACTOR_NFC_CARD" 0 "KEY_FORM_FACTOR_UNKNOWN" ;
VAL_ 857 VCSEC_Device9Role 10 "DEVICE_ROLE_PREDELIVERY_KEY" 9 "DEVICE_ROLE_RIDER_KEY" 8 "DEVICE_ROLE_GUEST_KEY" 7 "DEVICE_ROLE_SERVICE_TECH_KEY" 6 "DEVICE_ROLE_CHARGING_MANAGER_KEY" 5 "DEVICE_ROLE_VEHICLE_MONITOR_KEY" 4 "DEVICE_ROLE_FM_KEY" 3 "DEVICE_ROLE_DRIVER_KEY" 2 "DEVICE_ROLE_OWNER_KEY" 1 "DEVICE_ROLE_SERVICE_KEY" 0 "DEVICE_ROLE_NONE" ;
VAL_ 857 VCSEC_Device10AuthResponseTime 127 "SNA" ;
VAL_ 857 VCSEC_Device10Formfactor 19 "KEY_FORM_FACTOR_HARMONY_OS_NEXT_DEVICE" 18 "KEY_FORM_FACTOR_NFC_CARD_WATCHDATA_PLASTIC_CARD" 17 "KEY_FORM_FACTOR_APPLE_WATCH" 16 "KEY_FORM_FACTOR_NFC_CARD_IDEMIA_PLASTIC_CARD" 15 "KEY_FORM_FACTOR_NFC_CARD_IDEMIA_METAL_CARD" 14 "KEY_FORM_FACTOR_NFC_CARD_P71" 13 "KEY_FORM_FACTOR_3_BUTTON_GEN2_CAR_KEYFOB_P60_V3" 12 "KEY_FORM_FACTOR_3_BUTTON_GEN2_CAR_KEYFOB_P60_V2" 11 "KEY_FORM_FACTOR_5_BUTTON_GEN2_CAR_KEYFOB_P60" 10 "KEY_FORM_FACTOR_3_BUTTON_GEN2_CAR_KEYFOB_P60" 9 "KEY_FORM_FACTOR_CLOUD_KEY" 8 "KEY_FORM_FACTOR_3_BUTTON_BLE_CAR_KEYFOB_P60" 7 "KEY_FORM_FACTOR_ANDROID_DEVICE" 6 "KEY_FORM_FACTOR_IOS_DEVICE" 5 "KEY_FORM_FACTOR_BLE_AND_NFC_DEVICE" 4 "KEY_FORM_FACTOR_NFC_DEVICE" 3 "KEY_FORM_FACTOR_BLE_DEVICE" 2 "KEY_FORM_FACTOR_3_BUTTON_BLE_CAR_KEYFOB" 1 "KEY_FORM_FACTOR_NFC_CARD" 0 "KEY_FORM_FACTOR_UNKNOWN" ;
VAL_ 857 VCSEC_Device10Role 10 "DEVICE_ROLE_PREDELIVERY_KEY" 9 "DEVICE_ROLE_RIDER_KEY" 8 "DEVICE_ROLE_GUEST_KEY" 7 "DEVICE_ROLE_SERVICE_TECH_KEY" 6 "DEVICE_ROLE_CHARGING_MANAGER_KEY" 5 "DEVICE_ROLE_VEHICLE_MONITOR_KEY" 4 "DEVICE_ROLE_FM_KEY" 3 "DEVICE_ROLE_DRIVER_KEY" 2 "DEVICE_ROLE_OWNER_KEY" 1 "DEVICE_ROLE_SERVICE_KEY" 0 "DEVICE_ROLE_NONE" ;
VAL_ 857 VCSEC_Device11AuthResponseTime 127 "SNA" ;
VAL_ 857 VCSEC_Device11Formfactor 19 "KEY_FORM_FACTOR_HARMONY_OS_NEXT_DEVICE" 18 "KEY_FORM_FACTOR_NFC_CARD_WATCHDATA_PLASTIC_CARD" 17 "KEY_FORM_FACTOR_APPLE_WATCH" 16 "KEY_FORM_FACTOR_NFC_CARD_IDEMIA_PLASTIC_CARD" 15 "KEY_FORM_FACTOR_NFC_CARD_IDEMIA_METAL_CARD" 14 "KEY_FORM_FACTOR_NFC_CARD_P71" 13 "KEY_FORM_FACTOR_3_BUTTON_GEN2_CAR_KEYFOB_P60_V3" 12 "KEY_FORM_FACTOR_3_BUTTON_GEN2_CAR_KEYFOB_P60_V2" 11 "KEY_FORM_FACTOR_5_BUTTON_GEN2_CAR_KEYFOB_P60" 10 "KEY_FORM_FACTOR_3_BUTTON_GEN2_CAR_KEYFOB_P60" 9 "KEY_FORM_FACTOR_CLOUD_KEY" 8 "KEY_FORM_FACTOR_3_BUTTON_BLE_CAR_KEYFOB_P60" 7 "KEY_FORM_FACTOR_ANDROID_DEVICE" 6 "KEY_FORM_FACTOR_IOS_DEVICE" 5 "KEY_FORM_FACTOR_BLE_AND_NFC_DEVICE" 4 "KEY_FORM_FACTOR_NFC_DEVICE" 3 "KEY_FORM_FACTOR_BLE_DEVICE" 2 "KEY_FORM_FACTOR_3_BUTTON_BLE_CAR_KEYFOB" 1 "KEY_FORM_FACTOR_NFC_CARD" 0 "KEY_FORM_FACTOR_UNKNOWN" ;
VAL_ 857 VCSEC_Device11Role 10 "DEVICE_ROLE_PREDELIVERY_KEY" 9 "DEVICE_ROLE_RIDER_KEY" 8 "DEVICE_ROLE_GUEST_KEY" 7 "DEVICE_ROLE_SERVICE_TECH_KEY" 6 "DEVICE_ROLE_CHARGING_MANAGER_KEY" 5 "DEVICE_ROLE_VEHICLE_MONITOR_KEY" 4 "DEVICE_ROLE_FM_KEY" 3 "DEVICE_ROLE_DRIVER_KEY" 2 "DEVICE_ROLE_OWNER_KEY" 1 "DEVICE_ROLE_SERVICE_KEY" 0 "DEVICE_ROLE_NONE" ;
VAL_ 857 VCSEC_Device12AuthResponseTime 127 "SNA" ;
VAL_ 857 VCSEC_Device12Formfactor 19 "KEY_FORM_FACTOR_HARMONY_OS_NEXT_DEVICE" 18 "KEY_FORM_FACTOR_NFC_CARD_WATCHDATA_PLASTIC_CARD" 17 "KEY_FORM_FACTOR_APPLE_WATCH" 16 "KEY_FORM_FACTOR_NFC_CARD_IDEMIA_PLASTIC_CARD" 15 "KEY_FORM_FACTOR_NFC_CARD_IDEMIA_METAL_CARD" 14 "KEY_FORM_FACTOR_NFC_CARD_P71" 13 "KEY_FORM_FACTOR_3_BUTTON_GEN2_CAR_KEYFOB_P60_V3" 12 "KEY_FORM_FACTOR_3_BUTTON_GEN2_CAR_KEYFOB_P60_V2" 11 "KEY_FORM_FACTOR_5_BUTTON_GEN2_CAR_KEYFOB_P60" 10 "KEY_FORM_FACTOR_3_BUTTON_GEN2_CAR_KEYFOB_P60" 9 "KEY_FORM_FACTOR_CLOUD_KEY" 8 "KEY_FORM_FACTOR_3_BUTTON_BLE_CAR_KEYFOB_P60" 7 "KEY_FORM_FACTOR_ANDROID_DEVICE" 6 "KEY_FORM_FACTOR_IOS_DEVICE" 5 "KEY_FORM_FACTOR_BLE_AND_NFC_DEVICE" 4 "KEY_FORM_FACTOR_NFC_DEVICE" 3 "KEY_FORM_FACTOR_BLE_DEVICE" 2 "KEY_FORM_FACTOR_3_BUTTON_BLE_CAR_KEYFOB" 1 "KEY_FORM_FACTOR_NFC_CARD" 0 "KEY_FORM_FACTOR_UNKNOWN" ;
VAL_ 857 VCSEC_Device12Role 10 "DEVICE_ROLE_PREDELIVERY_KEY" 9 "DEVICE_ROLE_RIDER_KEY" 8 "DEVICE_ROLE_GUEST_KEY" 7 "DEVICE_ROLE_SERVICE_TECH_KEY" 6 "DEVICE_ROLE_CHARGING_MANAGER_KEY" 5 "DEVICE_ROLE_VEHICLE_MONITOR_KEY" 4 "DEVICE_ROLE_FM_KEY" 3 "DEVICE_ROLE_DRIVER_KEY" 2 "DEVICE_ROLE_OWNER_KEY" 1 "DEVICE_ROLE_SERVICE_KEY" 0 "DEVICE_ROLE_NONE" ;
VAL_ 857 VCSEC_Device13AuthResponseTime 127 "SNA" ;
VAL_ 857 VCSEC_Device13Formfactor 19 "KEY_FORM_FACTOR_HARMONY_OS_NEXT_DEVICE" 18 "KEY_FORM_FACTOR_NFC_CARD_WATCHDATA_PLASTIC_CARD" 17 "KEY_FORM_FACTOR_APPLE_WATCH" 16 "KEY_FORM_FACTOR_NFC_CARD_IDEMIA_PLASTIC_CARD" 15 "KEY_FORM_FACTOR_NFC_CARD_IDEMIA_METAL_CARD" 14 "KEY_FORM_FACTOR_NFC_CARD_P71" 13 "KEY_FORM_FACTOR_3_BUTTON_GEN2_CAR_KEYFOB_P60_V3" 12 "KEY_FORM_FACTOR_3_BUTTON_GEN2_CAR_KEYFOB_P60_V2" 11 "KEY_FORM_FACTOR_5_BUTTON_GEN2_CAR_KEYFOB_P60" 10 "KEY_FORM_FACTOR_3_BUTTON_GEN2_CAR_KEYFOB_P60" 9 "KEY_FORM_FACTOR_CLOUD_KEY" 8 "KEY_FORM_FACTOR_3_BUTTON_BLE_CAR_KEYFOB_P60" 7 "KEY_FORM_FACTOR_ANDROID_DEVICE" 6 "KEY_FORM_FACTOR_IOS_DEVICE" 5 "KEY_FORM_FACTOR_BLE_AND_NFC_DEVICE" 4 "KEY_FORM_FACTOR_NFC_DEVICE" 3 "KEY_FORM_FACTOR_BLE_DEVICE" 2 "KEY_FORM_FACTOR_3_BUTTON_BLE_CAR_KEYFOB" 1 "KEY_FORM_FACTOR_NFC_CARD" 0 "KEY_FORM_FACTOR_UNKNOWN" ;
VAL_ 857 VCSEC_Device13Role 10 "DEVICE_ROLE_PREDELIVERY_KEY" 9 "DEVICE_ROLE_RIDER_KEY" 8 "DEVICE_ROLE_GUEST_KEY" 7 "DEVICE_ROLE_SERVICE_TECH_KEY" 6 "DEVICE_ROLE_CHARGING_MANAGER_KEY" 5 "DEVICE_ROLE_VEHICLE_MONITOR_KEY" 4 "DEVICE_ROLE_FM_KEY" 3 "DEVICE_ROLE_DRIVER_KEY" 2 "DEVICE_ROLE_OWNER_KEY" 1 "DEVICE_ROLE_SERVICE_KEY" 0 "DEVICE_ROLE_NONE" ;
VAL_ 857 VCSEC_Device14AuthResponseTime 127 "SNA" ;
VAL_ 857 VCSEC_Device14Formfactor 19 "KEY_FORM_FACTOR_HARMONY_OS_NEXT_DEVICE" 18 "KEY_FORM_FACTOR_NFC_CARD_WATCHDATA_PLASTIC_CARD" 17 "KEY_FORM_FACTOR_APPLE_WATCH" 16 "KEY_FORM_FACTOR_NFC_CARD_IDEMIA_PLASTIC_CARD" 15 "KEY_FORM_FACTOR_NFC_CARD_IDEMIA_METAL_CARD" 14 "KEY_FORM_FACTOR_NFC_CARD_P71" 13 "KEY_FORM_FACTOR_3_BUTTON_GEN2_CAR_KEYFOB_P60_V3" 12 "KEY_FORM_FACTOR_3_BUTTON_GEN2_CAR_KEYFOB_P60_V2" 11 "KEY_FORM_FACTOR_5_BUTTON_GEN2_CAR_KEYFOB_P60" 10 "KEY_FORM_FACTOR_3_BUTTON_GEN2_CAR_KEYFOB_P60" 9 "KEY_FORM_FACTOR_CLOUD_KEY" 8 "KEY_FORM_FACTOR_3_BUTTON_BLE_CAR_KEYFOB_P60" 7 "KEY_FORM_FACTOR_ANDROID_DEVICE" 6 "KEY_FORM_FACTOR_IOS_DEVICE" 5 "KEY_FORM_FACTOR_BLE_AND_NFC_DEVICE" 4 "KEY_FORM_FACTOR_NFC_DEVICE" 3 "KEY_FORM_FACTOR_BLE_DEVICE" 2 "KEY_FORM_FACTOR_3_BUTTON_BLE_CAR_KEYFOB" 1 "KEY_FORM_FACTOR_NFC_CARD" 0 "KEY_FORM_FACTOR_UNKNOWN" ;
VAL_ 857 VCSEC_Device14Role 10 "DEVICE_ROLE_PREDELIVERY_KEY" 9 "DEVICE_ROLE_RIDER_KEY" 8 "DEVICE_ROLE_GUEST_KEY" 7 "DEVICE_ROLE_SERVICE_TECH_KEY" 6 "DEVICE_ROLE_CHARGING_MANAGER_KEY" 5 "DEVICE_ROLE_VEHICLE_MONITOR_KEY" 4 "DEVICE_ROLE_FM_KEY" 3 "DEVICE_ROLE_DRIVER_KEY" 2 "DEVICE_ROLE_OWNER_KEY" 1 "DEVICE_ROLE_SERVICE_KEY" 0 "DEVICE_ROLE_NONE" ;
VAL_ 857 VCSEC_Device15AuthResponseTime 127 "SNA" ;
VAL_ 857 VCSEC_Device15Formfactor 19 "KEY_FORM_FACTOR_HARMONY_OS_NEXT_DEVICE" 18 "KEY_FORM_FACTOR_NFC_CARD_WATCHDATA_PLASTIC_CARD" 17 "KEY_FORM_FACTOR_APPLE_WATCH" 16 "KEY_FORM_FACTOR_NFC_CARD_IDEMIA_PLASTIC_CARD" 15 "KEY_FORM_FACTOR_NFC_CARD_IDEMIA_METAL_CARD" 14 "KEY_FORM_FACTOR_NFC_CARD_P71" 13 "KEY_FORM_FACTOR_3_BUTTON_GEN2_CAR_KEYFOB_P60_V3" 12 "KEY_FORM_FACTOR_3_BUTTON_GEN2_CAR_KEYFOB_P60_V2" 11 "KEY_FORM_FACTOR_5_BUTTON_GEN2_CAR_KEYFOB_P60" 10 "KEY_FORM_FACTOR_3_BUTTON_GEN2_CAR_KEYFOB_P60" 9 "KEY_FORM_FACTOR_CLOUD_KEY" 8 "KEY_FORM_FACTOR_3_BUTTON_BLE_CAR_KEYFOB_P60" 7 "KEY_FORM_FACTOR_ANDROID_DEVICE" 6 "KEY_FORM_FACTOR_IOS_DEVICE" 5 "KEY_FORM_FACTOR_BLE_AND_NFC_DEVICE" 4 "KEY_FORM_FACTOR_NFC_DEVICE" 3 "KEY_FORM_FACTOR_BLE_DEVICE" 2 "KEY_FORM_FACTOR_3_BUTTON_BLE_CAR_KEYFOB" 1 "KEY_FORM_FACTOR_NFC_CARD" 0 "KEY_FORM_FACTOR_UNKNOWN" ;
VAL_ 857 VCSEC_Device15Role 10 "DEVICE_ROLE_PREDELIVERY_KEY" 9 "DEVICE_ROLE_RIDER_KEY" 8 "DEVICE_ROLE_GUEST_KEY" 7 "DEVICE_ROLE_SERVICE_TECH_KEY" 6 "DEVICE_ROLE_CHARGING_MANAGER_KEY" 5 "DEVICE_ROLE_VEHICLE_MONITOR_KEY" 4 "DEVICE_ROLE_FM_KEY" 3 "DEVICE_ROLE_DRIVER_KEY" 2 "DEVICE_ROLE_OWNER_KEY" 1 "DEVICE_ROLE_SERVICE_KEY" 0 "DEVICE_ROLE_NONE" ;
VAL_ 857 VCSEC_Device16AuthResponseTime 127 "SNA" ;
VAL_ 857 VCSEC_Device16Formfactor 19 "KEY_FORM_FACTOR_HARMONY_OS_NEXT_DEVICE" 18 "KEY_FORM_FACTOR_NFC_CARD_WATCHDATA_PLASTIC_CARD" 17 "KEY_FORM_FACTOR_APPLE_WATCH" 16 "KEY_FORM_FACTOR_NFC_CARD_IDEMIA_PLASTIC_CARD" 15 "KEY_FORM_FACTOR_NFC_CARD_IDEMIA_METAL_CARD" 14 "KEY_FORM_FACTOR_NFC_CARD_P71" 13 "KEY_FORM_FACTOR_3_BUTTON_GEN2_CAR_KEYFOB_P60_V3" 12 "KEY_FORM_FACTOR_3_BUTTON_GEN2_CAR_KEYFOB_P60_V2" 11 "KEY_FORM_FACTOR_5_BUTTON_GEN2_CAR_KEYFOB_P60" 10 "KEY_FORM_FACTOR_3_BUTTON_GEN2_CAR_KEYFOB_P60" 9 "KEY_FORM_FACTOR_CLOUD_KEY" 8 "KEY_FORM_FACTOR_3_BUTTON_BLE_CAR_KEYFOB_P60" 7 "KEY_FORM_FACTOR_ANDROID_DEVICE" 6 "KEY_FORM_FACTOR_IOS_DEVICE" 5 "KEY_FORM_FACTOR_BLE_AND_NFC_DEVICE" 4 "KEY_FORM_FACTOR_NFC_DEVICE" 3 "KEY_FORM_FACTOR_BLE_DEVICE" 2 "KEY_FORM_FACTOR_3_BUTTON_BLE_CAR_KEYFOB" 1 "KEY_FORM_FACTOR_NFC_CARD" 0 "KEY_FORM_FACTOR_UNKNOWN" ;
VAL_ 857 VCSEC_Device16Role 10 "DEVICE_ROLE_PREDELIVERY_KEY" 9 "DEVICE_ROLE_RIDER_KEY" 8 "DEVICE_ROLE_GUEST_KEY" 7 "DEVICE_ROLE_SERVICE_TECH_KEY" 6 "DEVICE_ROLE_CHARGING_MANAGER_KEY" 5 "DEVICE_ROLE_VEHICLE_MONITOR_KEY" 4 "DEVICE_ROLE_FM_KEY" 3 "DEVICE_ROLE_DRIVER_KEY" 2 "DEVICE_ROLE_OWNER_KEY" 1 "DEVICE_ROLE_SERVICE_KEY" 0 "DEVICE_ROLE_NONE" ;
VAL_ 857 VCSEC_Device17AuthResponseTime 127 "SNA" ;
VAL_ 857 VCSEC_Device17Formfactor 19 "KEY_FORM_FACTOR_HARMONY_OS_NEXT_DEVICE" 18 "KEY_FORM_FACTOR_NFC_CARD_WATCHDATA_PLASTIC_CARD" 17 "KEY_FORM_FACTOR_APPLE_WATCH" 16 "KEY_FORM_FACTOR_NFC_CARD_IDEMIA_PLASTIC_CARD" 15 "KEY_FORM_FACTOR_NFC_CARD_IDEMIA_METAL_CARD" 14 "KEY_FORM_FACTOR_NFC_CARD_P71" 13 "KEY_FORM_FACTOR_3_BUTTON_GEN2_CAR_KEYFOB_P60_V3" 12 "KEY_FORM_FACTOR_3_BUTTON_GEN2_CAR_KEYFOB_P60_V2" 11 "KEY_FORM_FACTOR_5_BUTTON_GEN2_CAR_KEYFOB_P60" 10 "KEY_FORM_FACTOR_3_BUTTON_GEN2_CAR_KEYFOB_P60" 9 "KEY_FORM_FACTOR_CLOUD_KEY" 8 "KEY_FORM_FACTOR_3_BUTTON_BLE_CAR_KEYFOB_P60" 7 "KEY_FORM_FACTOR_ANDROID_DEVICE" 6 "KEY_FORM_FACTOR_IOS_DEVICE" 5 "KEY_FORM_FACTOR_BLE_AND_NFC_DEVICE" 4 "KEY_FORM_FACTOR_NFC_DEVICE" 3 "KEY_FORM_FACTOR_BLE_DEVICE" 2 "KEY_FORM_FACTOR_3_BUTTON_BLE_CAR_KEYFOB" 1 "KEY_FORM_FACTOR_NFC_CARD" 0 "KEY_FORM_FACTOR_UNKNOWN" ;
VAL_ 857 VCSEC_Device17Role 10 "DEVICE_ROLE_PREDELIVERY_KEY" 9 "DEVICE_ROLE_RIDER_KEY" 8 "DEVICE_ROLE_GUEST_KEY" 7 "DEVICE_ROLE_SERVICE_TECH_KEY" 6 "DEVICE_ROLE_CHARGING_MANAGER_KEY" 5 "DEVICE_ROLE_VEHICLE_MONITOR_KEY" 4 "DEVICE_ROLE_FM_KEY" 3 "DEVICE_ROLE_DRIVER_KEY" 2 "DEVICE_ROLE_OWNER_KEY" 1 "DEVICE_ROLE_SERVICE_KEY" 0 "DEVICE_ROLE_NONE" ;
VAL_ 857 VCSEC_Device18AuthResponseTime 127 "SNA" ;
VAL_ 857 VCSEC_Device18Formfactor 19 "KEY_FORM_FACTOR_HARMONY_OS_NEXT_DEVICE" 18 "KEY_FORM_FACTOR_NFC_CARD_WATCHDATA_PLASTIC_CARD" 17 "KEY_FORM_FACTOR_APPLE_WATCH" 16 "KEY_FORM_FACTOR_NFC_CARD_IDEMIA_PLASTIC_CARD" 15 "KEY_FORM_FACTOR_NFC_CARD_IDEMIA_METAL_CARD" 14 "KEY_FORM_FACTOR_NFC_CARD_P71" 13 "KEY_FORM_FACTOR_3_BUTTON_GEN2_CAR_KEYFOB_P60_V3" 12 "KEY_FORM_FACTOR_3_BUTTON_GEN2_CAR_KEYFOB_P60_V2" 11 "KEY_FORM_FACTOR_5_BUTTON_GEN2_CAR_KEYFOB_P60" 10 "KEY_FORM_FACTOR_3_BUTTON_GEN2_CAR_KEYFOB_P60" 9 "KEY_FORM_FACTOR_CLOUD_KEY" 8 "KEY_FORM_FACTOR_3_BUTTON_BLE_CAR_KEYFOB_P60" 7 "KEY_FORM_FACTOR_ANDROID_DEVICE" 6 "KEY_FORM_FACTOR_IOS_DEVICE" 5 "KEY_FORM_FACTOR_BLE_AND_NFC_DEVICE" 4 "KEY_FORM_FACTOR_NFC_DEVICE" 3 "KEY_FORM_FACTOR_BLE_DEVICE" 2 "KEY_FORM_FACTOR_3_BUTTON_BLE_CAR_KEYFOB" 1 "KEY_FORM_FACTOR_NFC_CARD" 0 "KEY_FORM_FACTOR_UNKNOWN" ;
VAL_ 857 VCSEC_Device18Role 10 "DEVICE_ROLE_PREDELIVERY_KEY" 9 "DEVICE_ROLE_RIDER_KEY" 8 "DEVICE_ROLE_GUEST_KEY" 7 "DEVICE_ROLE_SERVICE_TECH_KEY" 6 "DEVICE_ROLE_CHARGING_MANAGER_KEY" 5 "DEVICE_ROLE_VEHICLE_MONITOR_KEY" 4 "DEVICE_ROLE_FM_KEY" 3 "DEVICE_ROLE_DRIVER_KEY" 2 "DEVICE_ROLE_OWNER_KEY" 1 "DEVICE_ROLE_SERVICE_KEY" 0 "DEVICE_ROLE_NONE" ;
VAL_ 857 VCSEC_Device19AuthResponseTime 127 "SNA" ;
VAL_ 857 VCSEC_Device19Formfactor 19 "KEY_FORM_FACTOR_HARMONY_OS_NEXT_DEVICE" 18 "KEY_FORM_FACTOR_NFC_CARD_WATCHDATA_PLASTIC_CARD" 17 "KEY_FORM_FACTOR_APPLE_WATCH" 16 "KEY_FORM_FACTOR_NFC_CARD_IDEMIA_PLASTIC_CARD" 15 "KEY_FORM_FACTOR_NFC_CARD_IDEMIA_METAL_CARD" 14 "KEY_FORM_FACTOR_NFC_CARD_P71" 13 "KEY_FORM_FACTOR_3_BUTTON_GEN2_CAR_KEYFOB_P60_V3" 12 "KEY_FORM_FACTOR_3_BUTTON_GEN2_CAR_KEYFOB_P60_V2" 11 "KEY_FORM_FACTOR_5_BUTTON_GEN2_CAR_KEYFOB_P60" 10 "KEY_FORM_FACTOR_3_BUTTON_GEN2_CAR_KEYFOB_P60" 9 "KEY_FORM_FACTOR_CLOUD_KEY" 8 "KEY_FORM_FACTOR_3_BUTTON_BLE_CAR_KEYFOB_P60" 7 "KEY_FORM_FACTOR_ANDROID_DEVICE" 6 "KEY_FORM_FACTOR_IOS_DEVICE" 5 "KEY_FORM_FACTOR_BLE_AND_NFC_DEVICE" 4 "KEY_FORM_FACTOR_NFC_DEVICE" 3 "KEY_FORM_FACTOR_BLE_DEVICE" 2 "KEY_FORM_FACTOR_3_BUTTON_BLE_CAR_KEYFOB" 1 "KEY_FORM_FACTOR_NFC_CARD" 0 "KEY_FORM_FACTOR_UNKNOWN" ;
VAL_ 857 VCSEC_Device19Role 10 "DEVICE_ROLE_PREDELIVERY_KEY" 9 "DEVICE_ROLE_RIDER_KEY" 8 "DEVICE_ROLE_GUEST_KEY" 7 "DEVICE_ROLE_SERVICE_TECH_KEY" 6 "DEVICE_ROLE_CHARGING_MANAGER_KEY" 5 "DEVICE_ROLE_VEHICLE_MONITOR_KEY" 4 "DEVICE_ROLE_FM_KEY" 3 "DEVICE_ROLE_DRIVER_KEY" 2 "DEVICE_ROLE_OWNER_KEY" 1 "DEVICE_ROLE_SERVICE_KEY" 0 "DEVICE_ROLE_NONE" ;
VAL_ 1066 VCSEC_TPMSSensorState0 5 "SENSOR_WAIT_FOR_NEXT_ADV" 4 "SENSOR_DISCONNECTING" 3 "SENSOR_CONNECTED" 2 "SENSOR_WAIT_FOR_CONN" 1 "SENSOR_WAIT_FOR_ADV" 0 "SENSOR_NOT_PAIRED" ;
VAL_ 1066 VCSEC_TPMSConnectionTypeCurrent0 3 "CONNECTIONTYPE_FAST_SLAVE_LATENCY" 2 "CONNECTIONTYPE_UNKNOWN" 1 "CONNECTIONTYPE_SLOW" 0 "CONNECTIONTYPE_FAST" ;
VAL_ 1066 VCSEC_TPMSConnectionTypeDesired0 3 "CONNECTIONTYPE_FAST_SLAVE_LATENCY" 2 "CONNECTIONTYPE_UNKNOWN" 1 "CONNECTIONTYPE_SLOW" 0 "CONNECTIONTYPE_FAST" ;
VAL_ 1066 VCSEC_TPMSSensorState1 5 "SENSOR_WAIT_FOR_NEXT_ADV" 4 "SENSOR_DISCONNECTING" 3 "SENSOR_CONNECTED" 2 "SENSOR_WAIT_FOR_CONN" 1 "SENSOR_WAIT_FOR_ADV" 0 "SENSOR_NOT_PAIRED" ;
VAL_ 1066 VCSEC_TPMSConnectionTypeCurrent1 3 "CONNECTIONTYPE_FAST_SLAVE_LATENCY" 2 "CONNECTIONTYPE_UNKNOWN" 1 "CONNECTIONTYPE_SLOW" 0 "CONNECTIONTYPE_FAST" ;
VAL_ 1066 VCSEC_TPMSConnectionTypeDesired1 3 "CONNECTIONTYPE_FAST_SLAVE_LATENCY" 2 "CONNECTIONTYPE_UNKNOWN" 1 "CONNECTIONTYPE_SLOW" 0 "CONNECTIONTYPE_FAST" ;
VAL_ 1066 VCSEC_TPMSSensorState2 5 "SENSOR_WAIT_FOR_NEXT_ADV" 4 "SENSOR_DISCONNECTING" 3 "SENSOR_CONNECTED" 2 "SENSOR_WAIT_FOR_CONN" 1 "SENSOR_WAIT_FOR_ADV" 0 "SENSOR_NOT_PAIRED" ;
VAL_ 1066 VCSEC_TPMSConnectionTypeCurrent2 3 "CONNECTIONTYPE_FAST_SLAVE_LATENCY" 2 "CONNECTIONTYPE_UNKNOWN" 1 "CONNECTIONTYPE_SLOW" 0 "CONNECTIONTYPE_FAST" ;
VAL_ 1066 VCSEC_TPMSConnectionTypeDesired2 3 "CONNECTIONTYPE_FAST_SLAVE_LATENCY" 2 "CONNECTIONTYPE_UNKNOWN" 1 "CONNECTIONTYPE_SLOW" 0 "CONNECTIONTYPE_FAST" ;
VAL_ 1066 VCSEC_TPMSSensorState3 5 "SENSOR_WAIT_FOR_NEXT_ADV" 4 "SENSOR_DISCONNECTING" 3 "SENSOR_CONNECTED" 2 "SENSOR_WAIT_FOR_CONN" 1 "SENSOR_WAIT_FOR_ADV" 0 "SENSOR_NOT_PAIRED" ;
VAL_ 1066 VCSEC_TPMSConnectionTypeCurrent3 3 "CONNECTIONTYPE_FAST_SLAVE_LATENCY" 2 "CONNECTIONTYPE_UNKNOWN" 1 "CONNECTIONTYPE_SLOW" 0 "CONNECTIONTYPE_FAST" ;
VAL_ 1066 VCSEC_TPMSConnectionTypeDesired3 3 "CONNECTIONTYPE_FAST_SLAVE_LATENCY" 2 "CONNECTIONTYPE_UNKNOWN" 1 "CONNECTIONTYPE_SLOW" 0 "CONNECTIONTYPE_FAST" ;
VAL_ 1066 VCSEC_TPMSSensorPresence0 2 "PRESENT" 1 "NOT_PRESENT" 0 "NOT_PAIRED" ;
VAL_ 1066 VCSEC_TPMSSensorPresence1 2 "PRESENT" 1 "NOT_PRESENT" 0 "NOT_PAIRED" ;
VAL_ 1066 VCSEC_TPMSSensorPresence2 2 "PRESENT" 1 "NOT_PRESENT" 0 "NOT_PAIRED" ;
VAL_ 1066 VCSEC_TPMSSensorPresence3 2 "PRESENT" 1 "NOT_PRESENT" 0 "NOT_PAIRED" ;
VAL_ 602 VCSEC_TPMSDisplayPressureFL 255 "SNA" 254 "OVER_RANGE" ;
VAL_ 602 VCSEC_TPMSDisplayPressureFR 255 "SNA" 254 "OVER_RANGE" ;
VAL_ 602 VCSEC_TPMSDisplayPressureRL 255 "SNA" 254 "OVER_RANGE" ;
VAL_ 602 VCSEC_TPMSDisplayPressureRR 255 "SNA" 254 "OVER_RANGE" ;
VAL_ 602 VCSEC_TPMSTellTale 2 "TPMS_TELLTALE_FLASHING" 1 "TPMS_TELLTALE_SOLID" 0 "TPMS_TELLTALE_OFF" ;
VAL_ 602 VCSEC_TPMSDisplaySoftWarningIndi 1 "TPMS_PRESSUREWARNING_INDICATED" 0 "TPMS_PRESSUREWARNING_NOT_INDICATED" ;
VAL_ 602 VCSEC_TPMSDisplaySoftWarnin_0001 1 "TPMS_PRESSUREWARNING_INDICATED" 0 "TPMS_PRESSUREWARNING_NOT_INDICATED" ;
VAL_ 602 VCSEC_TPMSDisplaySoftWarnin_0002 1 "TPMS_PRESSUREWARNING_INDICATED" 0 "TPMS_PRESSUREWARNING_NOT_INDICATED" ;
VAL_ 602 VCSEC_TPMSDisplaySoftWarnin_0003 1 "TPMS_PRESSUREWARNING_INDICATED" 0 "TPMS_PRESSUREWARNING_NOT_INDICATED" ;
VAL_ 602 VCSEC_TPMSDisplayHardWarningIndi 1 "TPMS_PRESSUREWARNING_INDICATED" 0 "TPMS_PRESSUREWARNING_NOT_INDICATED" ;
VAL_ 602 VCSEC_TPMSDisplayHardWarnin_0001 1 "TPMS_PRESSUREWARNING_INDICATED" 0 "TPMS_PRESSUREWARNING_NOT_INDICATED" ;
VAL_ 602 VCSEC_TPMSDisplayHardWarnin_0002 1 "TPMS_PRESSUREWARNING_INDICATED" 0 "TPMS_PRESSUREWARNING_NOT_INDICATED" ;
VAL_ 602 VCSEC_TPMSDisplayHardWarnin_0003 1 "TPMS_PRESSUREWARNING_INDICATED" 0 "TPMS_PRESSUREWARNING_NOT_INDICATED" ;
VAL_ 825 VCSEC_authRejectionReason 5 "AUTHENTICATIONREJECTION_DEVICE_NOT_UNLOCKED_ON_WRIST" 4 "AUTHENTICATIONREJECTION_PASSIVE_DISABLED_AUTOMATION" 3 "AUTHENTICATIONREJECTION_NO_TOKEN" 2 "AUTHENTICATIONREJECTION_PASSIVE_DISABLED" 1 "AUTHENTICATIONREJECTION_DEVICE_STATIONARY" 0 "AUTHENTICATIONREJECTION_NONE" ;
VAL_ 825 VCSEC_operationMode 2 "OPERATION_MODE_FLEET" 1 "OPERATION_MODE_OWNER" 0 "OPERATION_MODE_UNKNOWN" ;
VAL_ 825 VCSEC_vehicleLockStatus 15 "LOCK_STATUS_PASSIVE_INTERNAL_LOCKED" 14 "LOCK_STATUS_PASSIVE_INTERNAL_UNLOCKED" 13 "LOCK_STATUS_CRASH_UNLOCKED" 12 "LOCK_STATUS_ACTIVE_REMOTE_LOCKED" 11 "LOCK_STATUS_ACTIVE_REMOTE_UNLOCKED" 10 "LOCK_STATUS_ACTIVE_UI_LOCKED" 9 "LOCK_STATUS_ACTIVE_UI_UNLOCKED" 8 "LOCK_STATUS_ACTIVE_BLE_LOCKED" 7 "LOCK_STATUS_ACTIVE_BLE_UNLOCKED" 6 "LOCK_STATUS_ACTIVE_SELECTIVE_UNLOCKED" 5 "LOCK_STATUS_PASSIVE_BLE_LOCKED" 4 "LOCK_STATUS_PASSIVE_BLE_UNLOCKED" 3 "LOCK_STATUS_PASSIVE_SELECTIVE_UNLOCKED" 2 "LOCK_STATUS_ACTIVE_NFC_LOCKED" 1 "LOCK_STATUS_ACTIVE_NFC_UNLOCKED" 0 "LOCK_STATUS_SNA" ;
VAL_ 825 VCSEC_authenticationStatus 2 "AUTHENTICATION_AUTHENTICATED_FOR_DRIVE" 1 "AUTHENTICATION_AUTHENTICATED_FOR_UNLOCK" 0 "AUTHENTICATION_NONE" ;
VAL_ 825 VCSEC_chargePortLockStatus 1 "CLOSURE_LOCKED" 0 "CLOSURE_UNLOCKED" ;
VAL_ 825 VCSEC_leftFrontLockStatus 1 "CLOSURE_LOCKED" 0 "CLOSURE_UNLOCKED" ;
VAL_ 825 VCSEC_leftRearLockStatus 1 "CLOSURE_LOCKED" 0 "CLOSURE_UNLOCKED" ;
VAL_ 825 VCSEC_rightFrontLockStatus 1 "CLOSURE_LOCKED" 0 "CLOSURE_UNLOCKED" ;
VAL_ 825 VCSEC_rightRearLockStatus 1 "CLOSURE_LOCKED" 0 "CLOSURE_UNLOCKED" ;
VAL_ 825 VCSEC_trunkLockStatus 1 "CLOSURE_LOCKED" 0 "CLOSURE_UNLOCKED" ;
VAL_ 825 VCSEC_lockRequestType 21 "LOCK_REQUEST_KEYFOB_OPEN_DOOR_REQUEST" 20 "LOCK_REQUEST_PASSIVE_AUTO_PRESENT_DOOR_REQUEST" 19 "LOCK_REQUEST_PASSIVE_INTERNAL_LOCK_PROMOTION" 18 "LOCK_REQUEST_ACTIVE_BLE_LOCK" 17 "LOCK_REQUEST_ACTIVE_BLE_UNLOCK" 16 "LOCK_REQUEST_ACTIVE_NFC_LOCK" 15 "LOCK_REQUEST_ACTIVE_NFC_UNLOCK" 14 "LOCK_REQUEST_ACTIVE_REMOTE_LOCK" 13 "LOCK_REQUEST_ACTIVE_REMOTE_UNLOCK" 12 "LOCK_REQUEST_ACTIVE_UI_BUTTON_LOCK" 11 "LOCK_REQUEST_ACTIVE_UI_BUTTON_UNLOCK" 10 "LOCK_REQUEST_CRASH_UNLOCK" 9 "LOCK_REQUEST_PASSIVE_BLE_LOCK" 8 "LOCK_REQUEST_PASSIVE_BLE_INTERIOR_HANDLE_UNLOCK" 7 "LOCK_REQUEST_PASSIVE_BLE_EXTERIOR_HANDLE_UNLOCK" 6 "LOCK_REQUEST_PASSIVE_BLE_EXTERIOR_CHARGEHANDLEBUTTON_UNLOCK" 5 "LOCK_REQUEST_PASSIVE_BLE_WALKUP_UNLOCK" 4 "LOCK_REQUEST_PASSIVE_DRIVE_AWAY_LOCK" 3 "LOCK_REQUEST_PASSIVE_INTERNAL_HANDLE_UNLOCK" 2 "LOCK_REQUEST_PASSIVE_PARKBUTTON_UNLOCK" 1 "LOCK_REQUEST_PASSIVE_SHIFT_TO_P_UNLOCK" 0 "LOCK_REQUEST_NONE" ;
VAL_ 825 VCSEC_summonRequest 5 "SUMMON_REQUEST_SNA" 4 "SUMMON_REQUEST_STOP" 3 "SUMMON_REQUEST_BACKWARD" 2 "SUMMON_REQUEST_FORWARD" 1 "SUMMON_REQUEST_PRIME" 0 "SUMMON_REQUEST_IDLE" ;
VAL_ 825 VCSEC_3rdPartyPLGRequest 3 "CLOSURE_REQUEST_SNA" 2 "CLOSURE_REQUEST_STOP" 1 "CLOSURE_REQUEST_MOVE" 0 "CLOSURE_REQUEST_NONE" ;
VAL_ 825 VCSEC_3rdPartyFrunkPLGRequest 3 "CLOSURE_REQUEST_SNA" 2 "CLOSURE_REQUEST_STOP" 1 "CLOSURE_REQUEST_MOVE" 0 "CLOSURE_REQUEST_NONE" ;
VAL_ 825 VCSEC_MCUCommandType 5 "MCU_COMMAND_COMMAND5" 4 "MCU_COMMAND_COMMAND4" 3 "MCU_COMMAND_COMMAND3" 2 "MCU_COMMAND_REMOTE_START" 1 "MCU_COMMAND_REMOTE_UNLOCK" 0 "MCU_COMMAND_NONE" ;
VAL_ 825 VCSEC_frunkLockStatus 1 "CLOSURE_LOCKED" 0 "CLOSURE_UNLOCKED" ;
VAL_ 825 VCSEC_alarmStatus 15 "ALARM_STATUS_SNA" 7 "ALARM_STATUS_DEFAULT" 6 "ALARM_STATUS_IMMINENT" 5 "ALARM_STATUS_TRIGGERED_FLASH_INACTIVE" 4 "ALARM_STATUS_ERROR" 3 "ALARM_STATUS_TRIGGERED_FLASH_ACTIVE" 2 "ALARM_STATUS_PARTIAL_ARMED" 1 "ALARM_STATUS_ARMED" 0 "ALARM_STATUS_DISARMED" ;
VAL_ 825 VCSEC_immobilizerState 6 "IMMOBILIZER_STATE_IMMOBILIZED" 5 "IMMOBILIZER_STATE_SEND_NO_GO_AUTH_RESPONSE" 4 "IMMOBILIZER_STATE_SEND_AUTH_RESPONSE" 3 "IMMOBILIZER_STATE_ENCRYPT" 2 "IMMOBILIZER_STATE_ENCRYPT_BEGIN" 1 "IMMOBILIZER_STATE_PREPARE" 0 "IMMOBILIZER_STATE_IDLE" ;
VAL_ 825 VCSEC_lockIndicationRequest 4 "INDICATION_HOLD" 3 "INDICATION_TRIPLE" 2 "INDICATION_DOUBLE" 1 "INDICATION_SINGLE" 0 "INDICATION_NONE_SNA" ;
VAL_ 825 VCSEC_simpleLockStatus 2 "SIMPLE_LOCK_STATUS_LOCKED" 1 "SIMPLE_LOCK_STATUS_UNLOCKED" 0 "SIMPLE_LOCK_STATUS_SNA" ;
VAL_ 825 VCSEC_keyChannelIndexed 15 "SNA" ;
VAL_ 825 VCSEC_remoteStartActive 3 "VCSEC_REMOTE_START_TYPE_SIGNED_COMMAND_PIN_REQUIRED" 2 "VCSEC_REMOTE_START_TYPE_SIGNED_COMMAND" 1 "VCSEC_REMOTE_START_TYPE_LEGACY" 0 "VCSEC_REMOTE_START_TYPE_NONE" ;
VAL_ 793 VCSEC_infoIndex 255 "END" 41 "SUBCOMPONENT14" 40 "SUBCOMPONENT13" 39 "SUBCOMPONENT12" 38 "SUBCOMPONENT11" 37 "SUBCOMPONENT10" 36 "SUBCOMPONENT9" 35 "SUBCOMPONENT8" 34 "SUBCOMPONENT7" 33 "SUBCOMPONENT6" 32 "SUBCOMPONENT5" 31 "SUBCOMPONENT4" 24 "SUBCOMPONENT3" 23 "SUBCOMPONENT2" 20 "UDS_PROTOCOL_BOOTCRC" 19 "VERSION_DEPRECATED" 18 "BOOTLOADER_GITHASH" 17 "APP_GITHASH" 16 "SUBCOMPONENT1" 15 "BOOTLOADER_CRC" 14 "BOOTLOADER_SVN" 13 "APP_CRC" 11 "PCBAID_ASSYID_USAGEID" 10 "BUILD_HWID_COMPONENTID" 9 "DEPRECATED_9" 8 "DEPRECATED_8" 7 "DEPRECATED_7" 6 "DEPRECATED_6" 5 "DEPRECATED_5" 4 "DEPRECATED_4" 3 "DEPRECATED_3" 2 "DEPRECATED_2" 1 "DEPRECATED_1" 0 "DEPRECATED_0" ;
VAL_ 793 VCSEC_infoBuildType 4 "INFO_MFG_BUILD" 3 "INFO_TRACEABLE_CI_BUILD" 2 "INFO_LOCAL_BUILD" 1 "INFO_PLATFORM_BUILD" 0 "INFO_UNKNOWN_BUILD" ;
VAL_ 793 VCSEC_infoAssemblyId 255 "ASSEMBLY_SNA" 1 "ASSEMBLY1" ;
VAL_ 505 VCSEC_chargePortRequest 3 "REQUEST_SNA" 2 "REQUEST_CLOSE" 1 "REQUEST_OPEN" 0 "REQUEST_NONE" ;
VAL_ 505 VCSEC_frontLeftClosureRequest 6 "POWERED_CLOSURE_REQUEST_CLOSE" 5 "POWERED_CLOSURE_REQUEST_OPEN_REDUCED" 4 "POWERED_CLOSURE_REQUEST_QUICK_OPEN" 3 "POWERED_CLOSURE_REQUEST_OPEN" 2 "POWERED_CLOSURE_REQUEST_STOP" 1 "POWERED_CLOSURE_REQUEST_MOVE" 0 "POWERED_CLOSURE_REQUEST_NONE" ;
VAL_ 505 VCSEC_frontRightClosureRequest 6 "POWERED_CLOSURE_REQUEST_CLOSE" 5 "POWERED_CLOSURE_REQUEST_OPEN_REDUCED" 4 "POWERED_CLOSURE_REQUEST_QUICK_OPEN" 3 "POWERED_CLOSURE_REQUEST_OPEN" 2 "POWERED_CLOSURE_REQUEST_STOP" 1 "POWERED_CLOSURE_REQUEST_MOVE" 0 "POWERED_CLOSURE_REQUEST_NONE" ;
VAL_ 505 VCSEC_rearLeftClosureRequest 6 "POWERED_CLOSURE_REQUEST_CLOSE" 5 "POWERED_CLOSURE_REQUEST_OPEN_REDUCED" 4 "POWERED_CLOSURE_REQUEST_QUICK_OPEN" 3 "POWERED_CLOSURE_REQUEST_OPEN" 2 "POWERED_CLOSURE_REQUEST_STOP" 1 "POWERED_CLOSURE_REQUEST_MOVE" 0 "POWERED_CLOSURE_REQUEST_NONE" ;
VAL_ 505 VCSEC_rearRightClosureRequest 6 "POWERED_CLOSURE_REQUEST_CLOSE" 5 "POWERED_CLOSURE_REQUEST_OPEN_REDUCED" 4 "POWERED_CLOSURE_REQUEST_QUICK_OPEN" 3 "POWERED_CLOSURE_REQUEST_OPEN" 2 "POWERED_CLOSURE_REQUEST_STOP" 1 "POWERED_CLOSURE_REQUEST_MOVE" 0 "POWERED_CLOSURE_REQUEST_NONE" ;
VAL_ 505 VCSEC_rearTrunkClosureRequest 6 "POWERED_CLOSURE_REQUEST_CLOSE" 5 "POWERED_CLOSURE_REQUEST_OPEN_REDUCED" 4 "POWERED_CLOSURE_REQUEST_QUICK_OPEN" 3 "POWERED_CLOSURE_REQUEST_OPEN" 2 "POWERED_CLOSURE_REQUEST_STOP" 1 "POWERED_CLOSURE_REQUEST_MOVE" 0 "POWERED_CLOSURE_REQUEST_NONE" ;
VAL_ 505 VCSEC_frontLeftRequestReason 7 "POWERED_CLOSURE_REQUEST_TAP_TO_OPEN" 6 "POWERED_CLOSURE_REQUEST_REASON_UI_REQUEST" 5 "POWERED_CLOSURE_REQUEST_UI_STOP_ALL" 4 "POWERED_CLOSURE_REQUEST_KEYFOB_UNLOCK_OPEN" 3 "POWERED_CLOSURE_REQUEST_REASON_AUTO_PRESENT" 2 "POWERED_CLOSURE_REQUEST_REASON_CLOSE_ALL" 1 "POWERED_CLOSURE_REQUEST_REASON_RKE" 0 "POWERED_CLOSURE_REQUEST_REASON_NONE" ;
VAL_ 505 VCSEC_frontRightRequestReason 7 "POWERED_CLOSURE_REQUEST_TAP_TO_OPEN" 6 "POWERED_CLOSURE_REQUEST_REASON_UI_REQUEST" 5 "POWERED_CLOSURE_REQUEST_UI_STOP_ALL" 4 "POWERED_CLOSURE_REQUEST_KEYFOB_UNLOCK_OPEN" 3 "POWERED_CLOSURE_REQUEST_REASON_AUTO_PRESENT" 2 "POWERED_CLOSURE_REQUEST_REASON_CLOSE_ALL" 1 "POWERED_CLOSURE_REQUEST_REASON_RKE" 0 "POWERED_CLOSURE_REQUEST_REASON_NONE" ;
VAL_ 505 VCSEC_rearLeftRequestReason 7 "POWERED_CLOSURE_REQUEST_TAP_TO_OPEN" 6 "POWERED_CLOSURE_REQUEST_REASON_UI_REQUEST" 5 "POWERED_CLOSURE_REQUEST_UI_STOP_ALL" 4 "POWERED_CLOSURE_REQUEST_KEYFOB_UNLOCK_OPEN" 3 "POWERED_CLOSURE_REQUEST_REASON_AUTO_PRESENT" 2 "POWERED_CLOSURE_REQUEST_REASON_CLOSE_ALL" 1 "POWERED_CLOSURE_REQUEST_REASON_RKE" 0 "POWERED_CLOSURE_REQUEST_REASON_NONE" ;
VAL_ 505 VCSEC_rearRightRequestReason 7 "POWERED_CLOSURE_REQUEST_TAP_TO_OPEN" 6 "POWERED_CLOSURE_REQUEST_REASON_UI_REQUEST" 5 "POWERED_CLOSURE_REQUEST_UI_STOP_ALL" 4 "POWERED_CLOSURE_REQUEST_KEYFOB_UNLOCK_OPEN" 3 "POWERED_CLOSURE_REQUEST_REASON_AUTO_PRESENT" 2 "POWERED_CLOSURE_REQUEST_REASON_CLOSE_ALL" 1 "POWERED_CLOSURE_REQUEST_REASON_RKE" 0 "POWERED_CLOSURE_REQUEST_REASON_NONE" ;
VAL_ 505 VCSEC_rearTrunkRequestReason 7 "POWERED_CLOSURE_REQUEST_TAP_TO_OPEN" 6 "POWERED_CLOSURE_REQUEST_REASON_UI_REQUEST" 5 "POWERED_CLOSURE_REQUEST_UI_STOP_ALL" 4 "POWERED_CLOSURE_REQUEST_KEYFOB_UNLOCK_OPEN" 3 "POWERED_CLOSURE_REQUEST_REASON_AUTO_PRESENT" 2 "POWERED_CLOSURE_REQUEST_REASON_CLOSE_ALL" 1 "POWERED_CLOSURE_REQUEST_REASON_RKE" 0 "POWERED_CLOSURE_REQUEST_REASON_NONE" ;
VAL_ 505 VCSEC_driveAttemptedWithoutAuth 10 "SHOW_B_PILLAR_NFC_CARD_TAP" 9 "SHOW_CENTER_NFC_CARD_TAP" 8 "SHOW_BRING_PHONE_CLOSER_BPILLAR_VARIANT" 7 "SHOW_BRING_PHONE_CLOSER_CENTER_VARIANT" 6 "SHOW_APP_DOWNLOAD_AND_PHONEKEY_PAIR_BPILLAR_VARIANT" 5 "SHOW_APP_DOWNLOAD_AND_PHONEKEY_PAIR_CENTER_VARIANT" 4 "SHOW_DEVICE_DISCONNECTED_GENERIC_BPILLAR_VARIANT" 3 "SHOW_DEVICE_DISCONNECTED_GENERIC_CENTER_VARIANT" 2 "SHOW_DEVICE_DISCONNECTED_IOS_BPILLAR_VARIANT" 1 "SHOW_DEVICE_DISCONNECTED_IOS_CENTER_VARIANT" 0 "NO_NFC_POPUP_DESIRED" ;
VAL_ 505 VCSEC_closeAllStatus 2 "CLOSEALL_STATE_CANCELABLE" 1 "CLOSEALL_STATE_AVAILABLE" 0 "CLOSEALL_STATE_NOT_AVAILABLE" ;
VAL_ 505 VCSEC_snapshotRequested 15 "EXTERNAL_THERMALS_HIGH" 14 "AUTO_FRUNK_FALSE_BEEP" 13 "AUTO_FRUNK" 12 "AUTHENTICATION_REJECTION_DEVICE_STATIONARY" 11 "AUTO_TRUNK" 10 "RSSI_NN_ALGO_FALSE_POSITIVE" 9 "RSSI_THRESHOLD_ALGO_FALSE_POSITIVE" 8 "RAW_RSSI_ECU_LOG_HANDLE_PULL" 7 "AUTO_TRUNK_FALSE_BEEP" 6 "UNASSIGNED_6" 5 "UNASSIGNED_5" 4 "AUTO_PRESENT_DOOR_CLOSE_WITHOUT_PEDESTRIAN_DETECTED" 3 "AUTO_PRESENT_DOOR_CLOSE_TIMEOUT" 2 "AUTHED_WITHOUT_HANDLE_PULL" 1 "HANDLE_PULL_WITHOUT_AUTH" 0 "NONE" ;
VAL_ 505 VCSEC_chargeportRequestReason 4 "VCSEC_CHARGEPORT_REQUEST_REASON_LONG_PULL_DOOR_HANDLE" 3 "VCSEC_CHARGEPORT_REQUEST_REASON_BLE_CHARGE_HANDLE" 2 "VCSEC_CHARGEPORT_REQUEST_REASON_UHF" 1 "VCSEC_CHARGEPORT_REQUEST_REASON_RKE" 0 "VCSEC_CHARGEPORT_REQUEST_REASON_NONE" ;
VAL_ 505 VCSEC_frontTrunkClosureRequest 6 "POWERED_CLOSURE_REQUEST_CLOSE" 5 "POWERED_CLOSURE_REQUEST_OPEN_REDUCED" 4 "POWERED_CLOSURE_REQUEST_QUICK_OPEN" 3 "POWERED_CLOSURE_REQUEST_OPEN" 2 "POWERED_CLOSURE_REQUEST_STOP" 1 "POWERED_CLOSURE_REQUEST_MOVE" 0 "POWERED_CLOSURE_REQUEST_NONE" ;
VAL_ 505 VCSEC_frontTrunkRequestReason 7 "POWERED_CLOSURE_REQUEST_TAP_TO_OPEN" 6 "POWERED_CLOSURE_REQUEST_REASON_UI_REQUEST" 5 "POWERED_CLOSURE_REQUEST_UI_STOP_ALL" 4 "POWERED_CLOSURE_REQUEST_KEYFOB_UNLOCK_OPEN" 3 "POWERED_CLOSURE_REQUEST_REASON_AUTO_PRESENT" 2 "POWERED_CLOSURE_REQUEST_REASON_CLOSE_ALL" 1 "POWERED_CLOSURE_REQUEST_REASON_RKE" 0 "POWERED_CLOSURE_REQUEST_REASON_NONE" ;
VAL_ 1850 VC_LVBMS_brickMeasurementsMultip 2 "Mux2" 1 "Mux1" 0 "Mux0" ;
VAL_ 1850 VC_LVBMS_brickVoltage1 8191 "SNA" ;
VAL_ 1850 VC_LVBMS_brickVoltage2 8191 "SNA" ;
VAL_ 1850 VC_LVBMS_brickVoltage3 8191 "SNA" ;
VAL_ 1850 VC_LVBMS_brickVoltage4 8191 "SNA" ;
VAL_ 1850 VC_LVBMS_brickBalancingAh1 16777215 "SNA" ;
VAL_ 1850 VC_LVBMS_brickBalancingAh2 16777215 "SNA" ;
VAL_ 1850 VC_LVBMS_brickBalancingState1 1 "LVBMS_BALANCING_STATE_ACTIVE" 0 "LVBMS_BALANCING_STATE_INACTIVE" ;
VAL_ 1850 VC_LVBMS_brickBalancingState2 1 "LVBMS_BALANCING_STATE_ACTIVE" 0 "LVBMS_BALANCING_STATE_INACTIVE" ;
VAL_ 1850 VC_LVBMS_brickBalancingAh3 16777215 "SNA" ;
VAL_ 1850 VC_LVBMS_brickBalancingAh4 16777215 "SNA" ;
VAL_ 1850 VC_LVBMS_brickBalancingState3 1 "LVBMS_BALANCING_STATE_ACTIVE" 0 "LVBMS_BALANCING_STATE_INACTIVE" ;
VAL_ 1850 VC_LVBMS_brickBalancingState4 1 "LVBMS_BALANCING_STATE_ACTIVE" 0 "LVBMS_BALANCING_STATE_INACTIVE" ;
